VERSION ""

NS_ :

BS_:

BU_: Turbocharger OnBoardDataLogger OffBoardDiagnosticTool2 OffBoardDiagnosticTool1 FileServer ParkingBrakeController SeatControl2 FanDriveController SteeringColumnUnit CommunicationUnitRadio CommunicationUnitSatellite CommunicationUnitCellular PropulsionBatteryCharger ChassisController2 ChassisController1 EngineValveControl AuxiliaryHeater2 AuxiliaryHeater1 ClutchUnit RampControl InformationSystem1 SuspensionSystemController2 OilSensor VehicleDynamicStability ExhaustEmissionController TransmissionDisplay2 TransmissionDisplay1 ClimateControl2 WaterPumpController RearAxleSteeringController LightingOperatorControl SeatController1 IgnitionController2 IgnitionController1 TirePressureController CabController2 CabController1 PneumaticSystemController SuspensionSystemController1 HydraulicPumpController EnduranceBrakingSystem RetarderExhaustEngine2 OnBoardDiagnosticUnit HeadwayController RetarderExhaustEngine1 CabDisplay1 ManagementComputer VirtualTerminal OffVehicleGateway PowerTakeOffFront HitchControl AuxiliaryValveControl BodyController TractorTrailerBridge1 StarterSystem ElectricalSystem VehicleSecurity VehicleNavigation AerodynamicControl ElectricalChargingSystem ClimateControl1 TripRecorder InstrumentCluster SuspensionDriveAxle2 SuspensionDriveAxle1 SuspensionSteerAxle SteeringController FuelSystem CruiseControl RetarderDriveline RetarderEngine BrakesDriveAxle2 BrakesDriveAxle1 BrakesSystemController BrakesSteerAxle AxleDrive2 AxleDrive1 AxleSteering PowerTakeOff ShiftConsoleSecondary ShiftConsolePrimary Transmission2 Transmission1 Engine2 Engine1

BO_ 2365401854 BJM7: 8 Vector__XXX
 SG_ Joystick7Button9PressedStatus : 62|2@1+ (1,0) [0|3] "" Vector__XXX
 SG_ Joystick7Button10PressedStatus : 60|2@1+ (1,0) [0|3] "" Vector__XXX
 SG_ Joystick7Button11PressedStatus : 58|2@1+ (1,0) [0|3] "" Vector__XXX
 SG_ Joystick7Button12PressedStatus : 56|2@1+ (1,0) [0|3] "" Vector__XXX
 SG_ Joystick7Button5PressedStatus : 54|2@1+ (1,0) [0|3] "" Vector__XXX
 SG_ Joystick7Button6PressedStatus : 52|2@1+ (1,0) [0|3] "" Vector__XXX
 SG_ Joystick7Button7PressedStatus : 50|2@1+ (1,0) [0|3] "" Vector__XXX
 SG_ Joystick7Button8PressedStatus : 48|2@1+ (1,0) [0|3] "" Vector__XXX
 SG_ Joystick7Button1PressedStatus : 46|2@1+ (1,0) [0|3] "" Vector__XXX
 SG_ Joystick7Button2PressedStatus : 44|2@1+ (1,0) [0|3] "" Vector__XXX
 SG_ Joystick7Button3PressedStatus : 42|2@1+ (1,0) [0|3] "" Vector__XXX
 SG_ Joystick7Button4PressedStatus : 40|2@1+ (1,0) [0|3] "" Vector__XXX
 SG_ Joystick7XAxisDetentPosStatus : 38|2@1+ (1,0) [0|3] "" Vector__XXX
 SG_ Joystick7YAxisDetentPosStatus : 36|2@1+ (1,0) [0|3] "" Vector__XXX
 SG_ Joystick7YAxisPos : 22|10@1+ (1,0) [0|102] "%" Vector__XXX
 SG_ Jystck7YAxsLvrFrwrdPstvPosStatus : 20|2@1+ (1,0) [0|3] "" Vector__XXX
 SG_ Jystck7YAxsLvrBckNgtivePosStatus : 18|2@1+ (1,0) [0|3] "" Vector__XXX
 SG_ Joystick7YAxisNeutralPosStatus : 16|2@1+ (1,0) [0|3] "" Vector__XXX
 SG_ Joystick7XAxisPos : 6|10@1+ (1,0) [0|102] "%" Vector__XXX
 SG_ Jystck7XAxsLvrRghtPstvePosStatus : 4|2@1+ (1,0) [0|3] "" Vector__XXX
 SG_ Jystck7XAxsLvrLftNgtivePosStatus : 2|2@1+ (1,0) [0|3] "" Vector__XXX
 SG_ Joystick7XAxisNeutralPosStatus : 0|2@1+ (1,0) [0|3] "" Vector__XXX

BO_ 2365402366 BJM6: 8 Vector__XXX
 SG_ Joystick6Button9PressedStatus : 62|2@1+ (1,0) [0|3] "" Vector__XXX
 SG_ Joystick6Button10PressedStatus : 60|2@1+ (1,0) [0|3] "" Vector__XXX
 SG_ Joystick6Button11PressedStatus : 58|2@1+ (1,0) [0|3] "" Vector__XXX
 SG_ Joystick6Button12PressedStatus : 56|2@1+ (1,0) [0|3] "" Vector__XXX
 SG_ Joystick6Button5PressedStatus : 54|2@1+ (1,0) [0|3] "" Vector__XXX
 SG_ Joystick6Button6PressedStatus : 52|2@1+ (1,0) [0|3] "" Vector__XXX
 SG_ Joystick6Button7PressedStatus : 50|2@1+ (1,0) [0|3] "" Vector__XXX
 SG_ Joystick6Button8PressedStatus : 48|2@1+ (1,0) [0|3] "" Vector__XXX
 SG_ Joystick6Button1PressedStatus : 46|2@1+ (1,0) [0|3] "" Vector__XXX
 SG_ Joystick6Button2PressedStatus : 44|2@1+ (1,0) [0|3] "" Vector__XXX
 SG_ Joystick6Button3PressedStatus : 42|2@1+ (1,0) [0|3] "" Vector__XXX
 SG_ Joystick6Button4PressedStatus : 40|2@1+ (1,0) [0|3] "" Vector__XXX
 SG_ Joystick6XAxisDetentPosStatus : 38|2@1+ (1,0) [0|3] "" Vector__XXX
 SG_ Joystick6YAxisDetentPosStatus : 36|2@1+ (1,0) [0|3] "" Vector__XXX
 SG_ Joystick6YAxisPos : 22|10@1+ (1,0) [0|102] "%" Vector__XXX
 SG_ Jystck6YAxsLvrFrwrdPstvPosStatus : 20|2@1+ (1,0) [0|3] "" Vector__XXX
 SG_ Jystck6YAxsLvrBckNgtivePosStatus : 18|2@1+ (1,0) [0|3] "" Vector__XXX
 SG_ Joystick6YAxisNeutralPosStatus : 16|2@1+ (1,0) [0|3] "" Vector__XXX
 SG_ Joystick6XAxisPos : 6|10@1+ (1,0) [0|102] "%" Vector__XXX
 SG_ Jystck6XAxsLvrRghtPstvePosStatus : 4|2@1+ (1,0) [0|3] "" Vector__XXX
 SG_ Jystck6XAxsLvrLftNgtivePosStatus : 2|2@1+ (1,0) [0|3] "" Vector__XXX
 SG_ Joystick6XAxisNeutralPosStatus : 0|2@1+ (1,0) [0|3] "" Vector__XXX

BO_ 2365402878 BJM5: 8 Vector__XXX
 SG_ Joystick5Button9PressedStatus : 62|2@1+ (1,0) [0|3] "" Vector__XXX
 SG_ Joystick5Button10PressedStatus : 60|2@1+ (1,0) [0|3] "" Vector__XXX
 SG_ Joystick5Button11PressedStatus : 58|2@1+ (1,0) [0|3] "" Vector__XXX
 SG_ Joystick5Button12PressedStatus : 56|2@1+ (1,0) [0|3] "" Vector__XXX
 SG_ Joystick5Button5PressedStatus : 54|2@1+ (1,0) [0|3] "" Vector__XXX
 SG_ Joystick5Button6PressedStatus : 52|2@1+ (1,0) [0|3] "" Vector__XXX
 SG_ Joystick5Button7PressedStatus : 50|2@1+ (1,0) [0|3] "" Vector__XXX
 SG_ Joystick5Button8PressedStatus : 48|2@1+ (1,0) [0|3] "" Vector__XXX
 SG_ Joystick5Button1PressedStatus : 46|2@1+ (1,0) [0|3] "" Vector__XXX
 SG_ Joystick5Button2PressedStatus : 44|2@1+ (1,0) [0|3] "" Vector__XXX
 SG_ Joystick5Button3PressedStatus : 42|2@1+ (1,0) [0|3] "" Vector__XXX
 SG_ Joystick5Button4PressedStatus : 40|2@1+ (1,0) [0|3] "" Vector__XXX
 SG_ Joystick5XAxisDetentPosStatus : 38|2@1+ (1,0) [0|3] "" Vector__XXX
 SG_ Joystick5YAxisDetentPosStatus : 36|2@1+ (1,0) [0|3] "" Vector__XXX
 SG_ Joystick5YAxisPos : 22|10@1+ (1,0) [0|102] "%" Vector__XXX
 SG_ Jystck5YAxsLvrFrwrdPstvPosStatus : 20|2@1+ (1,0) [0|3] "" Vector__XXX
 SG_ Jystck5YAxsLvrBckNgtivePosStatus : 18|2@1+ (1,0) [0|3] "" Vector__XXX
 SG_ Joystick5YAxisNeutralPosStatus : 16|2@1+ (1,0) [0|3] "" Vector__XXX
 SG_ Joystick5XAxisPos : 6|10@1+ (1,0) [0|102] "%" Vector__XXX
 SG_ Jystck5XAxsLvrRghtPstvePosStatus : 4|2@1+ (1,0) [0|3] "" Vector__XXX
 SG_ Jystck5XAxsLvrLftNgtivePosStatus : 2|2@1+ (1,0) [0|3] "" Vector__XXX
 SG_ Joystick5XAxisNeutralPosStatus : 0|2@1+ (1,0) [0|3] "" Vector__XXX

BO_ 2365403390 BJM4: 8 Vector__XXX
 SG_ Joystick4Button9PressedStatus : 62|2@1+ (1,0) [0|3] "" Vector__XXX
 SG_ Joystick4Button10PressedStatus : 60|2@1+ (1,0) [0|3] "" Vector__XXX
 SG_ Joystick4Button11PressedStatus : 58|2@1+ (1,0) [0|3] "" Vector__XXX
 SG_ Joystick4Button12PressedStatus : 56|2@1+ (1,0) [0|3] "" Vector__XXX
 SG_ Joystick4Button5PressedStatus : 54|2@1+ (1,0) [0|3] "" Vector__XXX
 SG_ Joystick4Button6PressedStatus : 52|2@1+ (1,0) [0|3] "" Vector__XXX
 SG_ Joystick4Button7PressedStatus : 50|2@1+ (1,0) [0|3] "" Vector__XXX
 SG_ Joystick4Button8PressedStatus : 48|2@1+ (1,0) [0|3] "" Vector__XXX
 SG_ Joystick4Button1PressedStatus : 46|2@1+ (1,0) [0|3] "" Vector__XXX
 SG_ Joystick4Button2PressedStatus : 44|2@1+ (1,0) [0|3] "" Vector__XXX
 SG_ Joystick4Button3PressedStatus : 42|2@1+ (1,0) [0|3] "" Vector__XXX
 SG_ Joystick4Button4PressedStatus : 40|2@1+ (1,0) [0|3] "" Vector__XXX
 SG_ Joystick4XAxisDetentPosStatus : 38|2@1+ (1,0) [0|3] "" Vector__XXX
 SG_ Joystick4YAxisDetentPosStatus : 36|2@1+ (1,0) [0|3] "" Vector__XXX
 SG_ Joystick4YAxisPos : 22|10@1+ (1,0) [0|102] "%" Vector__XXX
 SG_ Jystck4YAxsLvrFrwrdPstvPosStatus : 20|2@1+ (1,0) [0|3] "" Vector__XXX
 SG_ Jystck4YAxsLvrBckNgtivePosStatus : 18|2@1+ (1,0) [0|3] "" Vector__XXX
 SG_ Joystick4YAxisNeutralPosStatus : 16|2@1+ (1,0) [0|3] "" Vector__XXX
 SG_ Joystick4XAxisPos : 6|10@1+ (1,0) [0|102] "%" Vector__XXX
 SG_ Jystck4XAxsLvrRghtPstvePosStatus : 4|2@1+ (1,0) [0|3] "" Vector__XXX
 SG_ Jystck4XAxsLvrLftNgtivePosStatus : 2|2@1+ (1,0) [0|3] "" Vector__XXX
 SG_ Joystick4XAxisNeutralPosStatus : 0|2@1+ (1,0) [0|3] "" Vector__XXX

BO_ 2365400318 BJM10: 8 Vector__XXX
 SG_ Joystick10Button9PressedStatus : 62|2@1+ (1,0) [0|3] "" Vector__XXX
 SG_ Joystick10Button10PressedStatus : 60|2@1+ (1,0) [0|3] "" Vector__XXX
 SG_ Joystick10Button11PressedStatus : 58|2@1+ (1,0) [0|3] "" Vector__XXX
 SG_ Joystick10Button12PressedStatus : 56|2@1+ (1,0) [0|3] "" Vector__XXX
 SG_ Joystick10Button5PressedStatus : 54|2@1+ (1,0) [0|3] "" Vector__XXX
 SG_ Joystick10Button6PressedStatus : 52|2@1+ (1,0) [0|3] "" Vector__XXX
 SG_ Joystick10Button7PressedStatus : 50|2@1+ (1,0) [0|3] "" Vector__XXX
 SG_ Joystick10Button8PressedStatus : 48|2@1+ (1,0) [0|3] "" Vector__XXX
 SG_ Joystick10Button1PressedStatus : 46|2@1+ (1,0) [0|3] "" Vector__XXX
 SG_ Joystick10Button2PressedStatus : 44|2@1+ (1,0) [0|3] "" Vector__XXX
 SG_ Joystick10Button3PressedStatus : 42|2@1+ (1,0) [0|3] "" Vector__XXX
 SG_ Joystick10Button4PressedStatus : 40|2@1+ (1,0) [0|3] "" Vector__XXX
 SG_ Joystick10XAxisDetentPosStatus : 38|2@1+ (1,0) [0|3] "" Vector__XXX
 SG_ Joystick10YAxisDetentPosStatus : 36|2@1+ (1,0) [0|3] "" Vector__XXX
 SG_ Joystick10YAxisPos : 22|10@1+ (1,0) [0|102] "%" Vector__XXX
 SG_ Jystck10YAxsLvrFrwrdPstvPsStatus : 20|2@1+ (1,0) [0|3] "" Vector__XXX
 SG_ Jystck10YAxsLvrBckNgtvePosStatus : 18|2@1+ (1,0) [0|3] "" Vector__XXX
 SG_ Joystick10YAxisNeutralPosStatus : 16|2@1+ (1,0) [0|3] "" Vector__XXX
 SG_ Joystick10XAxisPos : 6|10@1+ (1,0) [0|102] "%" Vector__XXX
 SG_ Jystck10XAxsLvrRghtPstvPosStatus : 4|2@1+ (1,0) [0|3] "" Vector__XXX
 SG_ Jystck10XAxsLvrLftNgtvePosStatus : 2|2@1+ (1,0) [0|3] "" Vector__XXX
 SG_ Joystick10XAxisNeutralPosStatus : 0|2@1+ (1,0) [0|3] "" Vector__XXX

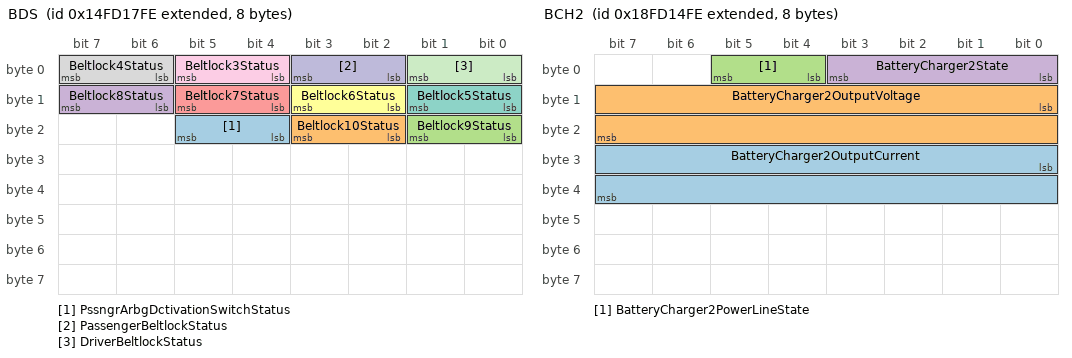
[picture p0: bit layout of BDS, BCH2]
BO_ 2499614718 BDS: 8 Vector__XXX
 SG_ PssngrArbgDctivationSwitchStatus : 20|2@1+ (1,0) [0|3] "" Vector__XXX
 SG_ Beltlock10Status : 18|2@1+ (1,0) [0|3] "" Vector__XXX
 SG_ Beltlock9Status : 16|2@1+ (1,0) [0|3] "" Vector__XXX
 SG_ Beltlock8Status : 14|2@1+ (1,0) [0|3] "" Vector__XXX
 SG_ Beltlock7Status : 12|2@1+ (1,0) [0|3] "" Vector__XXX
 SG_ Beltlock6Status : 10|2@1+ (1,0) [0|3] "" Vector__XXX
 SG_ Beltlock5Status : 8|2@1+ (1,0) [0|3] "" Vector__XXX
 SG_ Beltlock4Status : 6|2@1+ (1,0) [0|3] "" Vector__XXX
 SG_ Beltlock3Status : 4|2@1+ (1,0) [0|3] "" Vector__XXX
 SG_ PassengerBeltlockStatus : 2|2@1+ (1,0) [0|3] "" Vector__XXX
 SG_ DriverBeltlockStatus : 0|2@1+ (1,0) [0|3] "" Vector__XXX

BO_ 2566722814 BCH2: 8 Vector__XXX
 SG_ BatteryCharger2OutputCurrent : 24|16@1+ (0.05,-1600) [-1600|1612.75] "A" Vector__XXX
 SG_ BatteryCharger2OutputVoltage : 8|16@1+ (0.05,0) [0|3212.75] "V" Vector__XXX
 SG_ BatteryCharger2PowerLineState : 4|2@1+ (1,0) [0|3] "" Vector__XXX
 SG_ BatteryCharger2State : 0|4@1+ (1,0) [0|15] "" Vector__XXX

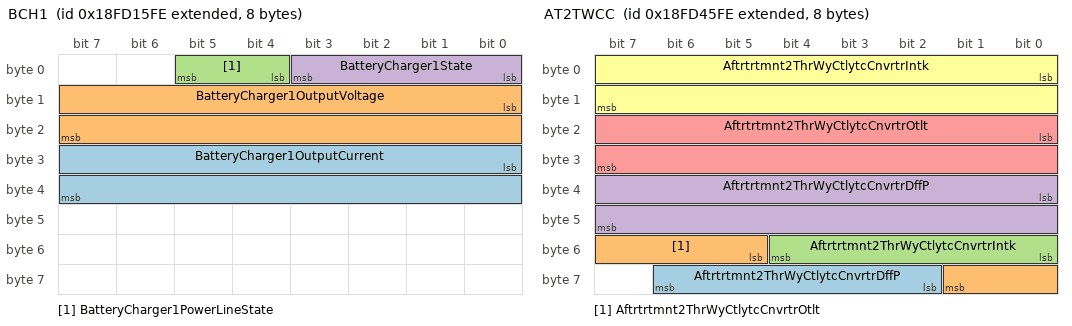
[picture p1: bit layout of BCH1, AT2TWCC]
BO_ 2566723070 BCH1: 8 Vector__XXX
 SG_ BatteryCharger1OutputCurrent : 24|16@1+ (0.05,-1600) [-1600|1612.75] "A" Vector__XXX
 SG_ BatteryCharger1OutputVoltage : 8|16@1+ (0.05,0) [0|3212.75] "V" Vector__XXX
 SG_ BatteryCharger1PowerLineState : 4|2@1+ (1,0) [0|3] "" Vector__XXX
 SG_ BatteryCharger1State : 0|4@1+ (1,0) [0|15] "" Vector__XXX

BO_ 2566725118 ATDT2: 8 Vector__XXX
 SG_ Aftrtrtmnt2ThrWyCtlystDffGasTemp : 16|16@1+ (0.03125,-273) [-273|1734.96875] "deg C" Vector__XXX
 SG_ Aftrtrtmnt1ThrWyCtlystDffGasTemp : 0|16@1+ (0.03125,-273) [-273|1734.96875] "deg C" Vector__XXX

BO_ 2566725374 ATDT1: 8 Vector__XXX
 SG_ Aftrtrtmnt2GsOxdtnCtlystDffGsTmp : 16|16@1+ (0.03125,-273) [-273|1734.96875] "deg C" Vector__XXX
 SG_ Aftrtrtmnt1GsOxdtnCtlystDffGsTmp : 0|16@1+ (0.03125,-273) [-273|1734.96875] "deg C" Vector__XXX

BO_ 2566712830 AT2WUDOC: 8 Vector__XXX
 SG_ Aftrtrtmnt2WrmUpDslOxdtnCtlystOt : 16|16@1+ (0.03125,-273) [-273|1734.96875] "deg C" Vector__XXX
 SG_ Aftrtrtmnt2WrmUpDslOxdtnCtlystIn : 0|16@1+ (0.03125,-273) [-273|1734.96875] "deg C" Vector__XXX

BO_ 2566735358 AT2TWCC: 8 Vector__XXX
 SG_ Aftrtrtmnt2ThrWyCtlytcCnvrtrDffP : 58|5@1+ (1,0) [0|31] "" Vector__XXX
 SG_ Aftrtrtmnt2ThrWyCtlytcCnvrtrOtlt : 53|5@1+ (1,0) [0|31] "" Vector__XXX
 SG_ Aftrtrtmnt2ThrWyCtlytcCnvrtrIntk : 48|5@1+ (1,0) [0|31] "" Vector__XXX
 SG_ Aftrtrtmnt2ThrWyCtlytcCnvrtrDffP : 32|16@1+ (0.1,0) [0|6425.5] "kPa" Vector__XXX
 SG_ Aftrtrtmnt2ThrWyCtlytcCnvrtrOtlt : 16|16@1+ (0.03125,-273) [-273|1734.96875] "deg C" Vector__XXX
 SG_ Aftrtrtmnt2ThrWyCtlytcCnvrtrIntk : 0|16@1+ (0.03125,-273) [-273|1734.96875] "deg C" Vector__XXX

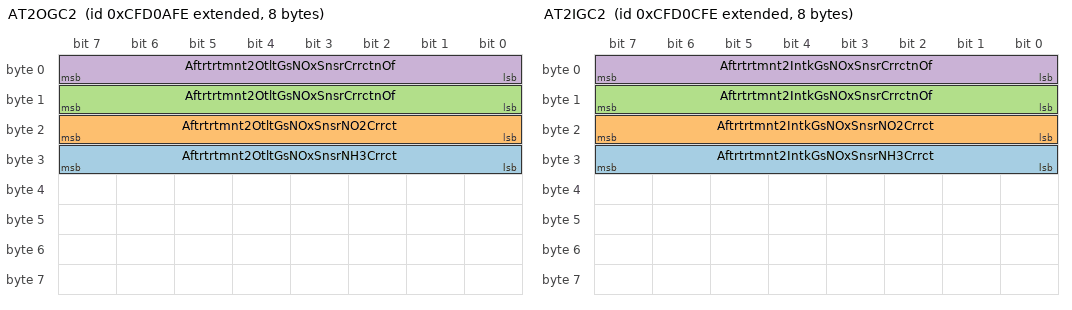
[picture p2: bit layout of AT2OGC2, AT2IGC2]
BO_ 2365393662 AT2OGC2: 8 Vector__XXX
 SG_ Aftrtrtmnt2OtltGsNOxSnsrNH3Crrct : 24|8@1+ (0.5,0) [0|125] "%" Vector__XXX
 SG_ Aftrtrtmnt2OtltGsNOxSnsrNO2Crrct : 16|8@1+ (0.5,0) [0|125] "%" Vector__XXX
 SG_ Aftrtrtmnt2OtltGsNOxSnsrCrrctnOf : 8|8@1+ (0.5,0) [0|125] "%/bar" Vector__XXX
 SG_ Aftrtrtmnt2OtltGsNOxSnsrCrrctnOf : 0|8@1+ (0.5,0) [0|125] "%/bar" Vector__XXX

BO_ 2365393918 AT2OGC1: 8 Vector__XXX
 SG_ Aftrtrtmnt2OtltGsNOxSnsrNwPrtDvt : 32|8@1+ (1,-125) [-125|125] "ppm" Vector__XXX
 SG_ Aftrtrtmnt2OtltGsNOxSnsrNwPrtDvt : 16|16@1+ (0.003112598241382,-100) [-100|100] "%" Vector__XXX
 SG_ Aftrtrtmnt2OtltGsNOxSnsrHtrRatio : 0|16@1+ (0.001,0) [0|64.255] "" Vector__XXX

BO_ 2365394174 AT2IGC2: 8 Vector__XXX
 SG_ Aftrtrtmnt2IntkGsNOxSnsrNH3Crrct : 24|8@1+ (0.5,0) [0|125] "%" Vector__XXX
 SG_ Aftrtrtmnt2IntkGsNOxSnsrNO2Crrct : 16|8@1+ (0.5,0) [0|125] "%" Vector__XXX
 SG_ Aftrtrtmnt2IntkGsNOxSnsrCrrctnOf : 8|8@1+ (0.5,0) [0|125] "%/bar" Vector__XXX
 SG_ Aftrtrtmnt2IntkGsNOxSnsrCrrctnOf : 0|8@1+ (0.5,0) [0|125] "%/bar" Vector__XXX

BO_ 2365394430 AT2IGC1: 8 Vector__XXX
 SG_ Aftrtrtmnt2IntkGsNOxSnsrNwPrtDvt : 32|8@1+ (1,-125) [-125|125] "ppm" Vector__XXX
 SG_ Aftrtrtmnt2IntkGsNOxSnsrNwPrtDvt : 16|16@1+ (0.003112598241382,-100) [-100|100] "%" Vector__XXX
 SG_ Aftrtrtmnt2IntkGsNOxSnsrHtrRatio : 0|16@1+ (0.001,0) [0|64.255] "" Vector__XXX

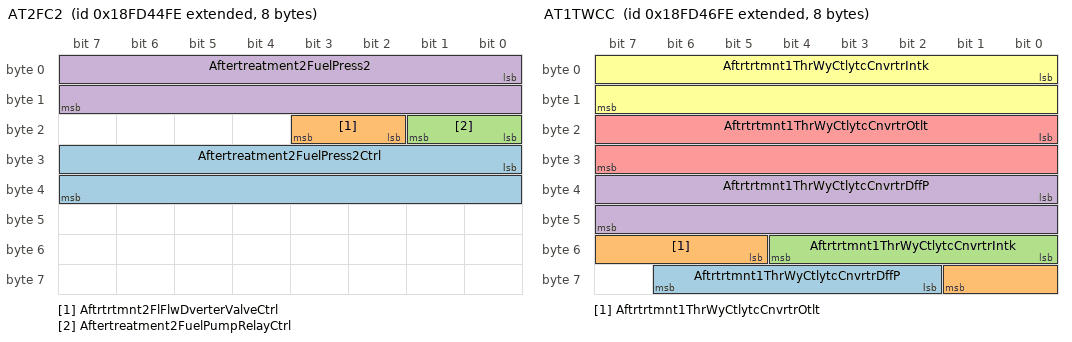
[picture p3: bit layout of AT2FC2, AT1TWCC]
BO_ 2566735102 AT2FC2: 8 Vector__XXX
 SG_ Aftertreatment2FuelPress2Ctrl : 24|16@1+ (1,0) [0|160.6375] "%" Vector__XXX
 SG_ Aftrtrtmnt2FlFlwDverterValveCtrl : 18|2@1+ (1,0) [0|3] "" Vector__XXX
 SG_ Aftertreatment2FuelPumpRelayCtrl : 16|2@1+ (1,0) [0|3] "" Vector__XXX
 SG_ Aftertreatment2FuelPress2 : 0|16@1+ (0.1,0) [0|6425.5] "kPa" Vector__XXX

BO_ 2157313790 AT2DPFSSC: 8 Vector__XXX
 SG_ Aftrtrtmnt2DslPrtcltFltrStStndrd : 16|16@1+ (1,0) [0|160.6375] "%" Vector__XXX
 SG_ Aftrtrtmnt2DslPrtcltFltrStMnClbO : 0|16@1+ (1,0) [0|160.6375] "%" Vector__XXX

BO_ 2566724350 AT1WUDOC: 8 Vector__XXX
 SG_ Aftrtrtmnt1WrmUpDslOxdtnCtlystOt : 16|16@1+ (0.03125,-273) [-273|1734.96875] "deg C" Vector__XXX
 SG_ Aftrtrtmnt1WrmUpDslOxdtnCtlystIn : 0|16@1+ (0.03125,-273) [-273|1734.96875] "deg C" Vector__XXX

BO_ 2566735614 AT1TWCC: 8 Vector__XXX
 SG_ Aftrtrtmnt1ThrWyCtlytcCnvrtrDffP : 58|5@1+ (1,0) [0|31] "" Vector__XXX
 SG_ Aftrtrtmnt1ThrWyCtlytcCnvrtrOtlt : 53|5@1+ (1,0) [0|31] "" Vector__XXX
 SG_ Aftrtrtmnt1ThrWyCtlytcCnvrtrIntk : 48|5@1+ (1,0) [0|31] "" Vector__XXX
 SG_ Aftrtrtmnt1ThrWyCtlytcCnvrtrDffP : 32|16@1+ (0.1,0) [0|6425.5] "kPa" Vector__XXX
 SG_ Aftrtrtmnt1ThrWyCtlytcCnvrtrOtlt : 16|16@1+ (0.03125,-273) [-273|1734.96875] "deg C" Vector__XXX
 SG_ Aftrtrtmnt1ThrWyCtlytcCnvrtrIntk : 0|16@1+ (0.03125,-273) [-273|1734.96875] "deg C" Vector__XXX

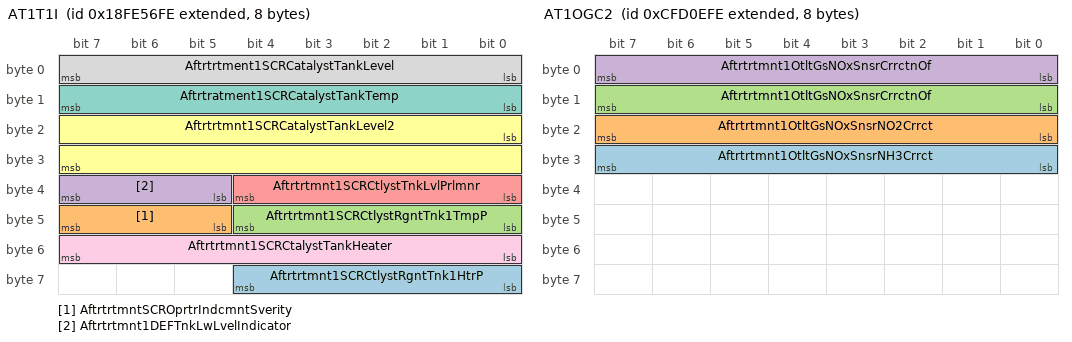
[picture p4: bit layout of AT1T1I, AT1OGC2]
BO_ 2566805246 AT1T1I: 8 Vector__XXX
 SG_ Aftrtrtmnt1SCRCtlystRgntTnk1HtrP : 56|5@1+ (1,0) [0|31] "" Vector__XXX
 SG_ AftrtrtmntSCROprtrIndcmntSverity : 45|3@1+ (1,0) [0|7] "" Vector__XXX
 SG_ Aftrtrtmnt1SCRCtlystRgntTnk1TmpP : 40|5@1+ (1,0) [0|31] "" Vector__XXX
 SG_ Aftrtrtmnt1DEFTnkLwLvelIndicator : 37|3@1+ (1,0) [0|7] "" Vector__XXX
 SG_ Aftrtrtmnt1SCRCtlystTnkLvlPrlmnr : 32|5@1+ (1,0) [0|31] "" Vector__XXX
 SG_ Aftrtrtmnt1SCRCatalystTankLevel2 : 16|16@1+ (0.1,0) [0|6425.5] "mm" Vector__XXX
 SG_ Aftrtratment1SCRCatalystTankTemp : 8|8@1+ (1,-40) [-40|210] "deg C" Vector__XXX
 SG_ Aftrtrtment1SCRCatalystTankLevel : 0|8@1+ (0.4,0) [0|100] "%" Vector__XXX
 SG_ Aftrtrtmnt1SCRCtalystTankHeater : 48|8@1+ (0.4,0) [0|100] "%" Vector__XXX

BO_ 2365394686 AT1OGC2: 8 Vector__XXX
 SG_ Aftrtrtmnt1OtltGsNOxSnsrNH3Crrct : 24|8@1+ (0.5,0) [0|125] "%" Vector__XXX
 SG_ Aftrtrtmnt1OtltGsNOxSnsrNO2Crrct : 16|8@1+ (0.5,0) [0|125] "%" Vector__XXX
 SG_ Aftrtrtmnt1OtltGsNOxSnsrCrrctnOf : 8|8@1+ (0.5,0) [0|125] "%/bar" Vector__XXX
 SG_ Aftrtrtmnt1OtltGsNOxSnsrCrrctnOf : 0|8@1+ (0.5,0) [0|125] "%/bar" Vector__XXX

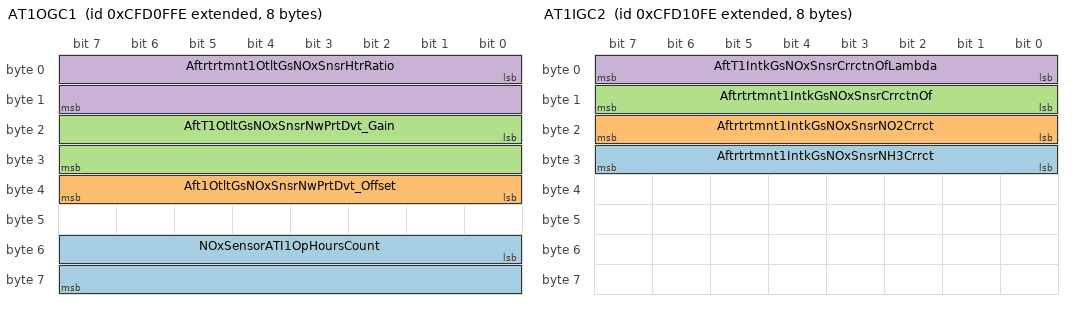
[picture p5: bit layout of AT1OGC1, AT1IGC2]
BO_ 2365394942 AT1OGC1: 8 Vector__XXX
 SG_ NOxSensorATI1OpHoursCount : 48|16@1- (1,0) [0|64255] "" Vector__XXX
 SG_ Aft1OtltGsNOxSnsrNwPrtDvt_Offset : 32|8@1+ (1,-125) [-125|125] "ppm" Vector__XXX
 SG_ AftT1OtltGsNOxSnsrNwPrtDvt_Gain : 16|16@1+ (0.1,-100) [-100|100] "%" Vector__XXX
 SG_ Aftrtrtmnt1OtltGsNOxSnsrHtrRatio : 0|16@1+ (0.001,0) [0|64.255] "" Vector__XXX

BO_ 2365395198 AT1IGC2: 8 Vector__XXX
 SG_ Aftrtrtmnt1IntkGsNOxSnsrNH3Crrct : 24|8@1+ (0.5,0) [0|125] "%" Vector__XXX
 SG_ Aftrtrtmnt1IntkGsNOxSnsrNO2Crrct : 16|8@1+ (0.5,0) [0|125] "%" Vector__XXX
 SG_ Aftrtrtmnt1IntkGsNOxSnsrCrrctnOf : 8|8@1+ (0.5,0) [0|125] "%/bar" Vector__XXX
 SG_ AftT1IntkGsNOxSnsrCrrctnOfLambda : 0|8@1+ (0.5,0) [0|125] "%/bar" Vector__XXX

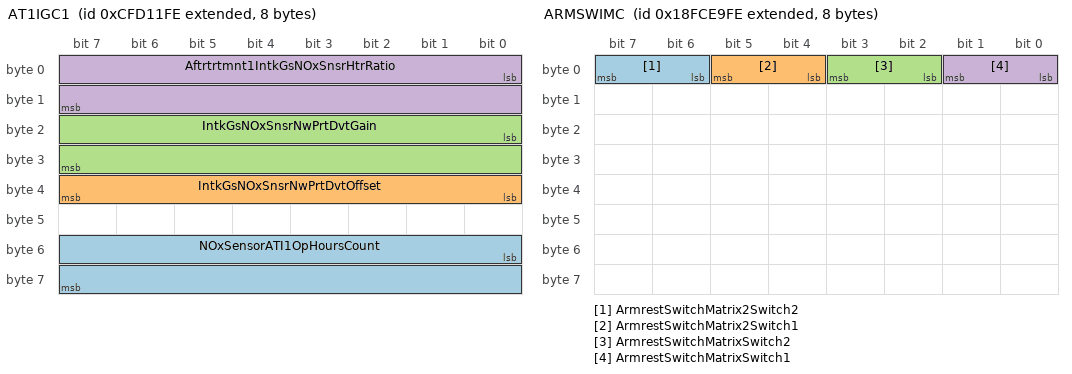
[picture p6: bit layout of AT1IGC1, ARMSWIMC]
BO_ 2365395454 AT1IGC1: 8 Vector__XXX
 SG_ NOxSensorATI1OpHoursCount : 48|16@1- (1,0) [0|64255] "" Vector__XXX
 SG_ IntkGsNOxSnsrNwPrtDvtOffset : 32|8@1+ (1,-125) [-125|125] "ppm" Vector__XXX
 SG_ IntkGsNOxSnsrNwPrtDvtGain : 16|16@1+ (0.003112598241382,-100) [-100|100] "%" Vector__XXX
 SG_ Aftrtrtmnt1IntkGsNOxSnsrHtrRatio : 0|16@1+ (0.001,0) [0|64.255] "" Vector__XXX

BO_ 2157248254 AT1DPFSSC: 8 Vector__XXX
 SG_ Aftrtrtmnt1DslPrtcltFltrStStndrd : 16|16@1+ (1,0) [0|160.6375] "%" Vector__XXX
 SG_ Aftrtrtmnt1DslPrtcltFltrStMnClbO : 0|16@1+ (1,0) [0|160.6375] "%" Vector__XXX

BO_ 2566711806 ARMSWIMC: 8 Vector__XXX
 SG_ ArmrestSwitchMatrix2Switch2 : 6|2@1+ (1,0) [0|3] "" Vector__XXX
 SG_ ArmrestSwitchMatrix2Switch1 : 4|2@1+ (1,0) [0|3] "" Vector__XXX
 SG_ ArmrestSwitchMatrixSwitch2 : 2|2@1+ (1,0) [0|3] "" Vector__XXX
 SG_ ArmrestSwitchMatrixSwitch1 : 0|2@1+ (1,0) [0|3] "" Vector__XXX

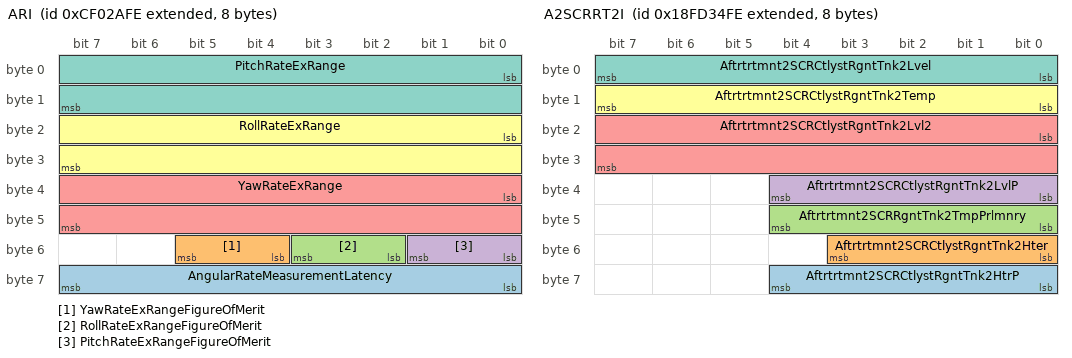
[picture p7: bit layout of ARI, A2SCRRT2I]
BO_ 2364549886 ARI: 8 Vector__XXX
 SG_ AngularRateMeasurementLatency : 56|8@1+ (0.5,0) [0|125] "ms" Vector__XXX
 SG_ YawRateExRangeFigureOfMerit : 52|2@1+ (1,0) [0|3] "" Vector__XXX
 SG_ RollRateExRangeFigureOfMerit : 50|2@1+ (1,0) [0|3] "" Vector__XXX
 SG_ PitchRateExRangeFigureOfMerit : 48|2@1+ (1,0) [0|3] "" Vector__XXX
 SG_ YawRateExRange : 32|16@1+ (0.0077969340907322,-250) [-250|250.992] "deg/sec" Vector__XXX
 SG_ RollRateExRange : 16|16@1+ (0.0077969340907322,-250) [-250|250.992] "deg/sec" Vector__XXX
 SG_ PitchRateExRange : 0|16@1+ (0.0077969340907322,-250) [-250|250.992] "deg/sec" Vector__XXX

BO_ 2566712318 AFT2NAI: 8 Vector__XXX
 SG_ Aftrtrtmnt2NOxAdsrbrDSOxRgnrtnSt : 2|2@1+ (1,0) [0|3] "" Vector__XXX
 SG_ Aftrtrtmnt2NOxAdsrbrDNOxRgnrtnSt : 0|2@1+ (1,0) [0|3] "" Vector__XXX

BO_ 2566712574 AFT1NAI: 8 Vector__XXX
 SG_ Aftrtrtmnt1NOxAdsrbrDSOxRgnrtnSt : 2|2@1+ (1,0) [0|3] "" Vector__XXX
 SG_ Aftrtrtmnt1NOxAdsrbrDNOxRgnrtnSt : 0|2@1+ (1,0) [0|3] "" Vector__XXX

BO_ 2164078590 A2SCRSI: 8 Vector__XXX
 SG_ Aftrtrtmnt2SCRCtlystCnvrsnEffcnc : 32|8@1+ (0.4,0) [0|100] "%" Vector__XXX
 SG_ Aftrtrtmnt2SCRCmmnddCtlystRgntCn : 16|16@1+ (1,0) [0|3212.75] "L/h" Vector__XXX
 SG_ Aftrtrtmnt2SCRAvrgCtlystRgntCnsm : 0|16@1+ (0.05,0) [0|3212.75] "L/h" Vector__XXX

BO_ 2566731006 A2SCRRT2I: 8 Vector__XXX
 SG_ Aftrtrtmnt2SCRCtlystRgntTnk2HtrP : 56|5@1+ (1,0) [0|31] "" Vector__XXX
 SG_ Aftrtrtmnt2SCRCtlystRgntTnk2Hter : 48|4@1+ (1,0) [0|15] "" Vector__XXX
 SG_ Aftrtrtmnt2SCRRgntTnk2TmpPrlmnry : 40|5@1+ (1,0) [0|31] "" Vector__XXX
 SG_ Aftrtrtmnt2SCRCtlystRgntTnk2LvlP : 32|5@1+ (1,0) [0|31] "" Vector__XXX
 SG_ Aftrtrtmnt2SCRCtlystRgntTnk2Lvl2 : 16|16@1+ (1,0) [0|6425.5] "mm" Vector__XXX
 SG_ Aftrtrtmnt2SCRCtlystRgntTnk2Temp : 8|8@1+ (1,-40) [-40|210] "deg C" Vector__XXX
 SG_ Aftrtrtmnt2SCRCtlystRgntTnk2Lvel : 0|8@1+ (0.4,0) [0|100] "%" Vector__XXX

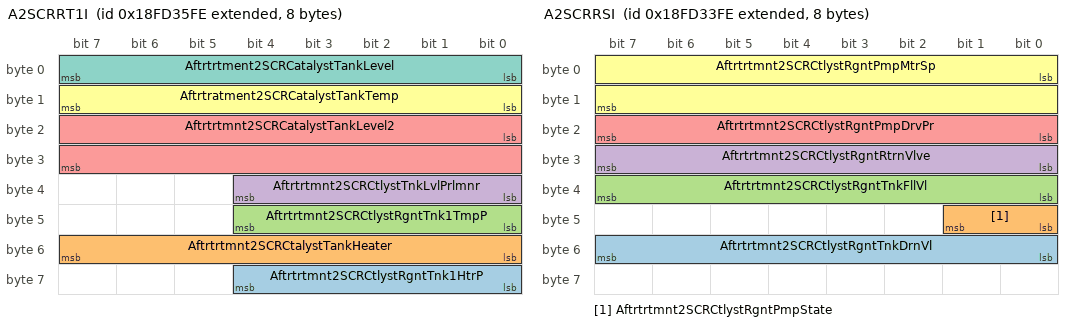
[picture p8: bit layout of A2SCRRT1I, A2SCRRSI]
BO_ 2566731262 A2SCRRT1I: 8 Vector__XXX
 SG_ Aftrtrtmnt2SCRCtlystRgntTnk1HtrP : 56|5@1+ (1,0) [0|31] "" Vector__XXX
 SG_ Aftrtrtmnt2SCRCtalystTankHeater : 48|8@1+ (0.4,0) [0|100] "%" Vector__XXX
 SG_ Aftrtrtmnt2SCRCtlystRgntTnk1TmpP : 40|5@1+ (1,0) [0|31] "" Vector__XXX
 SG_ Aftrtrtmnt2SCRCtlystTnkLvlPrlmnr : 32|5@1+ (1,0) [0|31] "" Vector__XXX
 SG_ Aftrtrtmnt2SCRCatalystTankLevel2 : 16|16@1+ (0.1,0) [0|6425.5] "mm" Vector__XXX
 SG_ Aftrtratment2SCRCatalystTankTemp : 8|8@1+ (1,-40) [-40|210] "deg C" Vector__XXX
 SG_ Aftrtrtment2SCRCatalystTankLevel : 0|8@1+ (0.4,0) [0|100] "%" Vector__XXX

BO_ 2566730750 A2SCRRSI: 8 Vector__XXX
 SG_ Aftrtrtmnt2SCRCtlystRgntTnkDrnVl : 48|8@1+ (1,0) [0|100] "%" Vector__XXX
 SG_ Aftrtrtmnt2SCRCtlystRgntPmpState : 40|2@1+ (1,0) [0|3] "" Vector__XXX
 SG_ Aftrtrtmnt2SCRCtlystRgntTnkFllVl : 32|8@1+ (1,0) [0|100] "%" Vector__XXX
 SG_ Aftrtrtmnt2SCRCtlystRgntRtrnVlve : 24|8@1+ (1,0) [0|100] "%" Vector__XXX
 SG_ Aftrtrtmnt2SCRCtlystRgntPmpDrvPr : 16|8@1+ (1,0) [0|100] "%" Vector__XXX
 SG_ Aftrtrtmnt2SCRCtlystRgntPmpMtrSp : 0|16@1+ (0.5,0) [0|32127.5] "rpm" Vector__XXX

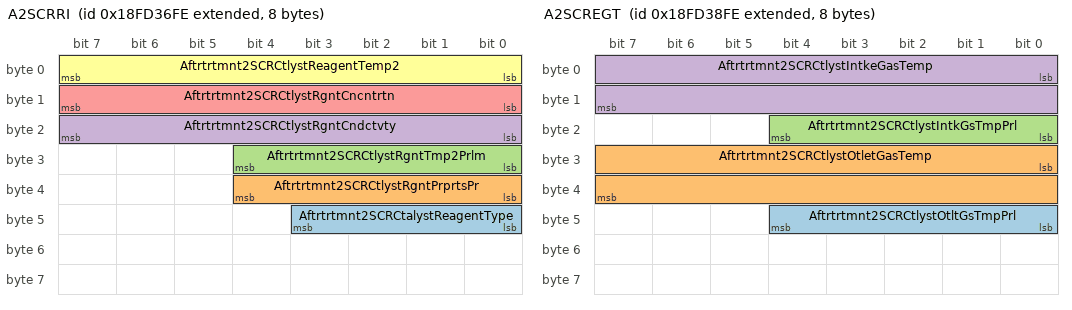
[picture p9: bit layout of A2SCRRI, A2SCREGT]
BO_ 2566731518 A2SCRRI: 8 Vector__XXX
 SG_ Aftrtrtmnt2SCRCtalystReagentType : 40|4@1+ (1,0) [0|15] "" Vector__XXX
 SG_ Aftrtrtmnt2SCRCtlystRgntPrprtsPr : 32|5@1+ (1,0) [0|31] "" Vector__XXX
 SG_ Aftrtrtmnt2SCRCtlystRgntTmp2Prlm : 24|5@1+ (1,0) [0|31] "" Vector__XXX
 SG_ Aftrtrtmnt2SCRCtlystRgntCndctvty : 16|8@1+ (5,0) [0|1250] "microSiemens/mm" Vector__XXX
 SG_ Aftrtrtmnt2SCRCtlystRgntCncntrtn : 8|8@1+ (0.25,0) [0|62.5] "%" Vector__XXX
 SG_ Aftrtrtmnt2SCRCtlystReagentTemp2 : 0|8@1+ (1,-40) [-40|210] "deg C" Vector__XXX

BO_ 2566732030 A2SCREGT: 8 Vector__XXX
 SG_ Aftrtrtmnt2SCRCtlystOtltGsTmpPrl : 40|5@1+ (1,0) [0|31] "" Vector__XXX
 SG_ Aftrtrtmnt2SCRCtlystOtletGasTemp : 24|16@1+ (0.03125,-273) [-273|1734.96875] "deg C" Vector__XXX
 SG_ Aftrtrtmnt2SCRCtlystIntkGsTmpPrl : 16|5@1+ (1,0) [0|31] "" Vector__XXX
 SG_ Aftrtrtmnt2SCRCtlystIntkeGasTemp : 0|16@1+ (0.03125,-273) [-273|1734.96875] "deg C" Vector__XXX

BO_ 2566732286 A2SCREGP: 8 Vector__XXX
 SG_ SCRCtlystExhstGsDffPr_PerlimFMI : 16|5@1+ (1,0) [0|31] "" Vector__XXX
 SG_ Aftrtrtmnt2SCRCtlystExhstGsDffPr : 0|16@1+ (0.1,0) [0|6425.5] "kPa" Vector__XXX

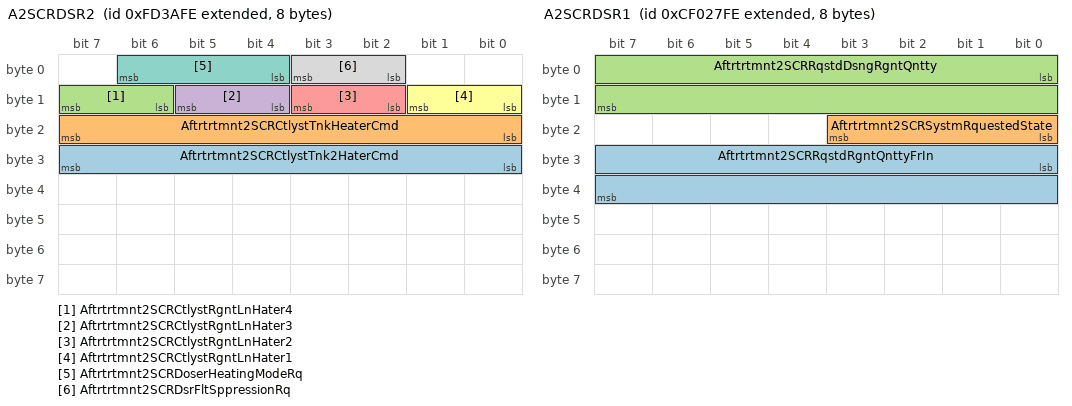
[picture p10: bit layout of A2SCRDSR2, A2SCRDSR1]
BO_ 2164079358 A2SCRDSR2: 8 Vector__XXX
 SG_ Aftrtrtmnt2SCRCtlystTnk2HaterCmd : 24|8@1+ (1,0) [0|100] "%" Vector__XXX
 SG_ Aftrtrtmnt2SCRCtlystTnkHeaterCmd : 16|8@1+ (1,0) [0|100] "%" Vector__XXX
 SG_ Aftrtrtmnt2SCRCtlystRgntLnHater4 : 14|2@1+ (1,0) [0|3] "" Vector__XXX
 SG_ Aftrtrtmnt2SCRCtlystRgntLnHater3 : 12|2@1+ (1,0) [0|3] "" Vector__XXX
 SG_ Aftrtrtmnt2SCRCtlystRgntLnHater2 : 10|2@1+ (1,0) [0|3] "" Vector__XXX
 SG_ Aftrtrtmnt2SCRCtlystRgntLnHater1 : 8|2@1+ (1,0) [0|3] "" Vector__XXX
 SG_ Aftrtrtmnt2SCRDoserHeatingModeRq : 4|3@1+ (1,0) [0|7] "" Vector__XXX
 SG_ Aftrtrtmnt2SCRDsrFltSppressionRq : 2|2@1+ (1,0) [0|3] "" Vector__XXX

BO_ 2364549118 A2SCRDSR1: 8 Vector__XXX
 SG_ Aftrtrtmnt2SCRRqstdRgntQnttyFrIn : 24|16@1+ (0.1,0) [0|6425.5] "g" Vector__XXX
 SG_ Aftrtrtmnt2SCRSystmRquestedState : 16|4@1+ (1,0) [0|15] "" Vector__XXX
 SG_ Aftrtrtmnt2SCRRqstdDsngRgntQntty : 0|16@1+ (0.3,0) [0|19276.5] "g/h" Vector__XXX

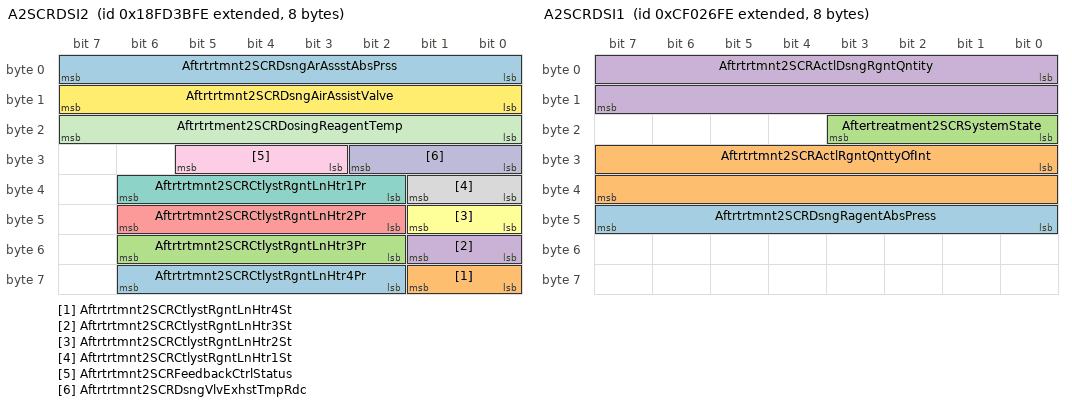
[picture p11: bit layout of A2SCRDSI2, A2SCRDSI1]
BO_ 2566732798 A2SCRDSI2: 8 Vector__XXX
 SG_ Aftrtrtmnt2SCRCtlystRgntLnHtr4Pr : 58|5@1+ (1,0) [0|31] "" Vector__XXX
 SG_ Aftrtrtmnt2SCRCtlystRgntLnHtr4St : 56|2@1+ (1,0) [0|3] "" Vector__XXX
 SG_ Aftrtrtmnt2SCRCtlystRgntLnHtr3Pr : 50|5@1+ (1,0) [0|31] "" Vector__XXX
 SG_ Aftrtrtmnt2SCRCtlystRgntLnHtr3St : 48|2@1+ (1,0) [0|3] "" Vector__XXX
 SG_ Aftrtrtmnt2SCRCtlystRgntLnHtr2Pr : 42|5@1+ (1,0) [0|31] "" Vector__XXX
 SG_ Aftrtrtmnt2SCRCtlystRgntLnHtr2St : 40|2@1+ (1,0) [0|3] "" Vector__XXX
 SG_ Aftrtrtmnt2SCRCtlystRgntLnHtr1Pr : 34|5@1+ (1,0) [0|31] "" Vector__XXX
 SG_ Aftrtrtmnt2SCRCtlystRgntLnHtr1St : 32|2@1+ (1,0) [0|3] "" Vector__XXX
 SG_ Aftrtrtmnt2SCRFeedbackCtrlStatus : 27|3@1+ (1,0) [0|7] "" Vector__XXX
 SG_ Aftrtrtmnt2SCRDsngVlvExhstTmpRdc : 24|3@1+ (1,0) [0|7] "" Vector__XXX
 SG_ Aftrtrtment2SCRDosingReagentTemp : 16|8@1+ (1,-40) [-40|210] "deg C" Vector__XXX
 SG_ Aftrtrtmnt2SCRDsngAirAssistValve : 8|8@1+ (1,0) [0|100] "%" Vector__XXX
 SG_ Aftrtrtmnt2SCRDsngArAssstAbsPrss : 0|8@1+ (8,0) [0|2000] "kPa" Vector__XXX

BO_ 2364548862 A2SCRDSI1: 8 Vector__XXX
 SG_ Aftrtrtmnt2SCRDsngRagentAbsPress : 40|8@1+ (8,0) [0|2000] "kPa" Vector__XXX
 SG_ Aftrtrtmnt2SCRActlRgntQnttyOfInt : 24|16@1+ (0.1,0) [0|6425.5] "g" Vector__XXX
 SG_ Aftertreatment2SCRSystemState : 16|4@1+ (1,0) [0|15] "" Vector__XXX
 SG_ Aftrtrtmnt2SCRActlDsngRgntQntity : 0|16@1+ (0.3,0) [0|19276.5] "g/h" Vector__XXX

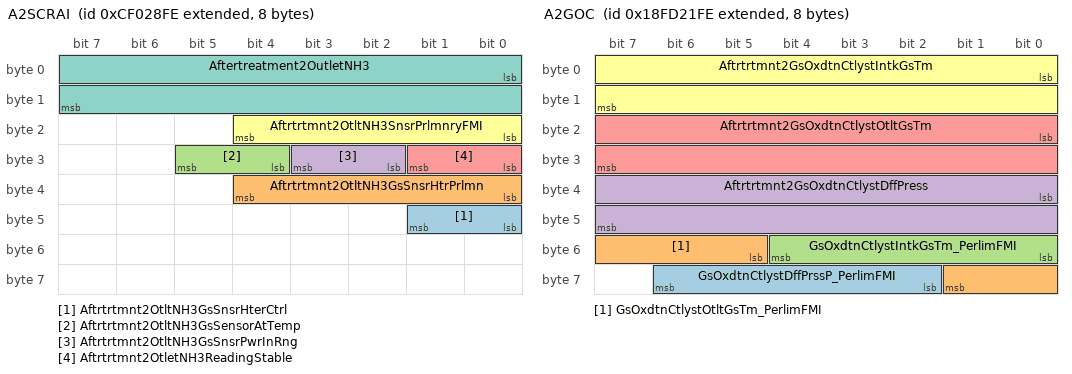
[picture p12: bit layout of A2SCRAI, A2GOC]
BO_ 2364549374 A2SCRAI: 8 Vector__XXX
 SG_ Aftrtrtmnt2OtltNH3GsSnsrHterCtrl : 40|2@1+ (1,0) [0|3] "" Vector__XXX
 SG_ Aftrtrtmnt2OtltNH3GsSnsrHtrPrlmn : 32|5@1+ (1,0) [0|31] "" Vector__XXX
 SG_ Aftrtrtmnt2OtltNH3GsSensorAtTemp : 28|2@1+ (1,0) [0|3] "" Vector__XXX
 SG_ Aftrtrtmnt2OtltNH3GsSnsrPwrInRng : 26|2@1+ (1,0) [0|3] "" Vector__XXX
 SG_ Aftrtrtmnt2OtletNH3ReadingStable : 24|2@1+ (1,0) [0|3] "" Vector__XXX
 SG_ Aftrtrtmnt2OtltNH3SnsrPrlmnryFMI : 16|5@1+ (1,0) [0|31] "" Vector__XXX
 SG_ Aftertreatment2OutletNH3 : 0|16@1+ (0.3,0) [0|19276.5] "g/h" Vector__XXX

BO_ 2566726142 A2GOC: 8 Vector__XXX
 SG_ GsOxdtnCtlystDffPrssP_PerlimFMI : 58|5@1+ (1,0) [0|31] "" Vector__XXX
 SG_ GsOxdtnCtlystOtltGsTm_PerlimFMI : 53|5@1+ (1,0) [0|31] "" Vector__XXX
 SG_ GsOxdtnCtlystIntkGsTm_PerlimFMI : 48|5@1+ (1,0) [0|31] "" Vector__XXX
 SG_ Aftrtrtmnt2GsOxdtnCtlystDffPress : 32|16@1+ (0.1,0) [0|6425.5] "kPa" Vector__XXX
 SG_ Aftrtrtmnt2GsOxdtnCtlystOtltGsTm : 16|16@1+ (0.03125,-273) [-273|1734.96875] "deg C" Vector__XXX
 SG_ Aftrtrtmnt2GsOxdtnCtlystIntkGsTm : 0|16@1+ (0.03125,-273) [-273|1734.96875] "deg C" Vector__XXX

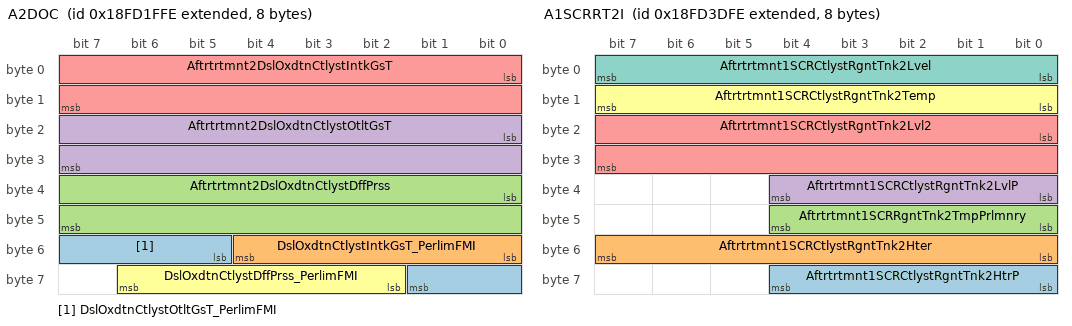
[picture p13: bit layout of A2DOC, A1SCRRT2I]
BO_ 2566725630 A2DOC: 8 Vector__XXX
 SG_ DslOxdtnCtlystOtltGsT_PerlimFMI : 53|5@1+ (1,0) [0|31] "" Vector__XXX
 SG_ DslOxdtnCtlystIntkGsT_PerlimFMI : 48|5@1+ (1,0) [0|31] "" Vector__XXX
 SG_ Aftrtrtmnt2DslOxdtnCtlystDffPrss : 32|16@1+ (0.5,0) [0|32127.5] "kPa" Vector__XXX
 SG_ Aftrtrtmnt2DslOxdtnCtlystOtltGsT : 16|16@1+ (0.03125,-273) [-273|1734.96875] "deg C" Vector__XXX
 SG_ Aftrtrtmnt2DslOxdtnCtlystIntkGsT : 0|16@1+ (0.03125,-273) [-273|1734.96875] "deg C" Vector__XXX
 SG_ DslOxdtnCtlystDffPrss_PerlimFMI : 58|5@1+ (1,0) [0|31] "" Vector__XXX

BO_ 2566733310 A1SCRRT2I: 8 Vector__XXX
 SG_ Aftrtrtmnt1SCRCtlystRgntTnk2HtrP : 56|5@1+ (1,0) [0|31] "" Vector__XXX
 SG_ Aftrtrtmnt1SCRCtlystRgntTnk2Hter : 48|8@1+ (0.4,0) [0|100] "%" Vector__XXX
 SG_ Aftrtrtmnt1SCRRgntTnk2TmpPrlmnry : 40|5@1+ (1,0) [0|31] "" Vector__XXX
 SG_ Aftrtrtmnt1SCRCtlystRgntTnk2LvlP : 32|5@1+ (1,0) [0|31] "" Vector__XXX
 SG_ Aftrtrtmnt1SCRCtlystRgntTnk2Lvl2 : 16|16@1+ (1,0) [0|6425.5] "mm" Vector__XXX
 SG_ Aftrtrtmnt1SCRCtlystRgntTnk2Temp : 8|8@1+ (1,-40) [-40|210] "deg C" Vector__XXX
 SG_ Aftrtrtmnt1SCRCtlystRgntTnk2Lvel : 0|8@1+ (0.4,0) [0|100] "%" Vector__XXX

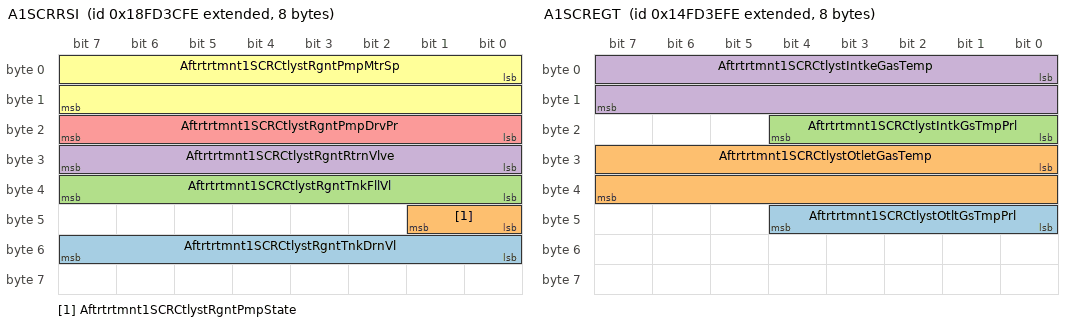
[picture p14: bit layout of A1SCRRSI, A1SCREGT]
BO_ 2566733054 A1SCRRSI: 8 Vector__XXX
 SG_ Aftrtrtmnt1SCRCtlystRgntTnkDrnVl : 48|8@1+ (1,0) [0|100] "%" Vector__XXX
 SG_ Aftrtrtmnt1SCRCtlystRgntPmpState : 40|2@1+ (1,0) [0|3] "" Vector__XXX
 SG_ Aftrtrtmnt1SCRCtlystRgntTnkFllVl : 32|8@1+ (1,0) [0|100] "%" Vector__XXX
 SG_ Aftrtrtmnt1SCRCtlystRgntRtrnVlve : 24|8@1+ (1,0) [0|100] "%" Vector__XXX
 SG_ Aftrtrtmnt1SCRCtlystRgntPmpDrvPr : 16|8@1+ (1,0) [0|100] "%" Vector__XXX
 SG_ Aftrtrtmnt1SCRCtlystRgntPmpMtrSp : 0|16@1+ (0.5,0) [0|32127.5] "rpm" Vector__XXX

BO_ 2499624702 A1SCREGT: 8 Vector__XXX
 SG_ Aftrtrtmnt1SCRCtlystOtltGsTmpPrl : 40|5@1+ (1,0) [0|31] "" Vector__XXX
 SG_ Aftrtrtmnt1SCRCtlystOtletGasTemp : 24|16@1+ (0.03125,-273) [-273|1734.96875] "deg C" Vector__XXX
 SG_ Aftrtrtmnt1SCRCtlystIntkGsTmpPrl : 16|5@1+ (1,0) [0|31] "" Vector__XXX
 SG_ Aftrtrtmnt1SCRCtlystIntkeGasTemp : 0|16@1+ (0.03125,-273) [-273|1734.96875] "deg C" Vector__XXX

BO_ 2566733822 A1SCREGP: 8 Vector__XXX
 SG_ SCRCtlystExhstGsDffPr_PrelimFMI : 16|5@1+ (1,0) [0|31] "" Vector__XXX
 SG_ Aftrtrtmnt1SCRCtlystExhstGsDffPr : 0|16@1+ (0.1,0) [0|6425.5] "kPa" Vector__XXX

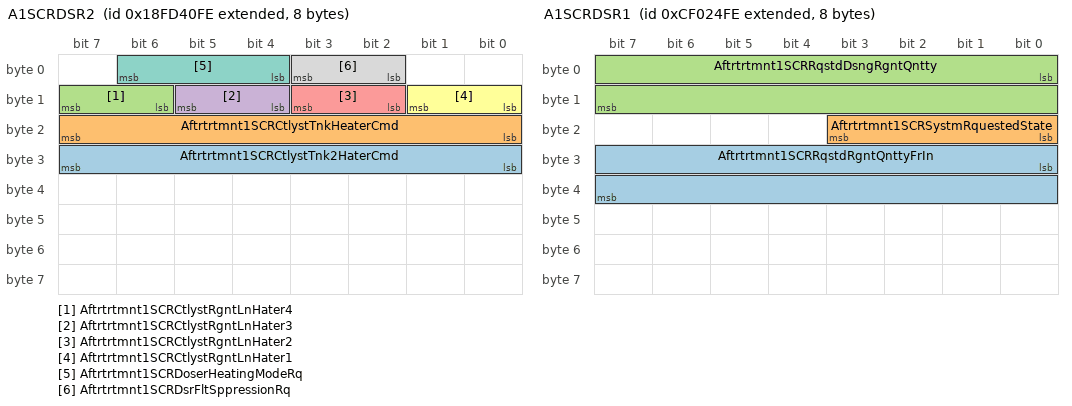
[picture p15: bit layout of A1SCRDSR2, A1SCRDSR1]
BO_ 2566734078 A1SCRDSR2: 8 Vector__XXX
 SG_ Aftrtrtmnt1SCRCtlystTnk2HaterCmd : 24|8@1+ (1,0) [0|100] "%" Vector__XXX
 SG_ Aftrtrtmnt1SCRCtlystTnkHeaterCmd : 16|8@1+ (1,0) [0|100] "%" Vector__XXX
 SG_ Aftrtrtmnt1SCRCtlystRgntLnHater4 : 14|2@1+ (1,0) [0|3] "" Vector__XXX
 SG_ Aftrtrtmnt1SCRCtlystRgntLnHater3 : 12|2@1+ (1,0) [0|3] "" Vector__XXX
 SG_ Aftrtrtmnt1SCRCtlystRgntLnHater2 : 10|2@1+ (1,0) [0|3] "" Vector__XXX
 SG_ Aftrtrtmnt1SCRCtlystRgntLnHater1 : 8|2@1+ (1,0) [0|3] "" Vector__XXX
 SG_ Aftrtrtmnt1SCRDoserHeatingModeRq : 4|3@1+ (1,0) [0|7] "" Vector__XXX
 SG_ Aftrtrtmnt1SCRDsrFltSppressionRq : 2|2@1+ (1,0) [0|3] "" Vector__XXX

BO_ 2364548350 A1SCRDSR1: 8 Vector__XXX
 SG_ Aftrtrtmnt1SCRRqstdRgntQnttyFrIn : 24|16@1+ (0.1,0) [0|6425.5] "g" Vector__XXX
 SG_ Aftrtrtmnt1SCRSystmRquestedState : 16|4@1+ (1,0) [0|15] "" Vector__XXX
 SG_ Aftrtrtmnt1SCRRqstdDsngRgntQntty : 0|16@1+ (0.3,0) [0|19276.5] "g/h" Vector__XXX

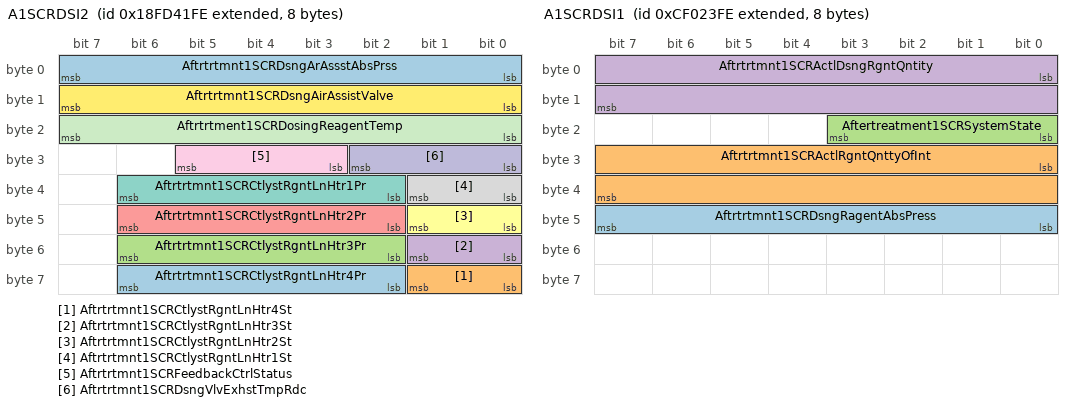
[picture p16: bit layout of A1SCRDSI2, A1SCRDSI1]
BO_ 2566734334 A1SCRDSI2: 8 Vector__XXX
 SG_ Aftrtrtmnt1SCRCtlystRgntLnHtr4Pr : 58|5@1+ (1,0) [0|31] "" Vector__XXX
 SG_ Aftrtrtmnt1SCRCtlystRgntLnHtr4St : 56|2@1+ (1,0) [0|3] "" Vector__XXX
 SG_ Aftrtrtmnt1SCRCtlystRgntLnHtr3Pr : 50|5@1+ (1,0) [0|31] "" Vector__XXX
 SG_ Aftrtrtmnt1SCRCtlystRgntLnHtr3St : 48|2@1+ (1,0) [0|3] "" Vector__XXX
 SG_ Aftrtrtmnt1SCRCtlystRgntLnHtr2Pr : 42|5@1+ (1,0) [0|31] "" Vector__XXX
 SG_ Aftrtrtmnt1SCRCtlystRgntLnHtr2St : 40|2@1+ (1,0) [0|3] "" Vector__XXX
 SG_ Aftrtrtmnt1SCRCtlystRgntLnHtr1Pr : 34|5@1+ (1,0) [0|31] "" Vector__XXX
 SG_ Aftrtrtmnt1SCRCtlystRgntLnHtr1St : 32|2@1+ (1,0) [0|3] "" Vector__XXX
 SG_ Aftrtrtmnt1SCRFeedbackCtrlStatus : 27|3@1+ (1,0) [0|7] "" Vector__XXX
 SG_ Aftrtrtmnt1SCRDsngVlvExhstTmpRdc : 24|3@1+ (1,0) [0|7] "" Vector__XXX
 SG_ Aftrtrtment1SCRDosingReagentTemp : 16|8@1+ (1,-40) [-40|210] "deg C" Vector__XXX
 SG_ Aftrtrtmnt1SCRDsngAirAssistValve : 8|8@1+ (1,0) [0|100] "%" Vector__XXX
 SG_ Aftrtrtmnt1SCRDsngArAssstAbsPrss : 0|8@1+ (8,0) [0|2000] "kPa" Vector__XXX

BO_ 2364548094 A1SCRDSI1: 8 Vector__XXX
 SG_ Aftrtrtmnt1SCRDsngRagentAbsPress : 40|8@1+ (8,0) [0|2000] "kPa" Vector__XXX
 SG_ Aftrtrtmnt1SCRActlRgntQnttyOfInt : 24|16@1+ (0.1,0) [0|6425.5] "g" Vector__XXX
 SG_ Aftertreatment1SCRSystemState : 16|4@1+ (1,0) [0|15] "" Vector__XXX
 SG_ Aftrtrtmnt1SCRActlDsngRgntQntity : 0|16@1+ (0.3,0) [0|19276.5] "g/h" Vector__XXX

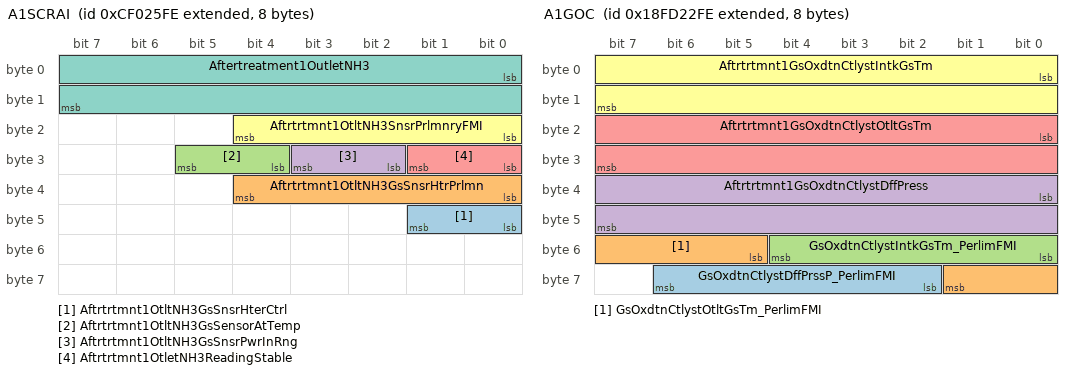
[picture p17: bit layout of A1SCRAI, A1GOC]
BO_ 2364548606 A1SCRAI: 8 Vector__XXX
 SG_ Aftrtrtmnt1OtltNH3GsSnsrHterCtrl : 40|2@1+ (1,0) [0|3] "" Vector__XXX
 SG_ Aftrtrtmnt1OtltNH3GsSnsrHtrPrlmn : 32|5@1+ (1,0) [0|31] "" Vector__XXX
 SG_ Aftrtrtmnt1OtltNH3GsSensorAtTemp : 28|2@1+ (1,0) [0|3] "" Vector__XXX
 SG_ Aftrtrtmnt1OtltNH3GsSnsrPwrInRng : 26|2@1+ (1,0) [0|3] "" Vector__XXX
 SG_ Aftrtrtmnt1OtletNH3ReadingStable : 24|2@1+ (1,0) [0|3] "" Vector__XXX
 SG_ Aftrtrtmnt1OtltNH3SnsrPrlmnryFMI : 16|5@1+ (1,0) [0|31] "" Vector__XXX
 SG_ Aftertreatment1OutletNH3 : 0|16@1+ (0.3,0) [0|19276.5] "g/h" Vector__XXX

BO_ 2566726398 A1GOC: 8 Vector__XXX
 SG_ GsOxdtnCtlystDffPrssP_PerlimFMI : 58|5@1+ (1,0) [0|31] "" Vector__XXX
 SG_ GsOxdtnCtlystOtltGsTm_PerlimFMI : 53|5@1+ (1,0) [0|31] "" Vector__XXX
 SG_ GsOxdtnCtlystIntkGsTm_PerlimFMI : 48|5@1+ (1,0) [0|31] "" Vector__XXX
 SG_ Aftrtrtmnt1GsOxdtnCtlystDffPress : 32|16@1+ (0.1,0) [0|6425.5] "kPa" Vector__XXX
 SG_ Aftrtrtmnt1GsOxdtnCtlystOtltGsTm : 16|16@1+ (0.03125,-273) [-273|1734.96875] "deg C" Vector__XXX
 SG_ Aftrtrtmnt1GsOxdtnCtlystIntkGsTm : 0|16@1+ (0.03125,-273) [-273|1734.96875] "deg C" Vector__XXX

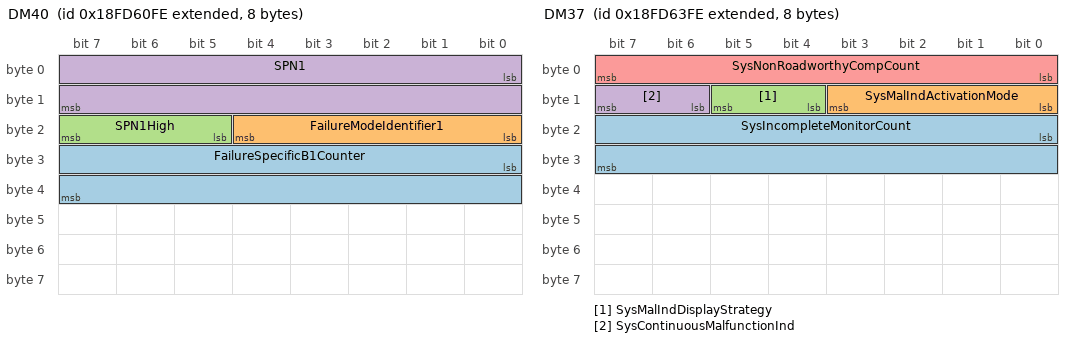
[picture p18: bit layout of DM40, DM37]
BO_ 2566742270 DM40: 8 Vector__XXX
 SG_ FailureSpecificB1Counter : 24|16@1+ (0.1,0) [0|6425.5] "hr" Vector__XXX
 SG_ FailureModeIdentifier1 : 16|5@1+ (1,0) [0|0] "" Vector__XXX
 SG_ SPN1High : 21|3@1+ (1,0) [0|7] "" Vector__XXX
 SG_ SPN1 : 0|16@1+ (1,0) [0|65536] "" Vector__XXX

BO_ 2566742526 DM39: 8 Vector__XXX
 SG_ SysGreatestB1Counter : 32|16@1+ (0.1,0) [0|6425.5] "hr" Vector__XXX
 SG_ SysCumulativeContinuousMITime : 0|32@1+ (0.05,0) [0|210554060.75] "hr" Vector__XXX

BO_ 2566742782 DM38: 8 Vector__XXX
 SG_ RegulationDescription : 0|8@1+ (1,0) [0|255] "" Vector__XXX

BO_ 2566743038 DM37: 8 Vector__XXX
 SG_ SysIncompleteMonitorCount : 16|16@1+ (1,0) [0|64512] "" Vector__XXX
 SG_ SysMalIndActivationMode : 8|4@1+ (1,0) [0|15] "" Vector__XXX
 SG_ SysMalIndDisplayStrategy : 12|2@1+ (1,0) [0|3] "" Vector__XXX
 SG_ SysContinuousMalfunctionInd : 14|2@1+ (1,0) [0|3] "" Vector__XXX
 SG_ SysNonRoadworthyCompCount : 0|8@1+ (1,0) [0|250] "" Vector__XXX

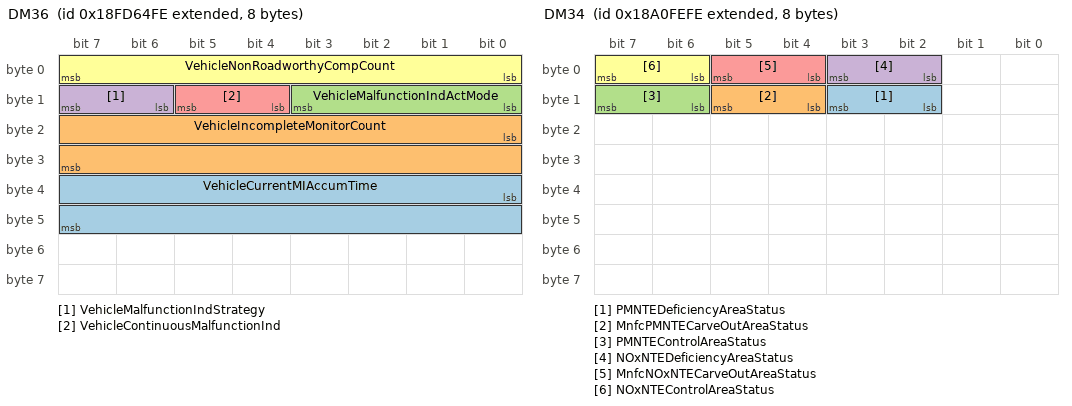
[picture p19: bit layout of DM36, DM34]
BO_ 2566743294 DM36: 8 Vector__XXX
 SG_ VehicleCurrentMIAccumTime : 32|16@1+ (1,0) [0|64255] "min" Vector__XXX
 SG_ VehicleIncompleteMonitorCount : 16|16@1+ (1,0) [0|64255] "" Vector__XXX
 SG_ VehicleMalfunctionIndActMode : 8|4@1+ (1,0) [0|15] "" Vector__XXX
 SG_ VehicleMalfunctionIndStrategy : 14|2@1+ (1,0) [0|3] "" Vector__XXX
 SG_ VehicleContinuousMalfunctionInd : 12|2@1+ (1,0) [0|3] "" Vector__XXX
 SG_ VehicleNonRoadworthyCompCount : 0|8@1+ (1,0) [0|250] "" Vector__XXX

BO_ 2560687870 DM34: 8 Vector__XXX
 SG_ PMNTEDeficiencyAreaStatus : 10|2@1+ (1,0) [0|3] "" Vector__XXX
 SG_ MnfcPMNTECarveOutAreaStatus : 12|2@1+ (1,0) [0|3] "" Vector__XXX
 SG_ PMNTEControlAreaStatus : 14|2@1+ (1,0) [0|3] "" Vector__XXX
 SG_ NOxNTEDeficiencyAreaStatus : 2|2@1+ (1,0) [0|3] "" Vector__XXX
 SG_ MnfcNOxNTECarveOutAreaStatus : 4|2@1+ (1,0) [0|3] "" Vector__XXX
 SG_ NOxNTEControlAreaStatus : 6|2@1+ (1,0) [0|3] "" Vector__XXX

BO_ 2292317950 DM33: 9 Vector__XXX
 SG_ AECDEngineHours1Timer2 : 40|32@1+ (1,0) [0|4294967295] "min" Vector__XXX
 SG_ AECDEngineHours1Timer1 : 8|32@1+ (1,0) [0|4294967295] "min" Vector__XXX
 SG_ AECDNumber1 : 0|8@1+ (1,0) [0|250] "" Vector__XXX

BO_ 2566809342 BM: 8 Vector__XXX
 SG_ BatteryMainSwitchHoldState : 0|2@1+ (1,0) [0|3] "" Vector__XXX

CM_ BO_ 2365401854 "Used to transfer information about the measured status of the 1st 2 axes and up to 12 buttons of a joystick. Additional";
CM_ SG_ 2365401854 Joystick7Button9PressedStatus "Reports when the joystick button has been pressed.";
CM_ SG_ 2365401854 Joystick7Button10PressedStatus "Reports when the joystick button has been pressed.";
CM_ SG_ 2365401854 Joystick7Button11PressedStatus "Reports when the joystick button has been pressed.";
CM_ SG_ 2365401854 Joystick7Button12PressedStatus "Reports when the joystick button has been pressed.";
CM_ SG_ 2365401854 Joystick7Button5PressedStatus "Reports when the joystick button has been pressed.";
CM_ SG_ 2365401854 Joystick7Button6PressedStatus "Reports when the joystick button has been pressed.";
CM_ SG_ 2365401854 Joystick7Button7PressedStatus "Reports when the joystick button has been pressed.";
CM_ SG_ 2365401854 Joystick7Button8PressedStatus "Reports when the joystick button has been pressed.";
CM_ SG_ 2365401854 Joystick7Button1PressedStatus "Reports when the joystick button has been pressed.";
CM_ SG_ 2365401854 Joystick7Button2PressedStatus "Reports when the joystick button has been pressed.";
CM_ SG_ 2365401854 Joystick7Button3PressedStatus "Reports when the joystick button has been pressed.";
CM_ SG_ 2365401854 Joystick7Button4PressedStatus "Reports when the joystick button has been pressed.";
CM_ SG_ 2365401854 Joystick7XAxisDetentPosStatus "Reports when the current joystick position is in the detent position for that axis of travel.";
CM_ SG_ 2365401854 Joystick7YAxisDetentPosStatus "Reports when the current joystick position is in the detent position for that axis of travel.";
CM_ SG_ 2365401854 Joystick7YAxisPos "The position of the joystick in the relative motion of travel from the neutral position. Position value of 0 is Neutral and";
CM_ SG_ 2365401854 Jystck7YAxsLvrFrwrdPstvPosStatus "Reports when the current joystick position is on the positive travel side (forward, right, clockwise, up) relative to the";
CM_ SG_ 2365401854 Jystck7YAxsLvrBckNgtivePosStatus "Reports when the current joystick position is on the negative travel side (back, left, counterclockwise, down) relative to the";
CM_ SG_ 2365401854 Joystick7YAxisNeutralPosStatus "Reports when the current joystick position is in the neutral position for that axis of travel. The neutral position";
CM_ SG_ 2365401854 Joystick7XAxisPos "The position of the joystick in the relative motion of travel from the neutral position. Position value of 0 is Neutral and";
CM_ SG_ 2365401854 Jystck7XAxsLvrRghtPstvePosStatus "Reports when the current joystick position is on the positive travel side (forward, right, clockwise, up) relative to the";
CM_ SG_ 2365401854 Jystck7XAxsLvrLftNgtivePosStatus "Reports when the current joystick position is on the negative travel side (back, left, counterclockwise, down) relative to the";
CM_ SG_ 2365401854 Joystick7XAxisNeutralPosStatus "Reports when the current joystick position is in the neutral position for that axis of travel. The neutral position";
CM_ BO_ 2365402366 "Used to transfer information about the measured status of the 1st 2 axes and up to 12 buttons of a joystick. Additional";
CM_ SG_ 2365402366 Joystick6Button9PressedStatus "Reports when the joystick button has been pressed.";
CM_ SG_ 2365402366 Joystick6Button10PressedStatus "Reports when the joystick button has been pressed.";
CM_ SG_ 2365402366 Joystick6Button11PressedStatus "Reports when the joystick button has been pressed.";
CM_ SG_ 2365402366 Joystick6Button12PressedStatus "Reports when the joystick button has been pressed.";
CM_ SG_ 2365402366 Joystick6Button5PressedStatus "Reports when the joystick button has been pressed.";
CM_ SG_ 2365402366 Joystick6Button6PressedStatus "Reports when the joystick button has been pressed.";
CM_ SG_ 2365402366 Joystick6Button7PressedStatus "Reports when the joystick button has been pressed.";
CM_ SG_ 2365402366 Joystick6Button8PressedStatus "Reports when the joystick button has been pressed.";
CM_ SG_ 2365402366 Joystick6Button1PressedStatus "Reports when the joystick button has been pressed.";
CM_ SG_ 2365402366 Joystick6Button2PressedStatus "Reports when the joystick button has been pressed.";
CM_ SG_ 2365402366 Joystick6Button3PressedStatus "Reports when the joystick button has been pressed.";
CM_ SG_ 2365402366 Joystick6Button4PressedStatus "Reports when the joystick button has been pressed.";
CM_ SG_ 2365402366 Joystick6XAxisDetentPosStatus "Reports when the current joystick position is in the detent position for that axis of travel.";
CM_ SG_ 2365402366 Joystick6YAxisDetentPosStatus "Reports when the current joystick position is in the detent position for that axis of travel.";
CM_ SG_ 2365402366 Joystick6YAxisPos "The position of the joystick in the relative motion of travel from the neutral position. Position value of 0 is Neutral and";
CM_ SG_ 2365402366 Jystck6YAxsLvrFrwrdPstvPosStatus "Reports when the current joystick position is on the positive travel side (forward, right, clockwise, up) relative to the";
CM_ SG_ 2365402366 Jystck6YAxsLvrBckNgtivePosStatus "Reports when the current joystick position is on the negative travel side (back, left, counterclockwise, down) relative to the";
CM_ SG_ 2365402366 Joystick6YAxisNeutralPosStatus "Reports when the current joystick position is in the neutral position for that axis of travel. The neutral position";
CM_ SG_ 2365402366 Joystick6XAxisPos "The position of the joystick in the relative motion of travel from the neutral position. Position value of 0 is Neutral and";
CM_ SG_ 2365402366 Jystck6XAxsLvrRghtPstvePosStatus "Reports when the current joystick position is on the positive travel side (forward, right, clockwise, up) relative to the";
CM_ SG_ 2365402366 Jystck6XAxsLvrLftNgtivePosStatus "Reports when the current joystick position is on the negative travel side (back, left, counterclockwise, down) relative to the";
CM_ SG_ 2365402366 Joystick6XAxisNeutralPosStatus "Reports when the current joystick position is in the neutral position for that axis of travel. The neutral position";
CM_ BO_ 2365402878 "Used to transfer information about the measured status of the 1st 2 axes and up to 12 buttons of a joystick. Additional";
CM_ SG_ 2365402878 Joystick5Button9PressedStatus "Reports when the joystick button has been pressed.";
CM_ SG_ 2365402878 Joystick5Button10PressedStatus "Reports when the joystick button has been pressed.";
CM_ SG_ 2365402878 Joystick5Button11PressedStatus "Reports when the joystick button has been pressed.";
CM_ SG_ 2365402878 Joystick5Button12PressedStatus "Reports when the joystick button has been pressed.";
CM_ SG_ 2365402878 Joystick5Button5PressedStatus "Reports when the joystick button has been pressed.";
CM_ SG_ 2365402878 Joystick5Button6PressedStatus "Reports when the joystick button has been pressed.";
CM_ SG_ 2365402878 Joystick5Button7PressedStatus "Reports when the joystick button has been pressed.";
CM_ SG_ 2365402878 Joystick5Button8PressedStatus "Reports when the joystick button has been pressed.";
CM_ SG_ 2365402878 Joystick5Button1PressedStatus "Reports when the joystick button has been pressed.";
CM_ SG_ 2365402878 Joystick5Button2PressedStatus "Reports when the joystick button has been pressed.";
CM_ SG_ 2365402878 Joystick5Button3PressedStatus "Reports when the joystick button has been pressed.";
CM_ SG_ 2365402878 Joystick5Button4PressedStatus "Reports when the joystick button has been pressed.";
CM_ SG_ 2365402878 Joystick5XAxisDetentPosStatus "Reports when the current joystick position is in the detent position for that axis of travel.";
CM_ SG_ 2365402878 Joystick5YAxisDetentPosStatus "Reports when the current joystick position is in the detent position for that axis of travel.";
CM_ SG_ 2365402878 Joystick5YAxisPos "The position of the joystick in the relative motion of travel from the neutral position. Position value of 0 is Neutral and";
CM_ SG_ 2365402878 Jystck5YAxsLvrFrwrdPstvPosStatus "Reports when the current joystick position is on the positive travel side (forward, right, clockwise, up) relative to the";
CM_ SG_ 2365402878 Jystck5YAxsLvrBckNgtivePosStatus "Reports when the current joystick position is on the negative travel side (back, left, counterclockwise, down) relative to the";
CM_ SG_ 2365402878 Joystick5YAxisNeutralPosStatus "Reports when the current joystick position is in the neutral position for that axis of travel. The neutral position";
CM_ SG_ 2365402878 Joystick5XAxisPos "The position of the joystick in the relative motion of travel from the neutral position. Position value of 0 is Neutral and";
CM_ SG_ 2365402878 Jystck5XAxsLvrRghtPstvePosStatus "Reports when the current joystick position is on the positive travel side (forward, right, clockwise, up) relative to the";
CM_ SG_ 2365402878 Jystck5XAxsLvrLftNgtivePosStatus "Reports when the current joystick position is on the negative travel side (back, left, counterclockwise, down) relative to the";
CM_ SG_ 2365402878 Joystick5XAxisNeutralPosStatus "Reports when the current joystick position is in the neutral position for that axis of travel. The neutral position";
CM_ BO_ 2365403390 "Used to transfer information about the measured status of the 1st 2 axes and up to 12 buttons of a joystick. Additional";
CM_ SG_ 2365403390 Joystick4Button9PressedStatus "Reports when the joystick button has been pressed.";
CM_ SG_ 2365403390 Joystick4Button10PressedStatus "Reports when the joystick button has been pressed.";
CM_ SG_ 2365403390 Joystick4Button11PressedStatus "Reports when the joystick button has been pressed.";
CM_ SG_ 2365403390 Joystick4Button12PressedStatus "Reports when the joystick button has been pressed.";
CM_ SG_ 2365403390 Joystick4Button5PressedStatus "Reports when the joystick button has been pressed.";
CM_ SG_ 2365403390 Joystick4Button6PressedStatus "Reports when the joystick button has been pressed.";
CM_ SG_ 2365403390 Joystick4Button7PressedStatus "Reports when the joystick button has been pressed.";
CM_ SG_ 2365403390 Joystick4Button8PressedStatus "Reports when the joystick button has been pressed.";
CM_ SG_ 2365403390 Joystick4Button1PressedStatus "Reports when the joystick button has been pressed.";
CM_ SG_ 2365403390 Joystick4Button2PressedStatus "Reports when the joystick button has been pressed.";
CM_ SG_ 2365403390 Joystick4Button3PressedStatus "Reports when the joystick button has been pressed.";
CM_ SG_ 2365403390 Joystick4Button4PressedStatus "Reports when the joystick button has been pressed.";
CM_ SG_ 2365403390 Joystick4XAxisDetentPosStatus "Reports when the current joystick position is in the detent position for that axis of travel.";
CM_ SG_ 2365403390 Joystick4YAxisDetentPosStatus "Reports when the current joystick position is in the detent position for that axis of travel.";
CM_ SG_ 2365403390 Joystick4YAxisPos "The position of the joystick in the relative motion of travel from the neutral position. Position value of 0 is Neutral and";
CM_ SG_ 2365403390 Jystck4YAxsLvrFrwrdPstvPosStatus "Reports when the current joystick position is on the positive travel side (forward, right, clockwise, up) relative to the";
CM_ SG_ 2365403390 Jystck4YAxsLvrBckNgtivePosStatus "Reports when the current joystick position is on the negative travel side (back, left, counterclockwise, down) relative to the";
CM_ SG_ 2365403390 Joystick4YAxisNeutralPosStatus "Reports when the current joystick position is in the neutral position for that axis of travel. The neutral position";
CM_ SG_ 2365403390 Joystick4XAxisPos "The position of the joystick in the relative motion of travel from the neutral position. Position value of 0 is Neutral and";
CM_ SG_ 2365403390 Jystck4XAxsLvrRghtPstvePosStatus "Reports when the current joystick position is on the positive travel side (forward, right, clockwise, up) relative to the";
CM_ SG_ 2365403390 Jystck4XAxsLvrLftNgtivePosStatus "Reports when the current joystick position is on the negative travel side (back, left, counterclockwise, down) relative to the";
CM_ SG_ 2365403390 Joystick4XAxisNeutralPosStatus "Reports when the current joystick position is in the neutral position for that axis of travel. The neutral position";
CM_ BO_ 2365400318 "Used to transfer information about the measured status of the 1st 2 axes and up to 12 buttons of a joystick. Additional";
CM_ SG_ 2365400318 Joystick10Button9PressedStatus "Reports when the joystick button has been pressed.";
CM_ SG_ 2365400318 Joystick10Button10PressedStatus "Reports when the joystick button has been pressed.";
CM_ SG_ 2365400318 Joystick10Button11PressedStatus "Reports when the joystick button has been pressed.";
CM_ SG_ 2365400318 Joystick10Button12PressedStatus "Reports when the joystick button has been pressed.";
CM_ SG_ 2365400318 Joystick10Button5PressedStatus "Reports when the joystick button has been pressed.";
CM_ SG_ 2365400318 Joystick10Button6PressedStatus "Reports when the joystick button has been pressed.";
CM_ SG_ 2365400318 Joystick10Button7PressedStatus "Reports when the joystick button has been pressed.";
CM_ SG_ 2365400318 Joystick10Button8PressedStatus "Reports when the joystick button has been pressed.";
CM_ SG_ 2365400318 Joystick10Button1PressedStatus "Reports when the joystick button has been pressed.";
CM_ SG_ 2365400318 Joystick10Button2PressedStatus "Reports when the joystick button has been pressed.";
CM_ SG_ 2365400318 Joystick10Button3PressedStatus "Reports when the joystick button has been pressed.";
CM_ SG_ 2365400318 Joystick10Button4PressedStatus "Reports when the joystick button has been pressed.";
CM_ SG_ 2365400318 Joystick10XAxisDetentPosStatus "Reports when the current joystick position is in the detent position for that axis of travel.";
CM_ SG_ 2365400318 Joystick10YAxisDetentPosStatus "Reports when the current joystick position is in the detent position for that axis of travel.";
CM_ SG_ 2365400318 Joystick10YAxisPos "The position of the joystick in the relative motion of travel from the neutral position. Position value of 0 is Neutral and";
CM_ SG_ 2365400318 Jystck10YAxsLvrFrwrdPstvPsStatus "Reports when the current joystick position is on the positive travel side (forward, right, clockwise, up) relative to the";
CM_ SG_ 2365400318 Jystck10YAxsLvrBckNgtvePosStatus "Reports when the current joystick position is on the negative travel side (back, left, counterclockwise, down) relative to the";
CM_ SG_ 2365400318 Joystick10YAxisNeutralPosStatus "Reports when the current joystick position is in the neutral position for that axis of travel. The neutral position";
CM_ SG_ 2365400318 Joystick10XAxisPos "The position of the joystick in the relative motion of travel from the neutral position. Position value of 0 is Neutral and";
CM_ SG_ 2365400318 Jystck10XAxsLvrRghtPstvPosStatus "Reports when the current joystick position is on the positive travel side (forward, right, clockwise, up) relative to the";
CM_ SG_ 2365400318 Jystck10XAxsLvrLftNgtvePosStatus "Reports when the current joystick position is on the negative travel side (back, left, counterclockwise, down) relative to the";
CM_ SG_ 2365400318 Joystick10XAxisNeutralPosStatus "Reports when the current joystick position is in the neutral position for that axis of travel. The neutral position";
CM_ BO_ 2499614718 "Message containing Beltlock States and the Passener Airbag Deactivation Switch State.";
CM_ SG_ 2499614718 PssngrArbgDctivationSwitchStatus "State of switch used to deactivate Passenger Airbag manually.";
CM_ SG_ 2499614718 Beltlock10Status "State of switch used to determine if Beltlock 10 is buckled.";
CM_ SG_ 2499614718 Beltlock9Status "State of switch used to determine if Beltlock 9 is buckled.";
CM_ SG_ 2499614718 Beltlock8Status "State of switch used to determine if Beltlock 8 is buckled.";
CM_ SG_ 2499614718 Beltlock7Status "State of switch used to determine if Beltlock 7 is buckled.";
CM_ SG_ 2499614718 Beltlock6Status "State of switch used to determine if Beltlock 6 is buckled.";
CM_ SG_ 2499614718 Beltlock5Status "State of switch used to determine if Beltlock 5 is buckled.";
CM_ SG_ 2499614718 Beltlock4Status "State of switch used to determine if Beltlock 4 is buckled.";
CM_ SG_ 2499614718 Beltlock3Status "State of switch used to determine if Beltlock 3 is buckled.";
CM_ SG_ 2499614718 PassengerBeltlockStatus "State of switch used to determine if Passenger Beltlock is buckled.";
CM_ SG_ 2499614718 DriverBeltlockStatus "State of switch used to determine if Driver Beltlock is buckled.";
CM_ BO_ 2566722814 "Parameters for the battery charger connected to the auxiliary battery.";
CM_ SG_ 2566722814 BatteryCharger2OutputCurrent "Output current of the battery charger connected to the main battery. If positive, this parameter shows the charging current";
CM_ SG_ 2566722814 BatteryCharger2OutputVoltage "Output voltage measured on the battery terminals of the offline battery charger connected to the auxiliary battery.";
CM_ SG_ 2566722814 BatteryCharger2PowerLineState "A state of the battery charger connection to the power line for the charger connected to the auxiliary battery.";
CM_ SG_ 2566722814 BatteryCharger2State "A state of the offline battery charger connected to the auxiliary battery.";
CM_ BO_ 2566723070 "Parameters for the battery charger connected to the main battery.";
CM_ SG_ 2566723070 BatteryCharger1OutputCurrent "Output current of the battery charger connected to the main battery. If positive, this parameter shows the charging current";
CM_ SG_ 2566723070 BatteryCharger1OutputVoltage "Output voltage measured on the battery terminals of the battery charger connected to the main battery.";
CM_ SG_ 2566723070 BatteryCharger1PowerLineState "A state of the battery charger connection to the power line for the charger connected to the main battery.";
CM_ SG_ 2566723070 BatteryCharger1State "A state of the battery charger connected to the main battery.";
CM_ BO_ 2566725118 "The purpose of this PGN is to group the aftertreatment differential temperature data. These values include the differential";
CM_ SG_ 2566725118 Aftrtrtmnt2ThrWyCtlystDffGasTemp "The differential engine combustion byproducts gas temperature measured between the intake and outlet of the three way";
CM_ SG_ 2566725118 Aftrtrtmnt1ThrWyCtlystDffGasTemp "The differential engine combustion byproducts gas temperature measured between the intake and outlet of the three way";
CM_ BO_ 2566725374 "Aftertreatment Differential Temperature 1";
CM_ SG_ 2566725374 Aftrtrtmnt2GsOxdtnCtlystDffGsTmp "The differential engine combustion byproducts gas temperature measured between the intake and outlet of the gas";
CM_ SG_ 2566725374 Aftrtrtmnt1GsOxdtnCtlystDffGsTmp "The differential engine combustion byproducts gas temperature measured between the intake and outlet of the gas";
CM_ BO_ 2566712830 "This PGN contains information for the warm up oxidation catalytic converter in exhaust bank 2.";
CM_ SG_ 2566712830 Aftrtrtmnt2WrmUpDslOxdtnCtlystOt "Temperature of engine combustion byproducts leaving the warm up Diesel Oxidation Catalyst in exhaust bank 2. This";
CM_ SG_ 2566712830 Aftrtrtmnt2WrmUpDslOxdtnCtlystIn "Temperature of engine combustion byproducts entering the warm up Diesel Oxidation Catalyst in exhaust bank 2. This";
CM_ BO_ 2566735358 "Aftertreatment 2 Three Way Catalytic Converter";
CM_ SG_ 2566735358 Aftrtrtmnt2ThrWyCtlytcCnvrtrDffP "Used to identify the applicable J1939-73 FMI detected in the Three Way Catalytic Converter differential pressure sensorExhaust differential pressure measured between the intake and exhaust of a Three Way Catalytic Converter in exhaust";
CM_ SG_ 2566735358 Aftrtrtmnt2ThrWyCtlytcCnvrtrOtlt "Used to identify the applicable J1939-73 FMI detected in the Three Way Catalytic Converter outlet gas temperatureTemperature of engine combustion byproducts leaving the Three Way Catalytic Converter in exhaust bank 2.";
CM_ SG_ 2566735358 Aftrtrtmnt2ThrWyCtlytcCnvrtrIntk "Used to identify the applicable J1939-73 FMI detected in the Three Way Catalytic Converter intake gas temperatureTemperature of engine combustion byproducts entering the Three Way Catalytic Converter in exhaust bank 2.";
CM_ SG_ 2365393662 Aftrtrtmnt2OtltGsNOxSnsrNH3Crrct "Correction of NH3 at the NOx-signal to correct (recalculate) sensor signal on the Engine ECU side.";
CM_ SG_ 2365393662 Aftrtrtmnt2OtltGsNOxSnsrNO2Crrct "Correction of NO2 at the NOx-signal to correct (recalculate) sensor signal on the Engine ECU side.";
CM_ SG_ 2365393662 Aftrtrtmnt2OtltGsNOxSnsrCrrctnOf "Correction of pressure NOx-signal to correct (recalculate) sensor signal on the Engine ECU side.Correction of pressure Lambda-signal to correct (recalculate) sensor signal on the Engine ECU side.";
CM_ BO_ 2365393918 "Tr";
CM_ SG_ 2365393918 Aftrtrtmnt2OtltGsNOxSnsrNwPrtDvt "New part deviation NOx_Offset to correct (recalculate) sensor signal on the Engine ECU side.New part deviation NOx_Gain to correct (recalculate) sensor signal on the Engine ECU side.";
CM_ SG_ 2365393918 Aftrtrtmnt2OtltGsNOxSnsrHtrRatio "Heater ratio to determine temperature at sensor tip.";
CM_ BO_ 2365394174 "Aftertreatment 2 Intake Gas NOx Sensor correction data 2";
CM_ SG_ 2365394174 Aftrtrtmnt2IntkGsNOxSnsrNH3Crrct "Correction of NH3 at the NOx-signal to correct (recalculate) sensor signal on the Engine ECU side.";
CM_ SG_ 2365394174 Aftrtrtmnt2IntkGsNOxSnsrNO2Crrct "Correction of NO2 at the NOx-signal to correct (recalculate) sensor signal on the Engine ECU side.";
CM_ SG_ 2365394174 Aftrtrtmnt2IntkGsNOxSnsrCrrctnOf "Correction of pressure NOx-signal to correct (recalculate) sensor signal on the Engine ECU side.Correction of pressure Lambda-signal to correct (recalculate) sensor signal on the Engine ECU side.";
CM_ BO_ 2365394430 "Aftertreatment 2 Intake Gas NOx Sensor correction data";
CM_ SG_ 2365394430 Aftrtrtmnt2IntkGsNOxSnsrNwPrtDvt "New part deviation NOx_Offset to correct (recalculate) sensor signal on the Engine ECU side.New part deviation NOx_Gain to correct (recalculate) sensor signal on the Engine ECU side.";
CM_ SG_ 2365394430 Aftrtrtmnt2IntkGsNOxSnsrHtrRatio "Heater ratio to determine temperature at sensor tip.";
CM_ BO_ 2566735102 "Aftertreatment 2 Fuel Control 2";
CM_ SG_ 2566735102 Aftertreatment2FuelPress2Ctrl "Indicates how the device is controlling the aftertreatment 2 fuel pressure 2 regulating control valve. 0% = fully closed,";
CM_ SG_ 2566735102 Aftrtrtmnt2FlFlwDverterValveCtrl "Indicates how the device is controlling the aftertreatment 2 fuel flow diverter valve. When this valve is on it diverts fuel flow";
CM_ SG_ 2566735102 Aftertreatment2FuelPumpRelayCtrl "Indicates how the device is controlling the aftertreatment 2 fuel pump relay.";
CM_ SG_ 2566735102 Aftertreatment2FuelPress2 "Second fuel pressure measurement for the aftertreatment 2 system.";
CM_ BO_ 2157313790 "The purpose of this PGN is to group the Aftertreatment 2 DPF soot measurement calibration parameters. These values";
CM_ SG_ 2157313790 Aftrtrtmnt2DslPrtcltFltrStStndrd "Calibration offset for the soot standard deviation for Aftertreatment 2 Diesel Particulate Filter soot sensor.";
CM_ SG_ 2157313790 Aftrtrtmnt2DslPrtcltFltrStMnClbO "Calibration offset for the soot Mean for Aftertreatment 2 Diesel Particulate Filter soot sensor.";
CM_ BO_ 2566724350 "This PGN contains information for the warm up oxidation catalytic converter in exhaust bank 1.";
CM_ SG_ 2566724350 Aftrtrtmnt1WrmUpDslOxdtnCtlystOt "This is the temperature measured at the outlet of the warm up oxidation catalytic converter in exhaust bank 1.";
CM_ SG_ 2566724350 Aftrtrtmnt1WrmUpDslOxdtnCtlystIn "This is the temperature measured at the intake of the warm up oxidation catalytic converter in exhaust bank 1.";
CM_ BO_ 2566735614 "Aftertreatment 1 Three Way Catalytic Converter";
CM_ SG_ 2566735614 Aftrtrtmnt1ThrWyCtlytcCnvrtrDffP "Used to identify the applicable J1939-73 FMI detected in the Three Way Catalytic Converter differential pressure sensorExhaust differential pressure measured between the intake and exhaust of a Three Way Catalytic Converter in exhaust";
CM_ SG_ 2566735614 Aftrtrtmnt1ThrWyCtlytcCnvrtrOtlt "Used to identify the applicable J1939-73 FMI detected in the Three Way Catalytic Converter outlet gas temperatureTemperature of engine combustion byproducts leaving the Three Way Catalytic Converter in exhaust bank 1.";
CM_ SG_ 2566735614 Aftrtrtmnt1ThrWyCtlytcCnvrtrIntk "Used to identify the applicable J1939-73 FMI detected in the Three Way Catalytic Converter intake gas temperatureTemperature of engine combustion byproducts entering the Three Way Catalytic Converter in exhaust bank 1.";
CM_ BO_ 2566805246 "Contains information on various tank levels";
CM_ SG_ 2566805246 Aftrtrtmnt1SCRCtlystRgntTnk1HtrP "Used to identify the applicable J1939-73 FMI detected in the SCR catalyst reagent tank 1 heater, by the manufacturer’s";
CM_ SG_ 2566805246 AftrtrtmntSCROprtrIndcmntSverity "The severity of operator inducement for anomolies with the SCR system, such as tampering, low DEF quality, and DEF";
CM_ SG_ 2566805246 Aftrtrtmnt1SCRCtlystRgntTnk1TmpP "Used to identify the applicable J1939-73 FMI detected in the SCR catalyst reagent tank 1 temperature, by the";
CM_ SG_ 2566805246 Aftrtrtmnt1DEFTnkLwLvelIndicator "The desired illumination of the driver's warning indicator for diesel exhaust fluid (DEF) tank low level.";
CM_ SG_ 2566805246 Aftrtrtmnt1SCRCtlystTnkLvlPrlmnr "Used to identify the applicable J1939-73 FMI that applies to the most significant failure of the catalyst tank level sensor.";
CM_ SG_ 2566805246 Aftrtrtmnt1SCRCatalystTankLevel2 "The measure of the reagent level in the catalyst tank.";
CM_ SG_ 2566805246 Aftrtratment1SCRCatalystTankTemp "Temperature of the reagent in the storage tank.";
CM_ SG_ 2566805246 Aftrtrtment1SCRCatalystTankLevel "A special catalyst uses a chemical reagent to reach legal requirement for NOX emissions. This parameter indicates the";
CM_ SG_ 2566805246 Aftrtrtmnt1SCRCtalystTankHeater "Percentage of heating applied to the aftertreatment 1 catalyst tank heater.";
CM_ BO_ 2365394686 "Aftertreatment 1 Outlet Gas NOx Sensor correction data 2";
CM_ SG_ 2365394686 Aftrtrtmnt1OtltGsNOxSnsrNH3Crrct "Correction of NH3 at the NOx-signal to correct (recalculate) sensor signal on the Engine ECU side.";
CM_ SG_ 2365394686 Aftrtrtmnt1OtltGsNOxSnsrNO2Crrct "Correction of NO2 at the NOx-signal to correct (recalculate) sensor signal on the Engine ECU side.";
CM_ SG_ 2365394686 Aftrtrtmnt1OtltGsNOxSnsrCrrctnOf "Correction of pressure NOx-signal to correct (recalculate) sensor signal on the Engine ECU side.Correction of pressure Lambda-signal to correct (recalculate) sensor signal on the Engine ECU side.";
CM_ SG_ 2365394942 Aft1OtltGsNOxSnsrNwPrtDvt_Offset "New part deviation NOx_Offset to correct (recalculate) sensor signal on the Engine ECU side.New part deviation NOx_Gain to correct (recalculate) sensor signal on the Engine ECU side.";
CM_ SG_ 2365394942 Aftrtrtmnt1OtltGsNOxSnsrHtrRatio "Heater ratio to determine temperature at sensor tip.";
CM_ SG_ 2365395198 Aftrtrtmnt1IntkGsNOxSnsrNH3Crrct "Correction of NH3 at the NOx-signal to correct (recalculate) sensor signal on the Engine ECU side.";
CM_ SG_ 2365395198 Aftrtrtmnt1IntkGsNOxSnsrNO2Crrct "Correction of NO2 at the NOx-signal to correct (recalculate) sensor signal on the Engine ECU side.";
CM_ SG_ 2365395198 Aftrtrtmnt1IntkGsNOxSnsrCrrctnOf "Correction of pressure NOx-signal to correct (recalculate) sensor signal on the Engine ECU side.Correction of pressure Lambda-signal to correct (recalculate) sensor signal on the Engine ECU side.";
CM_ BO_ 2365395454 "Aftertreatment 1 Intake Gas NOx Sensor correction data";
CM_ SG_ 2365395454 IntkGsNOxSnsrNwPrtDvtOffset "New part deviation NOx_Offset to correct (recalculate) sensor signal on the Engine ECU side.New part deviation NOx_Gain to correct (recalculate) sensor signal on the Engine ECU side.";
CM_ SG_ 2365395454 Aftrtrtmnt1IntkGsNOxSnsrHtrRatio "Heater ratio to determine temperature at sensor tip.";
CM_ BO_ 2157248254 "The purpose of this PGN is to group the Aftertreatment 1 DPF soot measurement calibration parameters. These values";
CM_ SG_ 2157248254 Aftrtrtmnt1DslPrtcltFltrStStndrd "Calibration offset for the soot standard deviation for Aftertreatment 1 Diesel Particulate Filter soot sensor.";
CM_ SG_ 2157248254 Aftrtrtmnt1DslPrtcltFltrStMnClbO "Calibration offset for the soot Mean for Aftertreatment 1 Diesel Particulate Filter soot sensor.";
CM_ BO_ 2566711806 "Operator commands sent via the Armrest Switch Matrices.";
CM_ SG_ 2566711806 ArmrestSwitchMatrix2Switch2 "Second switch input matrix for the second module located in the armrest";
CM_ SG_ 2566711806 ArmrestSwitchMatrix2Switch1 "Switch input matrix for the second module located in the armrest";
CM_ SG_ 2566711806 ArmrestSwitchMatrixSwitch2 "Second switch input matrix for the module located in the armrest";
CM_ SG_ 2566711806 ArmrestSwitchMatrixSwitch1 "Switch input matrix for the module located in the armrest";
CM_ BO_ 2364549886 "The Angular Rate Information message shall provide a measurement of the vehicle's pitch rate, roll rate, and yaw rate";
CM_ SG_ 2364549886 AngularRateMeasurementLatency "The estimated measurement latency of the measurement.";
CM_ SG_ 2364549886 YawRateExRangeFigureOfMerit "Figure of merit for yaw angle measurement.";
CM_ SG_ 2364549886 RollRateExRangeFigureOfMerit "Figure of merit for roll angle measurement.";
CM_ SG_ 2364549886 PitchRateExRangeFigureOfMerit "Figure of merit for pitch angle measurement.";
CM_ SG_ 2364549886 YawRateExRange "Yaw rate is the rate-of-change of the yaw angle over time.";
CM_ SG_ 2364549886 RollRateExRange "Roll rate is the rate-of-change of the roll angle over time.";
CM_ SG_ 2364549886 PitchRateExRange "Pitch rate is the rate-of-change of the pitch angle over time, where the pitch angle vector is in the direction of travel of the";
CM_ BO_ 2566712318 "This message contains NOx adsorber information for aftertreatment system 2 (or bank 2).";
CM_ SG_ 2566712318 Aftrtrtmnt2NOxAdsrbrDSOxRgnrtnSt "Indicates whether the NOx adsorber deSOx regeneration in the second aftertreatment system is active or inactive";
CM_ SG_ 2566712318 Aftrtrtmnt2NOxAdsrbrDNOxRgnrtnSt "Indicates whether the NOx adsorber deNOx regeneration in the second aftertreatment system is active or inactive";
CM_ BO_ 2566712574 "This message contains NOx adsorber information for aftertreatment system 1 (or bank 1).";
CM_ SG_ 2566712574 Aftrtrtmnt1NOxAdsrbrDSOxRgnrtnSt "Indicates whether the NOx adsorber deSOx regeneration in the first aftertreatment system is active or inactive";
CM_ SG_ 2566712574 Aftrtrtmnt1NOxAdsrbrDNOxRgnrtnSt "Indicates whether the NOx adsorber deNOx regeneration in the first aftertreatment system is active or inactive";
CM_ BO_ 2164078590 "Aftertreatment 2 SCR Service Information";
CM_ SG_ 2164078590 Aftrtrtmnt2SCRCtlystCnvrsnEffcnc "The SCR catalyst conversion efficiency percentage. Calculated as 100 times the catalyst intake NOx minus the catalyst";
CM_ SG_ 2164078590 Aftrtrtmnt2SCRCmmnddCtlystRgntCn "This parameter transmits the amount of reagent that the emissions control system has requested to be used, averaged";
CM_ SG_ 2164078590 Aftrtrtmnt2SCRAvrgCtlystRgntCnsm "Measured use of reagent by a Selective Catalytic Reduction system for exhaust emission control, averaged over the";
CM_ BO_ 2566731006 "Aftertreatment 2 SCR Reagant Tank 2 Information";
CM_ SG_ 2566731006 Aftrtrtmnt2SCRCtlystRgntTnk2HtrP "Used to identify the applicable J1939-73 FMI detected in the SCR catalyst reagent tank 2 heater, by the manufacturer’s";
CM_ SG_ 2566731006 Aftrtrtmnt2SCRCtlystRgntTnk2Hter "The SCR catalyst reagent tank 2 heater percentage for aftertreatment system 1 (exhaust bank 1). 0% is off. See SPN";
CM_ SG_ 2566731006 Aftrtrtmnt2SCRRgntTnk2TmpPrlmnry "Used to identify the applicable J1939-73 FMI detected in the SCR catalyst reagent tank 2 temperature, by the";
CM_ SG_ 2566731006 Aftrtrtmnt2SCRCtlystRgntTnk2LvlP "Used to identify the applicable J1939-73 FMI detected in the SCR catalyst reagent tank 2 level, by the manufacturer’s";
CM_ SG_ 2566731006 Aftrtrtmnt2SCRCtlystRgntTnk2Lvl2 "The SCR catalyst reagent tank 2 level height in mm for aftertreatment system 2 (exhaust bank 2). Tank 2 is used as a";
CM_ SG_ 2566731006 Aftrtrtmnt2SCRCtlystRgntTnk2Temp "The SCR catalyst reagent tank 2 temperature for aftertreatment system 2 (exhaust bank 2). Tank 2 is used as a quick";
CM_ SG_ 2566731006 Aftrtrtmnt2SCRCtlystRgntTnk2Lvel "The SCR catalyst reagent tank 2 level percentage for aftertreatment system 2 (exhaust bank 2). 0% is empty and 100%";
CM_ BO_ 2566731262 "Aftertreatment 2 SCR Reagant Tank 1 Information";
CM_ SG_ 2566731262 Aftrtrtmnt2SCRCtlystRgntTnk1HtrP "Used to identify the applicable J1939-73 FMI detected in the SCR catalyst reagent tank 1 heater, by the manufacturer’s";
CM_ SG_ 2566731262 Aftrtrtmnt2SCRCtalystTankHeater "Percentage of heating applied to the aftertreatment 2 catalyst tank heater.";
CM_ SG_ 2566731262 Aftrtrtmnt2SCRCtlystRgntTnk1TmpP "Used to identify the applicable J1939-73 FMI detected in the SCR catalyst reagent tank 1 temperature, by the";
CM_ SG_ 2566731262 Aftrtrtmnt2SCRCtlystTnkLvlPrlmnr "Used to identify the applicable J1939-73 FMI that applies to the most significant failure of the catalyst tank level sensor.";
CM_ SG_ 2566731262 Aftrtrtmnt2SCRCatalystTankLevel2 "The measure of the reagent level in the catalyst tank.";
CM_ SG_ 2566731262 Aftrtratment2SCRCatalystTankTemp "Temperature of the reagent in the storage tank.";
CM_ SG_ 2566731262 Aftrtrtment2SCRCatalystTankLevel "A special catalyst uses chemical substance to reach legal requirement for NOX emissions. This parameter indicates the";
CM_ BO_ 2566730750 "Aftertreatment 2 SCR Reagent Supply Information";
CM_ SG_ 2566730750 Aftrtrtmnt2SCRCtlystRgntTnkDrnVl "Commanded percentage of maximum Aftertreatment 2 SCR Catalyst Reagent Tank Drain Valve opening. 100% means";
CM_ SG_ 2566730750 Aftrtrtmnt2SCRCtlystRgntPmpState "State of aftertreatment 2 SCR Catalyst Reagent dosing pump.";
CM_ SG_ 2566730750 Aftrtrtmnt2SCRCtlystRgntTnkFllVl "Commanded percentage of maximum Aftertreatment 2 SCR Catalyst Reagent Tank Fill Valve opening. 100% means the";
CM_ SG_ 2566730750 Aftrtrtmnt2SCRCtlystRgntRtrnVlve "Command to the valve which determines whether the reagent is delivered to the injector or is routed back to the reagent";
CM_ SG_ 2566730750 Aftrtrtmnt2SCRCtlystRgntPmpDrvPr "The percent (command) sent to the motor to control the speed of the reagent pump.";
CM_ SG_ 2566730750 Aftrtrtmnt2SCRCtlystRgntPmpMtrSp "Rotational speed of the motor driving a pump for reagent used in an aftertreatment system.";
CM_ BO_ 2566731518 "Aftertreatment 2 SCR Reagent Information";
CM_ SG_ 2566731518 Aftrtrtmnt2SCRCtalystReagentType "This parameter indicates what reagent is in the tank. A value of 0011 indicates uncontaminated Diesel Exhaust Fluid.";
CM_ SG_ 2566731518 Aftrtrtmnt2SCRCtlystRgntPrprtsPr "Used to identify the applicable J1939-73 FMI that applies to the most significant failure of the catalyst reagent properties";
CM_ SG_ 2566731518 Aftrtrtmnt2SCRCtlystRgntTmp2Prlm "Used to identify the applicable J1939-73 FMI that applies to the most significant failure of the catalyst temperature sensor.";
CM_ SG_ 2566731518 Aftrtrtmnt2SCRCtlystRgntCndctvty "A measure of the conductivity of the reagent or fluid at the sensor. The conductivity is an indication of the reagent's";
CM_ SG_ 2566731518 Aftrtrtmnt2SCRCtlystRgntCncntrtn "A measure of the concentration of urea in water. Zero percent means that the tank contains no urea. A 32.5% value";
CM_ SG_ 2566731518 Aftrtrtmnt2SCRCtlystReagentTemp2 "Temperature of the catalyst reagent at the device measuring reagent quality";
CM_ BO_ 2566732030 "Aftertreatment 2 SCR Exhaust Gas Temperature";
CM_ SG_ 2566732030 Aftrtrtmnt2SCRCtlystOtltGsTmpPrl "Used to identify the applicable J1939-73 FMI detected in the SCR catalyst outlet gas temperature sensor by the";
CM_ SG_ 2566732030 Aftrtrtmnt2SCRCtlystOtletGasTemp "Temperature of engine combustion byproducts leaving the SCR catalyst exhaust in exhaust bank 2.";
CM_ SG_ 2566732030 Aftrtrtmnt2SCRCtlystIntkGsTmpPrl "Used to identify the applicable J1939-73 FMI detected in the SCR catalyst intake gas temperature sensor by the";
CM_ SG_ 2566732030 Aftrtrtmnt2SCRCtlystIntkeGasTemp "Temperature of engine combustion byproducts entering the SCR catalyst in exhaust bank 2.";
CM_ BO_ 2566732286 "Aftertreatment 2 SCR Exhaust Gas Pressures";
CM_ SG_ 2566732286 SCRCtlystExhstGsDffPr_PerlimFMI "Used to identify the applicable J1939-73 FMI detected in the SCR catalyst differential pressure sensor by theExhaust differential pressure measured between the intake and exhaust of a SCR catalyst in exhaust bank 2.";
CM_ BO_ 2164079358 "Aftertreatment 2 SCR Dosing System Requests 2";
CM_ SG_ 2164079358 Aftrtrtmnt2SCRCtlystTnk2HaterCmd "This is the command for the Aftertreatment 2 SCR Catalyst Tank 2 Heater. See SPN 4438 for the measured value of the";
CM_ SG_ 2164079358 Aftrtrtmnt2SCRCtlystTnkHeaterCmd "Command for the Aftertreatment 2 SCR Catalyst Tank Heater. A value of 0% means no heating applied, a value of 100%";
CM_ SG_ 2164079358 Aftrtrtmnt2SCRCtlystRgntLnHater4 "The SCR catalyst reagent line heater 4 request for aftertreatment system 2 (exhaust bank 2).";
CM_ SG_ 2164079358 Aftrtrtmnt2SCRCtlystRgntLnHater3 "The SCR catalyst reagent line heater 3 request for aftertreatment system 2 (exhaust bank 2).";
CM_ SG_ 2164079358 Aftrtrtmnt2SCRCtlystRgntLnHater2 "The SCR catalyst reagent line heater 2 request for aftertreatment system 2 (exhaust bank 2).";
CM_ SG_ 2164079358 Aftrtrtmnt2SCRCtlystRgntLnHater1 "The SCR catalyst reagent line heater 1 request for aftertreatment system 2 (exhaust bank 2).";
CM_ SG_ 2164079358 Aftrtrtmnt2SCRDoserHeatingModeRq "Used if multiple heater modes are available in the Doser.";
CM_ SG_ 2164079358 Aftrtrtmnt2SCRDsrFltSppressionRq "Used if external devices can warn of conditions that require suppression of potential faults in the doser due to";
CM_ BO_ 2364549118 "This message contains SCR dosing system request information for aftertreatment system 2 (or bank 2).";
CM_ SG_ 2364549118 Aftrtrtmnt2SCRRqstdRgntQnttyFrIn "Represents the command for the reducing agent quantity integrator in the dosing control unit";
CM_ SG_ 2364549118 Aftrtrtmnt2SCRSystmRquestedState "Requested state of SCR system for aftertreatment system 2 (exhaust bank 2).";
CM_ SG_ 2364549118 Aftrtrtmnt2SCRRqstdDsngRgntQntty "Actual requested dosing quantity of catalyst reagent";
CM_ BO_ 2566732798 "Aftertreatment 2 SCR Dosing System Information 2";
CM_ SG_ 2566732798 Aftrtrtmnt2SCRCtlystRgntLnHtr4Pr "Used to identify the applicable J1939-73 FMI detected in the SCR catalyst reagent line heater 4, by the manufacturer’s";
CM_ SG_ 2566732798 Aftrtrtmnt2SCRCtlystRgntLnHtr4St "The SCR catalyst reagent line heater 4 state for aftertreatment system 2 (exhaust bank 2).";
CM_ SG_ 2566732798 Aftrtrtmnt2SCRCtlystRgntLnHtr3Pr "Used to identify the applicable J1939-73 FMI detected in the SCR catalyst reagent line heater 3, by the manufacturer’s";
CM_ SG_ 2566732798 Aftrtrtmnt2SCRCtlystRgntLnHtr3St "The SCR catalyst reagent line heater 3 state for aftertreatment system 2 (exhaust bank 2).";
CM_ SG_ 2566732798 Aftrtrtmnt2SCRCtlystRgntLnHtr2Pr "Used to identify the applicable J1939-73 FMI detected in the SCR catalyst reagent line heater 2, by the manufacturer’s";
CM_ SG_ 2566732798 Aftrtrtmnt2SCRCtlystRgntLnHtr2St "The SCR catalyst reagent line heater 2 state for aftertreatment system 2 (exhaust bank 2).";
CM_ SG_ 2566732798 Aftrtrtmnt2SCRCtlystRgntLnHtr1Pr "Used to identify the applicable J1939-73 FMI detected in the SCR catalyst reagent line heater 1, by the manufacturer’s";
CM_ SG_ 2566732798 Aftrtrtmnt2SCRCtlystRgntLnHtr1St "The SCR catalyst reagent line heater 1 state for aftertreatment system 2 (exhaust bank 2).";
CM_ SG_ 2566732798 Aftrtrtmnt2SCRFeedbackCtrlStatus "The SCR feedback control status (open/closed loop) for aftertreatment system 2 (exhaust bank 2).";
CM_ SG_ 2566732798 Aftrtrtmnt2SCRDsngVlvExhstTmpRdc "Protection request for the dosing valve of the SCR-system to prevent overheating";
CM_ SG_ 2566732798 Aftrtrtment2SCRDosingReagentTemp "The SCR dosing reagent temperature (measured closest to dosing valve) for aftertreatment system 2 (exhaust bank 2).";
CM_ SG_ 2566732798 Aftrtrtmnt2SCRDsngAirAssistValve "The position of the valve used to regulate the air supply of an air assist SCR dosing system for an engine. 0% represents";
CM_ SG_ 2566732798 Aftrtrtmnt2SCRDsngArAssstAbsPrss "The SCR dosing system air assist absolute pressure for aftertreatment system 2 (exhaust bank 2). The air assist system";
CM_ BO_ 2364548862 "This message contains SCR dosing system information for aftertreatment system 2 (or bank 2). See PGN 64827 for";
CM_ SG_ 2364548862 Aftrtrtmnt2SCRDsngRagentAbsPress "The SCR dosing reagent absolute pressure (measured closest to dosing valve) for aftertreatment system 2 (exhaust bank";
CM_ SG_ 2364548862 Aftrtrtmnt2SCRActlRgntQnttyOfInt "The SCR requested reagent integrator total quantity for aftertreatment system 2 (exhaust bank 2).";
CM_ SG_ 2364548862 Aftertreatment2SCRSystemState "Actual state of SCR system";
CM_ SG_ 2364548862 Aftrtrtmnt2SCRActlDsngRgntQntity "Actual reducing agent quantity of SCR system.";
CM_ BO_ 2364549374 "This message contains outlet ammonia information for aftertreatment system 2 (or bank 2).";
CM_ SG_ 2364549374 Aftrtrtmnt2OtltNH3GsSnsrHterCtrl "Indicates the heater status in the warm-up process. Upon receiving a power-up command, the NH3 gas sensor ramps up";
CM_ SG_ 2364549374 Aftrtrtmnt2OtltNH3GsSnsrHtrPrlmn "Used to identify the applicable J1939-73 FMI detected in the heater of the outlet NH3 exhaust gas sensor by the";
CM_ SG_ 2364549374 Aftrtrtmnt2OtltNH3GsSensorAtTemp "Indicates that the heater element of the aftertreatment outlet NH3 gas sensor is within the manufacturer’s specified range";
CM_ SG_ 2364549374 Aftrtrtmnt2OtltNH3GsSnsrPwrInRng "Indicates that the power supplied to the aftertreatment outlet NH3 gas sensor is within the manufacturer’s specification in";
CM_ SG_ 2364549374 Aftrtrtmnt2OtletNH3ReadingStable "Indicates that the NH3 reading of the aftertreatment outlet NH3 sensor is stable as determined by the manufacturer’s";
CM_ SG_ 2364549374 Aftrtrtmnt2OtltNH3SnsrPrlmnryFMI "Used to identify the applicable J1939-73 FMI detected in the aftertreatment outlet NH3 sensor by the manufacturer’s";
CM_ SG_ 2364549374 Aftertreatment2OutletNH3 "The amount of NH3 in the exhaust exiting the aftertreatment system measured by a NH3 sensor at the aftertreatment";
CM_ BO_ 2566726142 "Aftertreatment 2 Gas Oxidation Catalyst";
CM_ SG_ 2566726142 GsOxdtnCtlystDffPrssP_PerlimFMI "Used to identify the applicable J1939-73 FMI detected in the gas oxidation catalyst differential pressure sensor by the";
CM_ SG_ 2566726142 GsOxdtnCtlystOtltGsTm_PerlimFMI "Used to identify the applicable J1939-73 FMI detected in the gas oxidation catalyst outlet gas temperature sensor by theTemperature of engine combustion byproducts leaving the gas oxidation catalyst in exhaust bank 2. This gas parameter";
CM_ SG_ 2566726142 GsOxdtnCtlystIntkGsTm_PerlimFMI "Used to identify the applicable J1939-73 FMI detected in the gas oxidation catalyst intake gas temperature sensor by theTemperature of engine combustion byproducts entering the gas oxidation catalyst in exhaust bank 2. This gas parameter";
CM_ SG_ 2566726142 Aftrtrtmnt2GsOxdtnCtlystDffPress "Exhaust differential pressure measured between the intake and exhaust of the gas oxidation catalyst in exhaust bank 2.";
CM_ BO_ 2566725630 "Aftertreatment 2 Diesel Oxidation Catalyst";
CM_ SG_ 2566725630 DslOxdtnCtlystOtltGsT_PerlimFMI "Used to identify the applicable J1939-73 FMI detected in the diesel oxidation catalyst outlet gas temperature sensor byTemperature of engine combustion byproducts leaving the diesel oxidation catalyst exhaust in exhaust bank 2. This";
CM_ SG_ 2566725630 DslOxdtnCtlystIntkGsT_PerlimFMI "Used to identify the applicable J1939-73 FMI detected in the diesel oxidation catalyst intake gas temperature sensor byTemperature of engine combustion byproducts entering the diesel oxidation catalyst in exhaust bank 2. This diesel";
CM_ SG_ 2566725630 Aftrtrtmnt2DslOxdtnCtlystDffPrss "Exhaust differential pressure measured between the intake and exhaust of a diesel oxidation catalyst in exhaust bank 2.Used to identify the applicable J1939-73 FMI detected in the diesel oxidation catalyst differential pressure sensor by the";
CM_ BO_ 2566733310 "Aftertreatment 1 SCR Reagant Tank 2 Information";
CM_ SG_ 2566733310 Aftrtrtmnt1SCRCtlystRgntTnk2HtrP "Used to identify the applicable J1939-73 FMI detected in the SCR catalyst reagent tank 2 heater, by the manufacturer’s";
CM_ SG_ 2566733310 Aftrtrtmnt1SCRCtlystRgntTnk2Hter "The SCR catalyst reagent tank 2 heater percentage for aftertreatment system 1 (exhaust bank 1). 0% is off. See SPN";
CM_ SG_ 2566733310 Aftrtrtmnt1SCRRgntTnk2TmpPrlmnry "Used to identify the applicable J1939-73 FMI detected in the SCR catalyst reagent tank 2 temperature, by the";
CM_ SG_ 2566733310 Aftrtrtmnt1SCRCtlystRgntTnk2LvlP "Used to identify the applicable J1939-73 FMI detected in the SCR catalyst reagent tank 2 level, by the manufacturer’s";
CM_ SG_ 2566733310 Aftrtrtmnt1SCRCtlystRgntTnk2Lvl2 "The SCR catalyst reagent tank 2 level height in mm for aftertreatment system 1 (exhaust bank 1). Tank 2 is used as a";
CM_ SG_ 2566733310 Aftrtrtmnt1SCRCtlystRgntTnk2Temp "The SCR catalyst reagent tank 2 temperature for aftertreatment system 1 (exhaust bank 1). Tank 2 is used as a quick";
CM_ SG_ 2566733310 Aftrtrtmnt1SCRCtlystRgntTnk2Lvel "The SCR catalyst reagent tank 2 level percentage for aftertreatment system 1 (exhaust bank 1). 0% is empty and 100%";
CM_ BO_ 2566733054 "Aftertreatment 1 SCR Reagent Supply Information";
CM_ SG_ 2566733054 Aftrtrtmnt1SCRCtlystRgntTnkDrnVl "Commanded percentage of maximum Aftertreatment 1 SCR Catalyst Reagent Tank Drain Valve opening. 100% means";
CM_ SG_ 2566733054 Aftrtrtmnt1SCRCtlystRgntPmpState "State of aftertreatment 1 SCR Catalyst Reagent dosing pump.";
CM_ SG_ 2566733054 Aftrtrtmnt1SCRCtlystRgntTnkFllVl "Commanded percentage of maximum Aftertreatment 1 SCR Catalyst Reagent Tank Fill Valve opening. 100% means the";
CM_ SG_ 2566733054 Aftrtrtmnt1SCRCtlystRgntRtrnVlve "Command to the valve which determines whether the reagent is delivered to the injector or is routed back to the reagent";
CM_ SG_ 2566733054 Aftrtrtmnt1SCRCtlystRgntPmpDrvPr "The percent (command) sent to the motor to control the speed of the reagent pump.";
CM_ SG_ 2566733054 Aftrtrtmnt1SCRCtlystRgntPmpMtrSp "Rotational speed of the motor driving a pump for reagent used in an aftertreatment system.";
CM_ BO_ 2499624702 "Aftertreatment 1 SCR Exhaust Gas Temperature";
CM_ SG_ 2499624702 Aftrtrtmnt1SCRCtlystOtltGsTmpPrl "Used to identify the applicable J1939-73 FMI detected in the SCR catalyst outlet gas temperature sensor by the";
CM_ SG_ 2499624702 Aftrtrtmnt1SCRCtlystOtletGasTemp "Temperature of engine combustion byproducts leaving the SCR catalyst exhaust in exhaust bank 1.";
CM_ SG_ 2499624702 Aftrtrtmnt1SCRCtlystIntkGsTmpPrl "Used to identify the applicable J1939-73 FMI detected in the SCR catalyst intake gas temperature sensor by the";
CM_ SG_ 2499624702 Aftrtrtmnt1SCRCtlystIntkeGasTemp "Temperature of engine combustion byproducts entering the SCR catalyst in exhaust bank 1.";
CM_ BO_ 2566733822 "Aftertreatment 1 SCR Exhaust Gas Pressures";
CM_ SG_ 2566733822 SCRCtlystExhstGsDffPr_PrelimFMI "Used to identify the applicable J1939-73 FMI detected in the SCR catalyst differential pressure sensor by theExhaust differential pressure measured between the intake and exhaust of a SCR catalyst in exhaust bank 1.";
CM_ BO_ 2566734078 "Aftertreatment 1 SCR Dosing System Requests 2";
CM_ SG_ 2566734078 Aftrtrtmnt1SCRCtlystTnk2HaterCmd "This is the command for the Aftertreatment 1 SCR Catalyst Tank 2 Heater. See SPN 4372 for the measured value of the";
CM_ SG_ 2566734078 Aftrtrtmnt1SCRCtlystTnkHeaterCmd "Command for the Aftertreatment 1 SCR Catalyst Tank Heater. A value of 0% means no heating applied, a value of 100%";
CM_ SG_ 2566734078 Aftrtrtmnt1SCRCtlystRgntLnHater4 "The SCR catalyst reagent line heater 4 request for aftertreatment system 1 (exhaust bank 1).";
CM_ SG_ 2566734078 Aftrtrtmnt1SCRCtlystRgntLnHater3 "The SCR catalyst reagent line heater 3 request for aftertreatment system 1 (exhaust bank 1).";
CM_ SG_ 2566734078 Aftrtrtmnt1SCRCtlystRgntLnHater2 "The SCR catalyst reagent line heater 2 request for aftertreatment system 1 (exhaust bank 1).";
CM_ SG_ 2566734078 Aftrtrtmnt1SCRCtlystRgntLnHater1 "The SCR catalyst reagent line heater 1 request for aftertreatment system 1 (exhaust bank 1).";
CM_ SG_ 2566734078 Aftrtrtmnt1SCRDoserHeatingModeRq "Used if multiple heater modes are available in the Doser.";
CM_ SG_ 2566734078 Aftrtrtmnt1SCRDsrFltSppressionRq "Used if external devices can warn of conditions that require suppression of potential faults in the doser due to";
CM_ BO_ 2364548350 "This message contains SCR dosing system request information for aftertreatment system 1 (or bank 1). See PGN 64832";
CM_ SG_ 2364548350 Aftrtrtmnt1SCRRqstdRgntQnttyFrIn "Represents the command for the reducing agent quantity integrator in the dosing control unit";
CM_ SG_ 2364548350 Aftrtrtmnt1SCRSystmRquestedState "Requested state of SCR system for aftertreatment system 1 (exhaust bank 1).";
CM_ SG_ 2364548350 Aftrtrtmnt1SCRRqstdDsngRgntQntty "Actual requested dosing quantity of catalyst reagent";
CM_ BO_ 2566734334 "Aftertreatment 1 SCR Dosing System Information 2";
CM_ SG_ 2566734334 Aftrtrtmnt1SCRCtlystRgntLnHtr4Pr "Used to identify the applicable J1939-73 FMI detected in the SCR catalyst reagent line heater 4, by the manufacturer’s";
CM_ SG_ 2566734334 Aftrtrtmnt1SCRCtlystRgntLnHtr4St "The SCR catalyst reagent line heater 4 state for aftertreatment system 1 (exhaust bank 1).";
CM_ SG_ 2566734334 Aftrtrtmnt1SCRCtlystRgntLnHtr3Pr "Used to identify the applicable J1939-73 FMI detected in the SCR catalyst reagent line heater 3, by the manufacturer’s";
CM_ SG_ 2566734334 Aftrtrtmnt1SCRCtlystRgntLnHtr3St "The SCR catalyst reagent line heater 3 state for aftertreatment system 1 (exhaust bank 1).";
CM_ SG_ 2566734334 Aftrtrtmnt1SCRCtlystRgntLnHtr2Pr "Used to identify the applicable J1939-73 FMI detected in the SCR catalyst reagent line heater 2, by the manufacturer’s";
CM_ SG_ 2566734334 Aftrtrtmnt1SCRCtlystRgntLnHtr2St "The SCR catalyst reagent line heater 2 state for aftertreatment system 1 (exhaust bank 1).";
CM_ SG_ 2566734334 Aftrtrtmnt1SCRCtlystRgntLnHtr1Pr "Used to identify the applicable J1939-73 FMI detected in the SCR catalyst reagent line heater 1, by the manufacturer’s";
CM_ SG_ 2566734334 Aftrtrtmnt1SCRCtlystRgntLnHtr1St "The SCR catalyst reagent line heater 1 state for aftertreatment system 1 (exhaust bank 1).";
CM_ SG_ 2566734334 Aftrtrtmnt1SCRFeedbackCtrlStatus "The SCR feedback control status (open/closed loop) for aftertreatment system 1 (exhaust bank 1).";
CM_ SG_ 2566734334 Aftrtrtmnt1SCRDsngVlvExhstTmpRdc "Protection request for the dosing valve of the SCR-system to prevent overheating";
CM_ SG_ 2566734334 Aftrtrtment1SCRDosingReagentTemp "The SCR dosing reagent temperature (measured closest to dosing valve) for aftertreatment system 1 (exhaust bank 1).";
CM_ SG_ 2566734334 Aftrtrtmnt1SCRDsngAirAssistValve "The position of the valve used to regulate the air supply of an air assist SCR dosing system for an engine. 0% represents";
CM_ SG_ 2566734334 Aftrtrtmnt1SCRDsngArAssstAbsPrss "The SCR dosing system air assist absolute pressure for aftertreatment system 1 (exhaust bank 1). The air assist system";
CM_ BO_ 2364548094 "This message contains SCR dosing system information for aftertreatment system 1 (or bank 1). See PGN 64833 for";
CM_ SG_ 2364548094 Aftrtrtmnt1SCRDsngRagentAbsPress "The SCR dosing reagent absolute pressure (measured closest to dosing valve) for aftertreatment system 1 (exhaust bank";
CM_ SG_ 2364548094 Aftrtrtmnt1SCRActlRgntQnttyOfInt "The SCR requested reagent integrator total quantity for aftertreatment system 1 (exhaust bank 1).";
CM_ SG_ 2364548094 Aftertreatment1SCRSystemState "Actual state of SCR system";
CM_ SG_ 2364548094 Aftrtrtmnt1SCRActlDsngRgntQntity "Actual reducing agent quantity of SCR-system";
CM_ BO_ 2364548606 "This message contains aftertreatment outlet ammonia information for aftertreatment system 1 (or bank 1).";
CM_ SG_ 2364548606 Aftrtrtmnt1OtltNH3GsSnsrHterCtrl "Indicates the heater status in the warm-up process. Upon receiving a power-up command, the NH3 gas sensor ramps up";
CM_ SG_ 2364548606 Aftrtrtmnt1OtltNH3GsSnsrHtrPrlmn "Used to identify the applicable J1939-73 FMI detected in the heater of the outlet NH3 exhaust gas sensor by the";
CM_ SG_ 2364548606 Aftrtrtmnt1OtltNH3GsSensorAtTemp "Indicates that the heater element of the aftertreatment outlet NH3 gas sensor is within the manufacturer’s specified range";
CM_ SG_ 2364548606 Aftrtrtmnt1OtltNH3GsSnsrPwrInRng "Indicates that the power supplied to the aftertreatment outlet NH3 gas sensor is within the manufacturer’s specification in";
CM_ SG_ 2364548606 Aftrtrtmnt1OtletNH3ReadingStable "Indicates that the NH3 reading of the aftertreatment outlet NH3 sensor is stable as determined by the manufacturer’s";
CM_ SG_ 2364548606 Aftrtrtmnt1OtltNH3SnsrPrlmnryFMI "Used to identify the applicable J1939-73 FMI detected in the aftertreatment outlet NH3 sensor by the manufacturer’s";
CM_ SG_ 2364548606 Aftertreatment1OutletNH3 "The amount of NH3 in the exhaust exiting the aftertreatment system measured by a NH3 sensor at the aftertreatment";
CM_ BO_ 2566726398 "Aftertreatment 1 Gas Oxidation Catalyst";
CM_ SG_ 2566726398 GsOxdtnCtlystDffPrssP_PerlimFMI "Used to identify the applicable J1939-73 FMI detected in the gas oxidation catalyst differential pressure sensor by the";
CM_ SG_ 2566726398 GsOxdtnCtlystOtltGsTm_PerlimFMI "Used to identify the applicable J1939-73 FMI detected in the gas oxidation catalyst outlet gas temperature sensor by theTemperature of engine combustion byproducts leaving the gas oxidation catalyst in exhaust bank 1. This gas parameter";
CM_ SG_ 2566726398 GsOxdtnCtlystIntkGsTm_PerlimFMI "Used to identify the applicable J1939-73 FMI detected in the gas oxidation catalyst intake gas temperature sensor by theTemperature of engine combustion byproducts entering the gas oxidation catalyst in exhaust bank 1. This gas parameter";
CM_ SG_ 2566726398 Aftrtrtmnt1GsOxdtnCtlystDffPress "Exhaust differential pressure measured between the intake and exhaust of the gas oxidation catalyst in exhaust bank 1.";
CM_ BO_ 2566742270 "HB1C provides the system specific individual B1 failure counters";
CM_ SG_ 2566742270 FailureSpecificB1Counter "The Failure Specific B1 Counter provides an individual B1 counter";
CM_ SG_ 2566742270 FailureModeIdentifier1 "The FMI defines the type of failure detected in the subsystem identified by an SPN.";
CM_ SG_ 2566742270 SPN1High "SPN #1 (Conversion Version 4)";
CM_ SG_ 2566742270 SPN1 "SPN #1 (Conversion Version 4)";
CM_ BO_ 2566742526 "Cumulative Continuous MI-System";
CM_ SG_ 2566742526 SysGreatestB1Counter "System Greatest B1 Counter";
CM_ SG_ 2566742526 SysCumulativeContinuousMITime "System Cumulative Continuous MI Time";
CM_ BO_ 2566742782 "Harmonized Global Regulation Description";
CM_ SG_ 2566742782 RegulationDescription "Global Technical Regulation Description";
CM_ BO_ 2566743038 "Harmonized Roadworthiness";
CM_ SG_ 2566743038 SysIncompleteMonitorCount "System Incomplete Monitor Count";
CM_ SG_ 2566743038 SysMalIndActivationMode "System Malfunction Indicator Status";
CM_ SG_ 2566743038 SysMalIndDisplayStrategy "System Malfunction Indicator Display";
CM_ SG_ 2566743038 SysContinuousMalfunctionInd "System Continuous Malfunction Indicator";
CM_ SG_ 2566743038 SysNonRoadworthyCompCount "System Non-Roadworthy Component Count";
CM_ BO_ 2566743294 "Harmonized Roadworthiness ";
CM_ SG_ 2566743294 VehicleCurrentMIAccumTime "Vehicle Current MI Accumulated Time";
CM_ SG_ 2566743294 VehicleIncompleteMonitorCount "Vehicle Incomplete Monitor Count";
CM_ SG_ 2566743294 VehicleMalfunctionIndActMode "Vehicle Malfunction Indicator Status ";
CM_ SG_ 2566743294 VehicleMalfunctionIndStrategy "Vehicle Malfunction Indicator Display Strategy ";
CM_ SG_ 2566743294 VehicleContinuousMalfunctionInd "Vehicle Continuous Malfunction Indicator";
CM_ SG_ 2566743294 VehicleNonRoadworthyCompCount "Vehicle Non-Roadworthy Component Count";
CM_ BO_ 2560687870 "The status of engine operating in the NTE control areas for given pollutants, such as NOx and PM";
CM_ SG_ 2560687870 PMNTEDeficiencyAreaStatus "Status of engine operation within the PM NTE Deficiency Area";
CM_ SG_ 2560687870 MnfcPMNTECarveOutAreaStatus "Status of engine operation within the manufacturer specific PM NTE carve out area";
CM_ SG_ 2560687870 PMNTEControlAreaStatus "Status of engine operation within the bounded region of the engine's torque and speed map.";
CM_ SG_ 2560687870 NOxNTEDeficiencyAreaStatus "Status of engine operation within the NOx NTE Deficiency Area";
CM_ SG_ 2560687870 MnfcNOxNTECarveOutAreaStatus "Status of engine operation within the bounded region of the engine's torque and speed map.";
CM_ SG_ 2560687870 NOxNTEControlAreaStatus "Status of engine operation within the bounded region of the engine's torque and speed map.";
CM_ BO_ 2292317950 "The total engine run time while each of the Emission Increasing Auxiliary Emission Control Devices is active";
CM_ SG_ 2292317950 AECDEngineHours1Timer2 "The total engine running hours recorded in the second timer for the EI-AECD";
CM_ SG_ 2292317950 AECDEngineHours1Timer1 "The total engine running hours recorded in the first timer for the EI-AECD";
CM_ SG_ 2292317950 AECDNumber1 "The manufacturer assigned number for the specific EI-AECD";
CM_ BO_ 2566809342 "Tr";
CM_ SG_ 2566809342 BatteryMainSwitchHoldState "Parameter indicating whether the battery main switch is held due to an external request or not. The state battery main";
BA_DEF_ BO_  "GenMsgCycleTimeFast" INT 0 3600000;
BA_DEF_ SG_  "SigType" ENUM  "Default","Range","RangeSigned","ASCII","Discrete","Control","ReferencePGN","DTC","StringDelimiter","StringLength","StringLengthControl";
BA_DEF_ SG_  "GenSigStartValue" INT 0 10000;
BA_DEF_ SG_  "GenSigSendType" ENUM  "Cyclic","OnWrite","reserved","OnChange","reserved","reserved","reserved","NoSigSendType";
BA_DEF_ SG_  "GenSigILSupport" ENUM  "Yes","No";
BA_DEF_ SG_  "GenSigEVName" STRING ;
BA_DEF_ SG_  "SPN" INT 0 524287;
BA_DEF_ SG_  "DDI" INT 0 65535;
BA_DEF_ SG_  "SAEDocument" STRING ;
BA_DEF_ BO_  "GenMsgStartDelayTime" INT 0 100000;
BA_DEF_ BO_  "GenMsgILSupport" ENUM  "Yes","No";
BA_DEF_ BO_  "GenMsgRequestable" INT 0 1;
BA_DEF_ BO_  "GenMsgSendType" ENUM  "cyclic","reserved","cyclicIfActive","reserved","reserved","reserved","reserved","reserved","noMsgSendType";
BA_DEF_ BO_  "VFrameFormat" ENUM  "StandardCAN","ExtendedCAN","reserved","J1939PG";
BA_DEF_ BO_  "SingleFrame" INT 0 1;
BA_DEF_ BO_  "GenMsgCycleTime" INT 0 3600000;
BA_DEF_ BO_  "SAE_Document" STRING ;
BA_DEF_ SG_  "SystemSignalLongSymbol" STRING ;
BA_DEF_DEF_  "GenMsgCycleTimeFast" 0;
BA_DEF_DEF_  "SigType" "Default";
BA_DEF_DEF_  "GenSigStartValue" 0;
BA_DEF_DEF_  "GenSigSendType" "NoSigSendType";
BA_DEF_DEF_  "GenSigILSupport" "Yes";
BA_DEF_DEF_  "GenSigEVName" "Env@Nodename_@Signame";
BA_DEF_DEF_  "SPN" 0;
BA_DEF_DEF_  "DDI" 0;
BA_DEF_DEF_  "SAEDocument" "";
BA_DEF_DEF_  "GenMsgStartDelayTime" 0;
BA_DEF_DEF_  "GenMsgILSupport" "Yes";
BA_DEF_DEF_  "GenMsgRequestable" 1;
BA_DEF_DEF_  "GenMsgSendType" "noMsgSendType";
BA_DEF_DEF_  "VFrameFormat" "J1939PG";
BA_DEF_DEF_  "SingleFrame" 1;
BA_DEF_DEF_  "GenMsgCycleTime" 0;
BA_DEF_DEF_  "SAE_Document" "";
BA_DEF_DEF_  "SystemSignalLongSymbol" "";
BA_ "GenMsgSendType" BO_ 2365401854 0;
BA_ "GenMsgCycleTime" BO_ 2365401854 100;
BA_ "SAE_Document" BO_ 2365401854 "J1939-71";
BA_ "GenMsgSendType" BO_ 2365402366 0;
BA_ "GenMsgCycleTime" BO_ 2365402366 100;
BA_ "SAE_Document" BO_ 2365402366 "J1939-71";
BA_ "GenMsgSendType" BO_ 2365402878 0;
BA_ "GenMsgCycleTime" BO_ 2365402878 100;
BA_ "SAE_Document" BO_ 2365402878 "J1939-71";
BA_ "GenMsgSendType" BO_ 2365403390 0;
BA_ "GenMsgCycleTime" BO_ 2365403390 100;
BA_ "SAE_Document" BO_ 2365403390 "J1939-71";
BA_ "GenMsgSendType" BO_ 2365400318 0;
BA_ "GenMsgCycleTime" BO_ 2365400318 100;
BA_ "SAE_Document" BO_ 2365400318 "J1939-71";
BA_ "GenMsgSendType" BO_ 2499614718 0;
BA_ "GenMsgCycleTime" BO_ 2499614718 250;
BA_ "SAE_Document" BO_ 2499614718 "J1939-71";
BA_ "GenMsgSendType" BO_ 2566722814 0;
BA_ "GenMsgCycleTime" BO_ 2566722814 1000;
BA_ "SAE_Document" BO_ 2566722814 "J1939-71";
BA_ "GenMsgSendType" BO_ 2566723070 0;
BA_ "GenMsgCycleTime" BO_ 2566723070 1000;
BA_ "SAE_Document" BO_ 2566723070 "J1939-71";
BA_ "SAE_Document" BO_ 2566725118 "J1939-71";
BA_ "SAE_Document" BO_ 2566725374 "J1939-71";
BA_ "GenMsgSendType" BO_ 2566712830 0;
BA_ "GenMsgCycleTime" BO_ 2566712830 500;
BA_ "SAE_Document" BO_ 2566712830 "J1939-71";
BA_ "GenMsgSendType" BO_ 2566735358 0;
BA_ "GenMsgCycleTime" BO_ 2566735358 500;
BA_ "SAE_Document" BO_ 2566735358 "J1939-71";
BA_ "SAE_Document" BO_ 2365393662 "J1939-71";
BA_ "SAE_Document" BO_ 2365393918 "J1939-71";
BA_ "SAE_Document" BO_ 2365394174 "J1939-71";
BA_ "SAE_Document" BO_ 2365394430 "J1939-71";
BA_ "GenMsgSendType" BO_ 2566735102 0;
BA_ "GenMsgCycleTime" BO_ 2566735102 500;
BA_ "SAE_Document" BO_ 2566735102 "J1939-71";
BA_ "SAE_Document" BO_ 2157313790 "J1939-71";
BA_ "GenMsgSendType" BO_ 2566724350 0;
BA_ "GenMsgCycleTime" BO_ 2566724350 500;
BA_ "SAE_Document" BO_ 2566724350 "J1939-71";
BA_ "GenMsgSendType" BO_ 2566735614 0;
BA_ "GenMsgCycleTime" BO_ 2566735614 500;
BA_ "SAE_Document" BO_ 2566735614 "J1939-71";
BA_ "GenMsgSendType" BO_ 2566805246 0;
BA_ "GenMsgCycleTime" BO_ 2566805246 1000;
BA_ "SAE_Document" BO_ 2566805246 "J1939-71";
BA_ "SAE_Document" BO_ 2365394686 "J1939-71";
BA_ "SAE_Document" BO_ 2365394942 "J1939-71";
BA_ "SAE_Document" BO_ 2365395198 "J1939-71";
BA_ "SAE_Document" BO_ 2365395454 "J1939-71";
BA_ "SAE_Document" BO_ 2157248254 "J1939-71";
BA_ "GenMsgSendType" BO_ 2566711806 0;
BA_ "GenMsgCycleTime" BO_ 2566711806 100;
BA_ "SAE_Document" BO_ 2566711806 "J1939-71";
BA_ "GenMsgSendType" BO_ 2364549886 0;
BA_ "GenMsgCycleTime" BO_ 2364549886 10;
BA_ "SAE_Document" BO_ 2364549886 "J1939-71";
BA_ "GenMsgSendType" BO_ 2566712318 0;
BA_ "GenMsgCycleTime" BO_ 2566712318 1000;
BA_ "SAE_Document" BO_ 2566712318 "J1939-71";
BA_ "GenMsgSendType" BO_ 2566712574 0;
BA_ "GenMsgCycleTime" BO_ 2566712574 1000;
BA_ "SAE_Document" BO_ 2566712574 "J1939-71";
BA_ "SAE_Document" BO_ 2164078590 "J1939-71";
BA_ "GenMsgSendType" BO_ 2566731006 0;
BA_ "GenMsgCycleTime" BO_ 2566731006 1000;
BA_ "SAE_Document" BO_ 2566731006 "J1939-71";
BA_ "GenMsgSendType" BO_ 2566731262 0;
BA_ "GenMsgCycleTime" BO_ 2566731262 1000;
BA_ "SAE_Document" BO_ 2566731262 "J1939-71";
BA_ "GenMsgSendType" BO_ 2566730750 0;
BA_ "GenMsgCycleTime" BO_ 2566730750 1000;
BA_ "SAE_Document" BO_ 2566730750 "J1939-71";
BA_ "GenMsgSendType" BO_ 2566731518 0;
BA_ "GenMsgCycleTime" BO_ 2566731518 1000;
BA_ "SAE_Document" BO_ 2566731518 "J1939-71";
BA_ "GenMsgSendType" BO_ 2566732030 0;
BA_ "GenMsgCycleTime" BO_ 2566732030 500;
BA_ "SAE_Document" BO_ 2566732030 "J1939-71";
BA_ "GenMsgSendType" BO_ 2566732286 0;
BA_ "GenMsgCycleTime" BO_ 2566732286 500;
BA_ "SAE_Document" BO_ 2566732286 "J1939-71";
BA_ "GenMsgSendType" BO_ 2164079358 0;
BA_ "GenMsgCycleTime" BO_ 2164079358 500;
BA_ "SAE_Document" BO_ 2164079358 "J1939-71";
BA_ "GenMsgSendType" BO_ 2364549118 0;
BA_ "GenMsgCycleTime" BO_ 2364549118 50;
BA_ "SAE_Document" BO_ 2364549118 "J1939-71";
BA_ "GenMsgSendType" BO_ 2566732798 0;
BA_ "GenMsgCycleTime" BO_ 2566732798 500;
BA_ "SAE_Document" BO_ 2566732798 "J1939-71";
BA_ "GenMsgSendType" BO_ 2364548862 0;
BA_ "GenMsgCycleTime" BO_ 2364548862 50;
BA_ "SAE_Document" BO_ 2364548862 "J1939-71";
BA_ "GenMsgSendType" BO_ 2364549374 0;
BA_ "GenMsgCycleTime" BO_ 2364549374 50;
BA_ "SAE_Document" BO_ 2364549374 "J1939-71";
BA_ "GenMsgSendType" BO_ 2566726142 0;
BA_ "GenMsgCycleTime" BO_ 2566726142 500;
BA_ "SAE_Document" BO_ 2566726142 "J1939-71";
BA_ "GenMsgSendType" BO_ 2566725630 0;
BA_ "GenMsgCycleTime" BO_ 2566725630 500;
BA_ "SAE_Document" BO_ 2566725630 "J1939-71";
BA_ "GenMsgSendType" BO_ 2566733310 0;
BA_ "GenMsgCycleTime" BO_ 2566733310 1000;
BA_ "SAE_Document" BO_ 2566733310 "J1939-71";
BA_ "GenMsgSendType" BO_ 2566733054 0;
BA_ "GenMsgCycleTime" BO_ 2566733054 1000;
BA_ "SAE_Document" BO_ 2566733054 "J1939-71";
BA_ "GenMsgSendType" BO_ 2499624702 0;
BA_ "GenMsgCycleTime" BO_ 2499624702 500;
BA_ "SAE_Document" BO_ 2499624702 "J1939-71";
BA_ "GenMsgSendType" BO_ 2566733822 0;
BA_ "GenMsgCycleTime" BO_ 2566733822 500;
BA_ "SAE_Document" BO_ 2566733822 "J1939-71";
BA_ "GenMsgSendType" BO_ 2566734078 0;
BA_ "GenMsgCycleTime" BO_ 2566734078 500;
BA_ "SAE_Document" BO_ 2566734078 "J1939-71";
BA_ "GenMsgSendType" BO_ 2364548350 0;
BA_ "GenMsgCycleTime" BO_ 2364548350 50;
BA_ "SAE_Document" BO_ 2364548350 "J1939-71";
BA_ "GenMsgSendType" BO_ 2566734334 0;
BA_ "GenMsgCycleTime" BO_ 2566734334 500;
BA_ "SAE_Document" BO_ 2566734334 "J1939-71";
BA_ "GenMsgSendType" BO_ 2364548094 0;
BA_ "GenMsgCycleTime" BO_ 2364548094 50;
BA_ "SAE_Document" BO_ 2364548094 "J1939-71";
BA_ "GenMsgSendType" BO_ 2364548606 0;
BA_ "GenMsgCycleTime" BO_ 2364548606 50;
BA_ "SAE_Document" BO_ 2364548606 "J1939-71";
BA_ "GenMsgSendType" BO_ 2566726398 0;
BA_ "GenMsgCycleTime" BO_ 2566726398 500;
BA_ "SAE_Document" BO_ 2566726398 "J1939-71";
BA_ "SAE_Document" BO_ 2566742270 "J1939_73";
BA_ "SAE_Document" BO_ 2566742526 "J1939_73";
BA_ "SAE_Document" BO_ 2566742782 "J1939_73";
BA_ "SAE_Document" BO_ 2566743038 "J1939_73";
BA_ "SAE_Document" BO_ 2566743294 "J1939_73";
BA_ "SAE_Document" BO_ 2560687870 "J1939_73";
BA_ "SAE_Document" BO_ 2292317950 "J1939_73";
BA_ "GenMsgSendType" BO_ 2566809342 0;
BA_ "GenMsgCycleTime" BO_ 2566809342 1000;
BA_ "SAE_Document" BO_ 2566809342 "J1939-71";
BA_ "SigType" SG_ 2365401854 Joystick7Button9PressedStatus 4;
BA_ "SPN" SG_ 2365401854 Joystick7Button9PressedStatus 4623;
BA_ "SAEDocument" SG_ 2365401854 Joystick7Button9PressedStatus "J1939-71";
BA_ "SigType" SG_ 2365401854 Joystick7Button10PressedStatus 4;
BA_ "SPN" SG_ 2365401854 Joystick7Button10PressedStatus 4622;
BA_ "SAEDocument" SG_ 2365401854 Joystick7Button10PressedStatus "J1939-71";
BA_ "SigType" SG_ 2365401854 Joystick7Button11PressedStatus 4;
BA_ "SPN" SG_ 2365401854 Joystick7Button11PressedStatus 4621;
BA_ "SAEDocument" SG_ 2365401854 Joystick7Button11PressedStatus "J1939-71";
BA_ "SigType" SG_ 2365401854 Joystick7Button12PressedStatus 4;
BA_ "SPN" SG_ 2365401854 Joystick7Button12PressedStatus 4620;
BA_ "SAEDocument" SG_ 2365401854 Joystick7Button12PressedStatus "J1939-71";
BA_ "SigType" SG_ 2365401854 Joystick7Button5PressedStatus 4;
BA_ "SPN" SG_ 2365401854 Joystick7Button5PressedStatus 4619;
BA_ "SAEDocument" SG_ 2365401854 Joystick7Button5PressedStatus "J1939-71";
BA_ "SigType" SG_ 2365401854 Joystick7Button6PressedStatus 4;
BA_ "SPN" SG_ 2365401854 Joystick7Button6PressedStatus 4618;
BA_ "SAEDocument" SG_ 2365401854 Joystick7Button6PressedStatus "J1939-71";
BA_ "SigType" SG_ 2365401854 Joystick7Button7PressedStatus 4;
BA_ "SPN" SG_ 2365401854 Joystick7Button7PressedStatus 4617;
BA_ "SAEDocument" SG_ 2365401854 Joystick7Button7PressedStatus "J1939-71";
BA_ "SigType" SG_ 2365401854 Joystick7Button8PressedStatus 4;
BA_ "SPN" SG_ 2365401854 Joystick7Button8PressedStatus 4616;
BA_ "SAEDocument" SG_ 2365401854 Joystick7Button8PressedStatus "J1939-71";
BA_ "SigType" SG_ 2365401854 Joystick7Button1PressedStatus 4;
BA_ "SPN" SG_ 2365401854 Joystick7Button1PressedStatus 4615;
BA_ "SAEDocument" SG_ 2365401854 Joystick7Button1PressedStatus "J1939-71";
BA_ "SigType" SG_ 2365401854 Joystick7Button2PressedStatus 4;
BA_ "SPN" SG_ 2365401854 Joystick7Button2PressedStatus 4614;
BA_ "SAEDocument" SG_ 2365401854 Joystick7Button2PressedStatus "J1939-71";
BA_ "SigType" SG_ 2365401854 Joystick7Button3PressedStatus 4;
BA_ "SPN" SG_ 2365401854 Joystick7Button3PressedStatus 4613;
BA_ "SAEDocument" SG_ 2365401854 Joystick7Button3PressedStatus "J1939-71";
BA_ "SigType" SG_ 2365401854 Joystick7Button4PressedStatus 4;
BA_ "SPN" SG_ 2365401854 Joystick7Button4PressedStatus 4612;
BA_ "SAEDocument" SG_ 2365401854 Joystick7Button4PressedStatus "J1939-71";
BA_ "SigType" SG_ 2365401854 Joystick7XAxisDetentPosStatus 4;
BA_ "SPN" SG_ 2365401854 Joystick7XAxisDetentPosStatus 4611;
BA_ "SAEDocument" SG_ 2365401854 Joystick7XAxisDetentPosStatus "J1939-71";
BA_ "SigType" SG_ 2365401854 Joystick7YAxisDetentPosStatus 4;
BA_ "SPN" SG_ 2365401854 Joystick7YAxisDetentPosStatus 4610;
BA_ "SAEDocument" SG_ 2365401854 Joystick7YAxisDetentPosStatus "J1939-71";
BA_ "SPN" SG_ 2365401854 Joystick7YAxisPos 4609;
BA_ "SAEDocument" SG_ 2365401854 Joystick7YAxisPos "J1939-71";
BA_ "SigType" SG_ 2365401854 Jystck7YAxsLvrFrwrdPstvPosStatus 4;
BA_ "SPN" SG_ 2365401854 Jystck7YAxsLvrFrwrdPstvPosStatus 4608;
BA_ "SAEDocument" SG_ 2365401854 Jystck7YAxsLvrFrwrdPstvPosStatus "J1939-71";
BA_ "SigType" SG_ 2365401854 Jystck7YAxsLvrBckNgtivePosStatus 4;
BA_ "SPN" SG_ 2365401854 Jystck7YAxsLvrBckNgtivePosStatus 4607;
BA_ "SAEDocument" SG_ 2365401854 Jystck7YAxsLvrBckNgtivePosStatus "J1939-71";
BA_ "SigType" SG_ 2365401854 Joystick7YAxisNeutralPosStatus 4;
BA_ "SPN" SG_ 2365401854 Joystick7YAxisNeutralPosStatus 4606;
BA_ "SAEDocument" SG_ 2365401854 Joystick7YAxisNeutralPosStatus "J1939-71";
BA_ "SPN" SG_ 2365401854 Joystick7XAxisPos 4605;
BA_ "SAEDocument" SG_ 2365401854 Joystick7XAxisPos "J1939-71";
BA_ "SigType" SG_ 2365401854 Jystck7XAxsLvrRghtPstvePosStatus 4;
BA_ "SPN" SG_ 2365401854 Jystck7XAxsLvrRghtPstvePosStatus 4604;
BA_ "SAEDocument" SG_ 2365401854 Jystck7XAxsLvrRghtPstvePosStatus "J1939-71";
BA_ "SigType" SG_ 2365401854 Jystck7XAxsLvrLftNgtivePosStatus 4;
BA_ "SPN" SG_ 2365401854 Jystck7XAxsLvrLftNgtivePosStatus 4603;
BA_ "SAEDocument" SG_ 2365401854 Jystck7XAxsLvrLftNgtivePosStatus "J1939-71";
BA_ "SigType" SG_ 2365401854 Joystick7XAxisNeutralPosStatus 4;
BA_ "SPN" SG_ 2365401854 Joystick7XAxisNeutralPosStatus 4602;
BA_ "SAEDocument" SG_ 2365401854 Joystick7XAxisNeutralPosStatus "J1939-71";
BA_ "SigType" SG_ 2365402366 Joystick6Button9PressedStatus 4;
BA_ "SPN" SG_ 2365402366 Joystick6Button9PressedStatus 4586;
BA_ "SAEDocument" SG_ 2365402366 Joystick6Button9PressedStatus "J1939-71";
BA_ "SigType" SG_ 2365402366 Joystick6Button10PressedStatus 4;
BA_ "SPN" SG_ 2365402366 Joystick6Button10PressedStatus 4585;
BA_ "SAEDocument" SG_ 2365402366 Joystick6Button10PressedStatus "J1939-71";
BA_ "SigType" SG_ 2365402366 Joystick6Button11PressedStatus 4;
BA_ "SPN" SG_ 2365402366 Joystick6Button11PressedStatus 4584;
BA_ "SAEDocument" SG_ 2365402366 Joystick6Button11PressedStatus "J1939-71";
BA_ "SigType" SG_ 2365402366 Joystick6Button12PressedStatus 4;
BA_ "SPN" SG_ 2365402366 Joystick6Button12PressedStatus 4583;
BA_ "SAEDocument" SG_ 2365402366 Joystick6Button12PressedStatus "J1939-71";
BA_ "SigType" SG_ 2365402366 Joystick6Button5PressedStatus 4;
BA_ "SPN" SG_ 2365402366 Joystick6Button5PressedStatus 4582;
BA_ "SAEDocument" SG_ 2365402366 Joystick6Button5PressedStatus "J1939-71";
BA_ "SigType" SG_ 2365402366 Joystick6Button6PressedStatus 4;
BA_ "SPN" SG_ 2365402366 Joystick6Button6PressedStatus 4581;
BA_ "SAEDocument" SG_ 2365402366 Joystick6Button6PressedStatus "J1939-71";
BA_ "SigType" SG_ 2365402366 Joystick6Button7PressedStatus 4;
BA_ "SPN" SG_ 2365402366 Joystick6Button7PressedStatus 4580;
BA_ "SAEDocument" SG_ 2365402366 Joystick6Button7PressedStatus "J1939-71";
BA_ "SigType" SG_ 2365402366 Joystick6Button8PressedStatus 4;
BA_ "SPN" SG_ 2365402366 Joystick6Button8PressedStatus 4579;
BA_ "SAEDocument" SG_ 2365402366 Joystick6Button8PressedStatus "J1939-71";
BA_ "SigType" SG_ 2365402366 Joystick6Button1PressedStatus 4;
BA_ "SPN" SG_ 2365402366 Joystick6Button1PressedStatus 4578;
BA_ "SAEDocument" SG_ 2365402366 Joystick6Button1PressedStatus "J1939-71";
BA_ "SigType" SG_ 2365402366 Joystick6Button2PressedStatus 4;
BA_ "SPN" SG_ 2365402366 Joystick6Button2PressedStatus 4577;
BA_ "SAEDocument" SG_ 2365402366 Joystick6Button2PressedStatus "J1939-71";
BA_ "SigType" SG_ 2365402366 Joystick6Button3PressedStatus 4;
BA_ "SPN" SG_ 2365402366 Joystick6Button3PressedStatus 4576;
BA_ "SAEDocument" SG_ 2365402366 Joystick6Button3PressedStatus "J1939-71";
BA_ "SigType" SG_ 2365402366 Joystick6Button4PressedStatus 4;
BA_ "SPN" SG_ 2365402366 Joystick6Button4PressedStatus 4575;
BA_ "SAEDocument" SG_ 2365402366 Joystick6Button4PressedStatus "J1939-71";
BA_ "SigType" SG_ 2365402366 Joystick6XAxisDetentPosStatus 4;
BA_ "SPN" SG_ 2365402366 Joystick6XAxisDetentPosStatus 4574;
BA_ "SAEDocument" SG_ 2365402366 Joystick6XAxisDetentPosStatus "J1939-71";
BA_ "SigType" SG_ 2365402366 Joystick6YAxisDetentPosStatus 4;
BA_ "SPN" SG_ 2365402366 Joystick6YAxisDetentPosStatus 4573;
BA_ "SAEDocument" SG_ 2365402366 Joystick6YAxisDetentPosStatus "J1939-71";
BA_ "SPN" SG_ 2365402366 Joystick6YAxisPos 4572;
BA_ "SAEDocument" SG_ 2365402366 Joystick6YAxisPos "J1939-71";
BA_ "SigType" SG_ 2365402366 Jystck6YAxsLvrFrwrdPstvPosStatus 4;
BA_ "SPN" SG_ 2365402366 Jystck6YAxsLvrFrwrdPstvPosStatus 4571;
BA_ "SAEDocument" SG_ 2365402366 Jystck6YAxsLvrFrwrdPstvPosStatus "J1939-71";
BA_ "SigType" SG_ 2365402366 Jystck6YAxsLvrBckNgtivePosStatus 4;
BA_ "SPN" SG_ 2365402366 Jystck6YAxsLvrBckNgtivePosStatus 4570;
BA_ "SAEDocument" SG_ 2365402366 Jystck6YAxsLvrBckNgtivePosStatus "J1939-71";
BA_ "SigType" SG_ 2365402366 Joystick6YAxisNeutralPosStatus 4;
BA_ "SPN" SG_ 2365402366 Joystick6YAxisNeutralPosStatus 4569;
BA_ "SAEDocument" SG_ 2365402366 Joystick6YAxisNeutralPosStatus "J1939-71";
BA_ "SPN" SG_ 2365402366 Joystick6XAxisPos 4568;
BA_ "SAEDocument" SG_ 2365402366 Joystick6XAxisPos "J1939-71";
BA_ "SigType" SG_ 2365402366 Jystck6XAxsLvrRghtPstvePosStatus 4;
BA_ "SPN" SG_ 2365402366 Jystck6XAxsLvrRghtPstvePosStatus 4567;
BA_ "SAEDocument" SG_ 2365402366 Jystck6XAxsLvrRghtPstvePosStatus "J1939-71";
BA_ "SigType" SG_ 2365402366 Jystck6XAxsLvrLftNgtivePosStatus 4;
BA_ "SPN" SG_ 2365402366 Jystck6XAxsLvrLftNgtivePosStatus 4566;
BA_ "SAEDocument" SG_ 2365402366 Jystck6XAxsLvrLftNgtivePosStatus "J1939-71";
BA_ "SigType" SG_ 2365402366 Joystick6XAxisNeutralPosStatus 4;
BA_ "SPN" SG_ 2365402366 Joystick6XAxisNeutralPosStatus 4565;
BA_ "SAEDocument" SG_ 2365402366 Joystick6XAxisNeutralPosStatus "J1939-71";
BA_ "SigType" SG_ 2365402878 Joystick5Button9PressedStatus 4;
BA_ "SPN" SG_ 2365402878 Joystick5Button9PressedStatus 4549;
BA_ "SAEDocument" SG_ 2365402878 Joystick5Button9PressedStatus "J1939-71";
BA_ "SigType" SG_ 2365402878 Joystick5Button10PressedStatus 4;
BA_ "SPN" SG_ 2365402878 Joystick5Button10PressedStatus 4548;
BA_ "SAEDocument" SG_ 2365402878 Joystick5Button10PressedStatus "J1939-71";
BA_ "SigType" SG_ 2365402878 Joystick5Button11PressedStatus 4;
BA_ "SPN" SG_ 2365402878 Joystick5Button11PressedStatus 4547;
BA_ "SAEDocument" SG_ 2365402878 Joystick5Button11PressedStatus "J1939-71";
BA_ "SigType" SG_ 2365402878 Joystick5Button12PressedStatus 4;
BA_ "SPN" SG_ 2365402878 Joystick5Button12PressedStatus 4546;
BA_ "SAEDocument" SG_ 2365402878 Joystick5Button12PressedStatus "J1939-71";
BA_ "SigType" SG_ 2365402878 Joystick5Button5PressedStatus 4;
BA_ "SPN" SG_ 2365402878 Joystick5Button5PressedStatus 4545;
BA_ "SAEDocument" SG_ 2365402878 Joystick5Button5PressedStatus "J1939-71";
BA_ "SigType" SG_ 2365402878 Joystick5Button6PressedStatus 4;
BA_ "SPN" SG_ 2365402878 Joystick5Button6PressedStatus 4544;
BA_ "SAEDocument" SG_ 2365402878 Joystick5Button6PressedStatus "J1939-71";
BA_ "SigType" SG_ 2365402878 Joystick5Button7PressedStatus 4;
BA_ "SPN" SG_ 2365402878 Joystick5Button7PressedStatus 4543;
BA_ "SAEDocument" SG_ 2365402878 Joystick5Button7PressedStatus "J1939-71";
BA_ "SigType" SG_ 2365402878 Joystick5Button8PressedStatus 4;
BA_ "SPN" SG_ 2365402878 Joystick5Button8PressedStatus 4542;
BA_ "SAEDocument" SG_ 2365402878 Joystick5Button8PressedStatus "J1939-71";
BA_ "SigType" SG_ 2365402878 Joystick5Button1PressedStatus 4;
BA_ "SPN" SG_ 2365402878 Joystick5Button1PressedStatus 4541;
BA_ "SAEDocument" SG_ 2365402878 Joystick5Button1PressedStatus "J1939-71";
BA_ "SigType" SG_ 2365402878 Joystick5Button2PressedStatus 4;
BA_ "SPN" SG_ 2365402878 Joystick5Button2PressedStatus 4540;
BA_ "SAEDocument" SG_ 2365402878 Joystick5Button2PressedStatus "J1939-71";
BA_ "SigType" SG_ 2365402878 Joystick5Button3PressedStatus 4;
BA_ "SPN" SG_ 2365402878 Joystick5Button3PressedStatus 4539;
BA_ "SAEDocument" SG_ 2365402878 Joystick5Button3PressedStatus "J1939-71";
BA_ "SigType" SG_ 2365402878 Joystick5Button4PressedStatus 4;
BA_ "SPN" SG_ 2365402878 Joystick5Button4PressedStatus 4538;
BA_ "SAEDocument" SG_ 2365402878 Joystick5Button4PressedStatus "J1939-71";
BA_ "SigType" SG_ 2365402878 Joystick5XAxisDetentPosStatus 4;
BA_ "SPN" SG_ 2365402878 Joystick5XAxisDetentPosStatus 4537;
BA_ "SAEDocument" SG_ 2365402878 Joystick5XAxisDetentPosStatus "J1939-71";
BA_ "SigType" SG_ 2365402878 Joystick5YAxisDetentPosStatus 4;
BA_ "SPN" SG_ 2365402878 Joystick5YAxisDetentPosStatus 4536;
BA_ "SAEDocument" SG_ 2365402878 Joystick5YAxisDetentPosStatus "J1939-71";
BA_ "SPN" SG_ 2365402878 Joystick5YAxisPos 4535;
BA_ "SAEDocument" SG_ 2365402878 Joystick5YAxisPos "J1939-71";
BA_ "SigType" SG_ 2365402878 Jystck5YAxsLvrFrwrdPstvPosStatus 4;
BA_ "SPN" SG_ 2365402878 Jystck5YAxsLvrFrwrdPstvPosStatus 4534;
BA_ "SAEDocument" SG_ 2365402878 Jystck5YAxsLvrFrwrdPstvPosStatus "J1939-71";
BA_ "SigType" SG_ 2365402878 Jystck5YAxsLvrBckNgtivePosStatus 4;
BA_ "SPN" SG_ 2365402878 Jystck5YAxsLvrBckNgtivePosStatus 4533;
BA_ "SAEDocument" SG_ 2365402878 Jystck5YAxsLvrBckNgtivePosStatus "J1939-71";
BA_ "SigType" SG_ 2365402878 Joystick5YAxisNeutralPosStatus 4;
BA_ "SPN" SG_ 2365402878 Joystick5YAxisNeutralPosStatus 4532;
BA_ "SAEDocument" SG_ 2365402878 Joystick5YAxisNeutralPosStatus "J1939-71";
BA_ "SPN" SG_ 2365402878 Joystick5XAxisPos 4531;
BA_ "SAEDocument" SG_ 2365402878 Joystick5XAxisPos "J1939-71";
BA_ "SigType" SG_ 2365402878 Jystck5XAxsLvrRghtPstvePosStatus 4;
BA_ "SPN" SG_ 2365402878 Jystck5XAxsLvrRghtPstvePosStatus 4530;
BA_ "SAEDocument" SG_ 2365402878 Jystck5XAxsLvrRghtPstvePosStatus "J1939-71";
BA_ "SigType" SG_ 2365402878 Jystck5XAxsLvrLftNgtivePosStatus 4;
BA_ "SPN" SG_ 2365402878 Jystck5XAxsLvrLftNgtivePosStatus 4529;
BA_ "SAEDocument" SG_ 2365402878 Jystck5XAxsLvrLftNgtivePosStatus "J1939-71";
BA_ "SigType" SG_ 2365402878 Joystick5XAxisNeutralPosStatus 4;
BA_ "SPN" SG_ 2365402878 Joystick5XAxisNeutralPosStatus 4528;
BA_ "SAEDocument" SG_ 2365402878 Joystick5XAxisNeutralPosStatus "J1939-71";
BA_ "SigType" SG_ 2365403390 Joystick4Button9PressedStatus 4;
BA_ "SPN" SG_ 2365403390 Joystick4Button9PressedStatus 4512;
BA_ "SAEDocument" SG_ 2365403390 Joystick4Button9PressedStatus "J1939-71";
BA_ "SigType" SG_ 2365403390 Joystick4Button10PressedStatus 4;
BA_ "SPN" SG_ 2365403390 Joystick4Button10PressedStatus 4511;
BA_ "SAEDocument" SG_ 2365403390 Joystick4Button10PressedStatus "J1939-71";
BA_ "SigType" SG_ 2365403390 Joystick4Button11PressedStatus 4;
BA_ "SPN" SG_ 2365403390 Joystick4Button11PressedStatus 4510;
BA_ "SAEDocument" SG_ 2365403390 Joystick4Button11PressedStatus "J1939-71";
BA_ "SigType" SG_ 2365403390 Joystick4Button12PressedStatus 4;
BA_ "SPN" SG_ 2365403390 Joystick4Button12PressedStatus 4509;
BA_ "SAEDocument" SG_ 2365403390 Joystick4Button12PressedStatus "J1939-71";
BA_ "SigType" SG_ 2365403390 Joystick4Button5PressedStatus 4;
BA_ "SPN" SG_ 2365403390 Joystick4Button5PressedStatus 4508;
BA_ "SAEDocument" SG_ 2365403390 Joystick4Button5PressedStatus "J1939-71";
BA_ "SigType" SG_ 2365403390 Joystick4Button6PressedStatus 4;
BA_ "SPN" SG_ 2365403390 Joystick4Button6PressedStatus 4507;
BA_ "SAEDocument" SG_ 2365403390 Joystick4Button6PressedStatus "J1939-71";
BA_ "SigType" SG_ 2365403390 Joystick4Button7PressedStatus 4;
BA_ "SPN" SG_ 2365403390 Joystick4Button7PressedStatus 4506;
BA_ "SAEDocument" SG_ 2365403390 Joystick4Button7PressedStatus "J1939-71";
BA_ "SigType" SG_ 2365403390 Joystick4Button8PressedStatus 4;
BA_ "SPN" SG_ 2365403390 Joystick4Button8PressedStatus 4505;
BA_ "SAEDocument" SG_ 2365403390 Joystick4Button8PressedStatus "J1939-71";
BA_ "SigType" SG_ 2365403390 Joystick4Button1PressedStatus 4;
BA_ "SPN" SG_ 2365403390 Joystick4Button1PressedStatus 4504;
BA_ "SAEDocument" SG_ 2365403390 Joystick4Button1PressedStatus "J1939-71";
BA_ "SigType" SG_ 2365403390 Joystick4Button2PressedStatus 4;
BA_ "SPN" SG_ 2365403390 Joystick4Button2PressedStatus 4503;
BA_ "SAEDocument" SG_ 2365403390 Joystick4Button2PressedStatus "J1939-71";
BA_ "SigType" SG_ 2365403390 Joystick4Button3PressedStatus 4;
BA_ "SPN" SG_ 2365403390 Joystick4Button3PressedStatus 4502;
BA_ "SAEDocument" SG_ 2365403390 Joystick4Button3PressedStatus "J1939-71";
BA_ "SigType" SG_ 2365403390 Joystick4Button4PressedStatus 4;
BA_ "SPN" SG_ 2365403390 Joystick4Button4PressedStatus 4501;
BA_ "SAEDocument" SG_ 2365403390 Joystick4Button4PressedStatus "J1939-71";
BA_ "SigType" SG_ 2365403390 Joystick4XAxisDetentPosStatus 4;
BA_ "SPN" SG_ 2365403390 Joystick4XAxisDetentPosStatus 4500;
BA_ "SAEDocument" SG_ 2365403390 Joystick4XAxisDetentPosStatus "J1939-71";
BA_ "SigType" SG_ 2365403390 Joystick4YAxisDetentPosStatus 4;
BA_ "SPN" SG_ 2365403390 Joystick4YAxisDetentPosStatus 4499;
BA_ "SAEDocument" SG_ 2365403390 Joystick4YAxisDetentPosStatus "J1939-71";
BA_ "SPN" SG_ 2365403390 Joystick4YAxisPos 4498;
BA_ "SAEDocument" SG_ 2365403390 Joystick4YAxisPos "J1939-71";
BA_ "SigType" SG_ 2365403390 Jystck4YAxsLvrFrwrdPstvPosStatus 4;
BA_ "SPN" SG_ 2365403390 Jystck4YAxsLvrFrwrdPstvPosStatus 4497;
BA_ "SAEDocument" SG_ 2365403390 Jystck4YAxsLvrFrwrdPstvPosStatus "J1939-71";
BA_ "SigType" SG_ 2365403390 Jystck4YAxsLvrBckNgtivePosStatus 4;
BA_ "SPN" SG_ 2365403390 Jystck4YAxsLvrBckNgtivePosStatus 4496;
BA_ "SAEDocument" SG_ 2365403390 Jystck4YAxsLvrBckNgtivePosStatus "J1939-71";
BA_ "SigType" SG_ 2365403390 Joystick4YAxisNeutralPosStatus 4;
BA_ "SPN" SG_ 2365403390 Joystick4YAxisNeutralPosStatus 4495;
BA_ "SAEDocument" SG_ 2365403390 Joystick4YAxisNeutralPosStatus "J1939-71";
BA_ "SPN" SG_ 2365403390 Joystick4XAxisPos 4494;
BA_ "SAEDocument" SG_ 2365403390 Joystick4XAxisPos "J1939-71";
BA_ "SigType" SG_ 2365403390 Jystck4XAxsLvrRghtPstvePosStatus 4;
BA_ "SPN" SG_ 2365403390 Jystck4XAxsLvrRghtPstvePosStatus 4493;
BA_ "SAEDocument" SG_ 2365403390 Jystck4XAxsLvrRghtPstvePosStatus "J1939-71";
BA_ "SigType" SG_ 2365403390 Jystck4XAxsLvrLftNgtivePosStatus 4;
BA_ "SPN" SG_ 2365403390 Jystck4XAxsLvrLftNgtivePosStatus 4492;
BA_ "SAEDocument" SG_ 2365403390 Jystck4XAxsLvrLftNgtivePosStatus "J1939-71";
BA_ "SigType" SG_ 2365403390 Joystick4XAxisNeutralPosStatus 4;
BA_ "SPN" SG_ 2365403390 Joystick4XAxisNeutralPosStatus 4491;
BA_ "SAEDocument" SG_ 2365403390 Joystick4XAxisNeutralPosStatus "J1939-71";
BA_ "SigType" SG_ 2365400318 Joystick10Button9PressedStatus 4;
BA_ "SPN" SG_ 2365400318 Joystick10Button9PressedStatus 4734;
BA_ "SAEDocument" SG_ 2365400318 Joystick10Button9PressedStatus "J1939-71";
BA_ "SigType" SG_ 2365400318 Joystick10Button10PressedStatus 4;
BA_ "SPN" SG_ 2365400318 Joystick10Button10PressedStatus 4733;
BA_ "SAEDocument" SG_ 2365400318 Joystick10Button10PressedStatus "J1939-71";
BA_ "SigType" SG_ 2365400318 Joystick10Button11PressedStatus 4;
BA_ "SPN" SG_ 2365400318 Joystick10Button11PressedStatus 4732;
BA_ "SAEDocument" SG_ 2365400318 Joystick10Button11PressedStatus "J1939-71";
BA_ "SigType" SG_ 2365400318 Joystick10Button12PressedStatus 4;
BA_ "SPN" SG_ 2365400318 Joystick10Button12PressedStatus 4731;
BA_ "SAEDocument" SG_ 2365400318 Joystick10Button12PressedStatus "J1939-71";
BA_ "SigType" SG_ 2365400318 Joystick10Button5PressedStatus 4;
BA_ "SPN" SG_ 2365400318 Joystick10Button5PressedStatus 4730;
BA_ "SAEDocument" SG_ 2365400318 Joystick10Button5PressedStatus "J1939-71";
BA_ "SigType" SG_ 2365400318 Joystick10Button6PressedStatus 4;
BA_ "SPN" SG_ 2365400318 Joystick10Button6PressedStatus 4729;
BA_ "SAEDocument" SG_ 2365400318 Joystick10Button6PressedStatus "J1939-71";
BA_ "SigType" SG_ 2365400318 Joystick10Button7PressedStatus 4;
BA_ "SPN" SG_ 2365400318 Joystick10Button7PressedStatus 4728;
BA_ "SAEDocument" SG_ 2365400318 Joystick10Button7PressedStatus "J1939-71";
BA_ "SigType" SG_ 2365400318 Joystick10Button8PressedStatus 4;
BA_ "SPN" SG_ 2365400318 Joystick10Button8PressedStatus 4727;
BA_ "SAEDocument" SG_ 2365400318 Joystick10Button8PressedStatus "J1939-71";
BA_ "SigType" SG_ 2365400318 Joystick10Button1PressedStatus 4;
BA_ "SPN" SG_ 2365400318 Joystick10Button1PressedStatus 4726;
BA_ "SAEDocument" SG_ 2365400318 Joystick10Button1PressedStatus "J1939-71";
BA_ "SigType" SG_ 2365400318 Joystick10Button2PressedStatus 4;
BA_ "SPN" SG_ 2365400318 Joystick10Button2PressedStatus 4725;
BA_ "SAEDocument" SG_ 2365400318 Joystick10Button2PressedStatus "J1939-71";
BA_ "SigType" SG_ 2365400318 Joystick10Button3PressedStatus 4;
BA_ "SPN" SG_ 2365400318 Joystick10Button3PressedStatus 4724;
BA_ "SAEDocument" SG_ 2365400318 Joystick10Button3PressedStatus "J1939-71";
BA_ "SigType" SG_ 2365400318 Joystick10Button4PressedStatus 4;
BA_ "SPN" SG_ 2365400318 Joystick10Button4PressedStatus 4723;
BA_ "SAEDocument" SG_ 2365400318 Joystick10Button4PressedStatus "J1939-71";
BA_ "SigType" SG_ 2365400318 Joystick10XAxisDetentPosStatus 4;
BA_ "SPN" SG_ 2365400318 Joystick10XAxisDetentPosStatus 4722;
BA_ "SAEDocument" SG_ 2365400318 Joystick10XAxisDetentPosStatus "J1939-71";
BA_ "SigType" SG_ 2365400318 Joystick10YAxisDetentPosStatus 4;
BA_ "SPN" SG_ 2365400318 Joystick10YAxisDetentPosStatus 4721;
BA_ "SAEDocument" SG_ 2365400318 Joystick10YAxisDetentPosStatus "J1939-71";
BA_ "SPN" SG_ 2365400318 Joystick10YAxisPos 4720;
BA_ "SAEDocument" SG_ 2365400318 Joystick10YAxisPos "J1939-71";
BA_ "SigType" SG_ 2365400318 Jystck10YAxsLvrFrwrdPstvPsStatus 4;
BA_ "SPN" SG_ 2365400318 Jystck10YAxsLvrFrwrdPstvPsStatus 4719;
BA_ "SAEDocument" SG_ 2365400318 Jystck10YAxsLvrFrwrdPstvPsStatus "J1939-71";
BA_ "SigType" SG_ 2365400318 Jystck10YAxsLvrBckNgtvePosStatus 4;
BA_ "SPN" SG_ 2365400318 Jystck10YAxsLvrBckNgtvePosStatus 4718;
BA_ "SAEDocument" SG_ 2365400318 Jystck10YAxsLvrBckNgtvePosStatus "J1939-71";
BA_ "SigType" SG_ 2365400318 Joystick10YAxisNeutralPosStatus 4;
BA_ "SPN" SG_ 2365400318 Joystick10YAxisNeutralPosStatus 4717;
BA_ "SAEDocument" SG_ 2365400318 Joystick10YAxisNeutralPosStatus "J1939-71";
BA_ "SPN" SG_ 2365400318 Joystick10XAxisPos 4716;
BA_ "SAEDocument" SG_ 2365400318 Joystick10XAxisPos "J1939-71";
BA_ "SigType" SG_ 2365400318 Jystck10XAxsLvrRghtPstvPosStatus 4;
BA_ "SPN" SG_ 2365400318 Jystck10XAxsLvrRghtPstvPosStatus 4715;
BA_ "SAEDocument" SG_ 2365400318 Jystck10XAxsLvrRghtPstvPosStatus "J1939-71";
BA_ "SigType" SG_ 2365400318 Jystck10XAxsLvrLftNgtvePosStatus 4;
BA_ "SPN" SG_ 2365400318 Jystck10XAxsLvrLftNgtvePosStatus 4714;
BA_ "SAEDocument" SG_ 2365400318 Jystck10XAxsLvrLftNgtvePosStatus "J1939-71";
BA_ "SigType" SG_ 2365400318 Joystick10XAxisNeutralPosStatus 4;
BA_ "SPN" SG_ 2365400318 Joystick10XAxisNeutralPosStatus 4713;
BA_ "SAEDocument" SG_ 2365400318 Joystick10XAxisNeutralPosStatus "J1939-71";
BA_ "SigType" SG_ 2499614718 PssngrArbgDctivationSwitchStatus 5;
BA_ "SPN" SG_ 2499614718 PssngrArbgDctivationSwitchStatus 4962;
BA_ "SAEDocument" SG_ 2499614718 PssngrArbgDctivationSwitchStatus "J1939-71";
BA_ "SigType" SG_ 2499614718 Beltlock10Status 5;
BA_ "SPN" SG_ 2499614718 Beltlock10Status 4961;
BA_ "SAEDocument" SG_ 2499614718 Beltlock10Status "J1939-71";
BA_ "SigType" SG_ 2499614718 Beltlock9Status 5;
BA_ "SPN" SG_ 2499614718 Beltlock9Status 4960;
BA_ "SAEDocument" SG_ 2499614718 Beltlock9Status "J1939-71";
BA_ "SigType" SG_ 2499614718 Beltlock8Status 5;
BA_ "SPN" SG_ 2499614718 Beltlock8Status 4959;
BA_ "SAEDocument" SG_ 2499614718 Beltlock8Status "J1939-71";
BA_ "SigType" SG_ 2499614718 Beltlock7Status 5;
BA_ "SPN" SG_ 2499614718 Beltlock7Status 4958;
BA_ "SAEDocument" SG_ 2499614718 Beltlock7Status "J1939-71";
BA_ "SigType" SG_ 2499614718 Beltlock6Status 5;
BA_ "SPN" SG_ 2499614718 Beltlock6Status 4957;
BA_ "SAEDocument" SG_ 2499614718 Beltlock6Status "J1939-71";
BA_ "SigType" SG_ 2499614718 Beltlock5Status 5;
BA_ "SPN" SG_ 2499614718 Beltlock5Status 4956;
BA_ "SAEDocument" SG_ 2499614718 Beltlock5Status "J1939-71";
BA_ "SigType" SG_ 2499614718 Beltlock4Status 5;
BA_ "SPN" SG_ 2499614718 Beltlock4Status 4955;
BA_ "SAEDocument" SG_ 2499614718 Beltlock4Status "J1939-71";
BA_ "SigType" SG_ 2499614718 Beltlock3Status 5;
BA_ "SPN" SG_ 2499614718 Beltlock3Status 4954;
BA_ "SAEDocument" SG_ 2499614718 Beltlock3Status "J1939-71";
BA_ "SigType" SG_ 2499614718 PassengerBeltlockStatus 5;
BA_ "SPN" SG_ 2499614718 PassengerBeltlockStatus 4953;
BA_ "SAEDocument" SG_ 2499614718 PassengerBeltlockStatus "J1939-71";
BA_ "SigType" SG_ 2499614718 DriverBeltlockStatus 5;
BA_ "SPN" SG_ 2499614718 DriverBeltlockStatus 4952;
BA_ "SAEDocument" SG_ 2499614718 DriverBeltlockStatus "J1939-71";
BA_ "SigType" SG_ 2566722814 BatteryCharger2OutputCurrent 1;
BA_ "SPN" SG_ 2566722814 BatteryCharger2OutputCurrent 4997;
BA_ "SAEDocument" SG_ 2566722814 BatteryCharger2OutputCurrent "J1939-71";
BA_ "SigType" SG_ 2566722814 BatteryCharger2OutputVoltage 1;
BA_ "SPN" SG_ 2566722814 BatteryCharger2OutputVoltage 4996;
BA_ "SAEDocument" SG_ 2566722814 BatteryCharger2OutputVoltage "J1939-71";
BA_ "SigType" SG_ 2566722814 BatteryCharger2PowerLineState 4;
BA_ "SPN" SG_ 2566722814 BatteryCharger2PowerLineState 4995;
BA_ "SAEDocument" SG_ 2566722814 BatteryCharger2PowerLineState "J1939-71";
BA_ "SPN" SG_ 2566722814 BatteryCharger2State 4994;
BA_ "SAEDocument" SG_ 2566722814 BatteryCharger2State "J1939-71";
BA_ "SigType" SG_ 2566723070 BatteryCharger1OutputCurrent 1;
BA_ "SPN" SG_ 2566723070 BatteryCharger1OutputCurrent 4993;
BA_ "SAEDocument" SG_ 2566723070 BatteryCharger1OutputCurrent "J1939-71";
BA_ "SigType" SG_ 2566723070 BatteryCharger1OutputVoltage 1;
BA_ "SPN" SG_ 2566723070 BatteryCharger1OutputVoltage 4992;
BA_ "SAEDocument" SG_ 2566723070 BatteryCharger1OutputVoltage "J1939-71";
BA_ "SigType" SG_ 2566723070 BatteryCharger1PowerLineState 4;
BA_ "SPN" SG_ 2566723070 BatteryCharger1PowerLineState 4991;
BA_ "SAEDocument" SG_ 2566723070 BatteryCharger1PowerLineState "J1939-71";
BA_ "SPN" SG_ 2566723070 BatteryCharger1State 4990;
BA_ "SAEDocument" SG_ 2566723070 BatteryCharger1State "J1939-71";
BA_ "SigType" SG_ 2566725118 Aftrtrtmnt2ThrWyCtlystDffGasTemp 1;
BA_ "SPN" SG_ 2566725118 Aftrtrtmnt2ThrWyCtlystDffGasTemp 4780;
BA_ "SAEDocument" SG_ 2566725118 Aftrtrtmnt2ThrWyCtlystDffGasTemp "J1939-71";
BA_ "SigType" SG_ 2566725118 Aftrtrtmnt1ThrWyCtlystDffGasTemp 1;
BA_ "SPN" SG_ 2566725118 Aftrtrtmnt1ThrWyCtlystDffGasTemp 4779;
BA_ "SAEDocument" SG_ 2566725118 Aftrtrtmnt1ThrWyCtlystDffGasTemp "J1939-71";
BA_ "SigType" SG_ 2566725374 Aftrtrtmnt2GsOxdtnCtlystDffGsTmp 1;
BA_ "SPN" SG_ 2566725374 Aftrtrtmnt2GsOxdtnCtlystDffGsTmp 4778;
BA_ "SAEDocument" SG_ 2566725374 Aftrtrtmnt2GsOxdtnCtlystDffGsTmp "J1939-71";
BA_ "SigType" SG_ 2566725374 Aftrtrtmnt1GsOxdtnCtlystDffGsTmp 1;
BA_ "SPN" SG_ 2566725374 Aftrtrtmnt1GsOxdtnCtlystDffGsTmp 4777;
BA_ "SAEDocument" SG_ 2566725374 Aftrtrtmnt1GsOxdtnCtlystDffGsTmp "J1939-71";
BA_ "SigType" SG_ 2566712830 Aftrtrtmnt2WrmUpDslOxdtnCtlystOt 1;
BA_ "SPN" SG_ 2566712830 Aftrtrtmnt2WrmUpDslOxdtnCtlystOt 5316;
BA_ "SAEDocument" SG_ 2566712830 Aftrtrtmnt2WrmUpDslOxdtnCtlystOt "J1939-71";
BA_ "SigType" SG_ 2566712830 Aftrtrtmnt2WrmUpDslOxdtnCtlystIn 1;
BA_ "SPN" SG_ 2566712830 Aftrtrtmnt2WrmUpDslOxdtnCtlystIn 5315;
BA_ "SAEDocument" SG_ 2566712830 Aftrtrtmnt2WrmUpDslOxdtnCtlystIn "J1939-71";
BA_ "SigType" SG_ 2566735358 Aftrtrtmnt2ThrWyCtlytcCnvrtrDffP 1;
BA_ "SPN" SG_ 2566735358 Aftrtrtmnt2ThrWyCtlytcCnvrtrDffP 4297;
BA_ "SAEDocument" SG_ 2566735358 Aftrtrtmnt2ThrWyCtlytcCnvrtrDffP "J1939-71";
BA_ "SigType" SG_ 2566735358 Aftrtrtmnt2ThrWyCtlytcCnvrtrOtlt 1;
BA_ "SPN" SG_ 2566735358 Aftrtrtmnt2ThrWyCtlytcCnvrtrOtlt 4296;
BA_ "SAEDocument" SG_ 2566735358 Aftrtrtmnt2ThrWyCtlytcCnvrtrOtlt "J1939-71";
BA_ "SigType" SG_ 2566735358 Aftrtrtmnt2ThrWyCtlytcCnvrtrIntk 1;
BA_ "SPN" SG_ 2566735358 Aftrtrtmnt2ThrWyCtlytcCnvrtrIntk 4295;
BA_ "SAEDocument" SG_ 2566735358 Aftrtrtmnt2ThrWyCtlytcCnvrtrIntk "J1939-71";
BA_ "SigType" SG_ 2365393662 Aftrtrtmnt2OtltGsNOxSnsrNH3Crrct 1;
BA_ "SPN" SG_ 2365393662 Aftrtrtmnt2OtltGsNOxSnsrNH3Crrct 5051;
BA_ "SAEDocument" SG_ 2365393662 Aftrtrtmnt2OtltGsNOxSnsrNH3Crrct "J1939-71";
BA_ "SigType" SG_ 2365393662 Aftrtrtmnt2OtltGsNOxSnsrNO2Crrct 1;
BA_ "SPN" SG_ 2365393662 Aftrtrtmnt2OtltGsNOxSnsrNO2Crrct 5050;
BA_ "SAEDocument" SG_ 2365393662 Aftrtrtmnt2OtltGsNOxSnsrNO2Crrct "J1939-71";
BA_ "SigType" SG_ 2365393662 Aftrtrtmnt2OtltGsNOxSnsrCrrctnOf 1;
BA_ "SPN" SG_ 2365393662 Aftrtrtmnt2OtltGsNOxSnsrCrrctnOf 5048;
BA_ "SAEDocument" SG_ 2365393662 Aftrtrtmnt2OtltGsNOxSnsrCrrctnOf "J1939-71";
BA_ "SigType" SG_ 2365393918 Aftrtrtmnt2OtltGsNOxSnsrNwPrtDvt 1;
BA_ "SPN" SG_ 2365393918 Aftrtrtmnt2OtltGsNOxSnsrNwPrtDvt 5046;
BA_ "SAEDocument" SG_ 2365393918 Aftrtrtmnt2OtltGsNOxSnsrNwPrtDvt "J1939-71";
BA_ "SigType" SG_ 2365393918 Aftrtrtmnt2OtltGsNOxSnsrHtrRatio 1;
BA_ "SPN" SG_ 2365393918 Aftrtrtmnt2OtltGsNOxSnsrHtrRatio 5045;
BA_ "SAEDocument" SG_ 2365393918 Aftrtrtmnt2OtltGsNOxSnsrHtrRatio "J1939-71";
BA_ "SigType" SG_ 2365394174 Aftrtrtmnt2IntkGsNOxSnsrNH3Crrct 1;
BA_ "SPN" SG_ 2365394174 Aftrtrtmnt2IntkGsNOxSnsrNH3Crrct 5044;
BA_ "SAEDocument" SG_ 2365394174 Aftrtrtmnt2IntkGsNOxSnsrNH3Crrct "J1939-71";
BA_ "SigType" SG_ 2365394174 Aftrtrtmnt2IntkGsNOxSnsrNO2Crrct 1;
BA_ "SPN" SG_ 2365394174 Aftrtrtmnt2IntkGsNOxSnsrNO2Crrct 5043;
BA_ "SAEDocument" SG_ 2365394174 Aftrtrtmnt2IntkGsNOxSnsrNO2Crrct "J1939-71";
BA_ "SigType" SG_ 2365394174 Aftrtrtmnt2IntkGsNOxSnsrCrrctnOf 1;
BA_ "SPN" SG_ 2365394174 Aftrtrtmnt2IntkGsNOxSnsrCrrctnOf 5041;
BA_ "SAEDocument" SG_ 2365394174 Aftrtrtmnt2IntkGsNOxSnsrCrrctnOf "J1939-71";
BA_ "SigType" SG_ 2365394430 Aftrtrtmnt2IntkGsNOxSnsrNwPrtDvt 1;
BA_ "SPN" SG_ 2365394430 Aftrtrtmnt2IntkGsNOxSnsrNwPrtDvt 5039;
BA_ "SAEDocument" SG_ 2365394430 Aftrtrtmnt2IntkGsNOxSnsrNwPrtDvt "J1939-71";
BA_ "SigType" SG_ 2365394430 Aftrtrtmnt2IntkGsNOxSnsrHtrRatio 1;
BA_ "SPN" SG_ 2365394430 Aftrtrtmnt2IntkGsNOxSnsrHtrRatio 5038;
BA_ "SAEDocument" SG_ 2365394430 Aftrtrtmnt2IntkGsNOxSnsrHtrRatio "J1939-71";
BA_ "SPN" SG_ 2566735102 Aftertreatment2FuelPress2Ctrl 5428;
BA_ "SAEDocument" SG_ 2566735102 Aftertreatment2FuelPress2Ctrl "J1939-71";
BA_ "SigType" SG_ 2566735102 Aftrtrtmnt2FlFlwDverterValveCtrl 5;
BA_ "SPN" SG_ 2566735102 Aftrtrtmnt2FlFlwDverterValveCtrl 5427;
BA_ "SAEDocument" SG_ 2566735102 Aftrtrtmnt2FlFlwDverterValveCtrl "J1939-71";
BA_ "SigType" SG_ 2566735102 Aftertreatment2FuelPumpRelayCtrl 5;
BA_ "SPN" SG_ 2566735102 Aftertreatment2FuelPumpRelayCtrl 5426;
BA_ "SAEDocument" SG_ 2566735102 Aftertreatment2FuelPumpRelayCtrl "J1939-71";
BA_ "SigType" SG_ 2566735102 Aftertreatment2FuelPress2 1;
BA_ "SPN" SG_ 2566735102 Aftertreatment2FuelPress2 4303;
BA_ "SAEDocument" SG_ 2566735102 Aftertreatment2FuelPress2 "J1939-71";
BA_ "SPN" SG_ 2157313790 Aftrtrtmnt2DslPrtcltFltrStStndrd 5498;
BA_ "SAEDocument" SG_ 2157313790 Aftrtrtmnt2DslPrtcltFltrStStndrd "J1939-71";
BA_ "SPN" SG_ 2157313790 Aftrtrtmnt2DslPrtcltFltrStMnClbO 5497;
BA_ "SAEDocument" SG_ 2157313790 Aftrtrtmnt2DslPrtcltFltrStMnClbO "J1939-71";
BA_ "SigType" SG_ 2566724350 Aftrtrtmnt1WrmUpDslOxdtnCtlystOt 1;
BA_ "SPN" SG_ 2566724350 Aftrtrtmnt1WrmUpDslOxdtnCtlystOt 4810;
BA_ "SAEDocument" SG_ 2566724350 Aftrtrtmnt1WrmUpDslOxdtnCtlystOt "J1939-71";
BA_ "SigType" SG_ 2566724350 Aftrtrtmnt1WrmUpDslOxdtnCtlystIn 1;
BA_ "SPN" SG_ 2566724350 Aftrtrtmnt1WrmUpDslOxdtnCtlystIn 4809;
BA_ "SAEDocument" SG_ 2566724350 Aftrtrtmnt1WrmUpDslOxdtnCtlystIn "J1939-71";
BA_ "SigType" SG_ 2566735614 Aftrtrtmnt1ThrWyCtlytcCnvrtrDffP 1;
BA_ "SPN" SG_ 2566735614 Aftrtrtmnt1ThrWyCtlytcCnvrtrDffP 4291;
BA_ "SAEDocument" SG_ 2566735614 Aftrtrtmnt1ThrWyCtlytcCnvrtrDffP "J1939-71";
BA_ "SigType" SG_ 2566735614 Aftrtrtmnt1ThrWyCtlytcCnvrtrOtlt 1;
BA_ "SPN" SG_ 2566735614 Aftrtrtmnt1ThrWyCtlytcCnvrtrOtlt 4290;
BA_ "SAEDocument" SG_ 2566735614 Aftrtrtmnt1ThrWyCtlytcCnvrtrOtlt "J1939-71";
BA_ "SigType" SG_ 2566735614 Aftrtrtmnt1ThrWyCtlytcCnvrtrIntk 1;
BA_ "SPN" SG_ 2566735614 Aftrtrtmnt1ThrWyCtlytcCnvrtrIntk 4289;
BA_ "SAEDocument" SG_ 2566735614 Aftrtrtmnt1ThrWyCtlytcCnvrtrIntk "J1939-71";
BA_ "SPN" SG_ 2566805246 Aftrtrtmnt1SCRCtlystRgntTnk1HtrP 4366;
BA_ "SAEDocument" SG_ 2566805246 Aftrtrtmnt1SCRCtlystRgntTnk1HtrP "J1939-71";
BA_ "SPN" SG_ 2566805246 AftrtrtmntSCROprtrIndcmntSverity 5246;
BA_ "SAEDocument" SG_ 2566805246 AftrtrtmntSCROprtrIndcmntSverity "J1939-71";
BA_ "SPN" SG_ 2566805246 Aftrtrtmnt1SCRCtlystRgntTnk1TmpP 4365;
BA_ "SAEDocument" SG_ 2566805246 Aftrtrtmnt1SCRCtlystRgntTnk1TmpP "J1939-71";
BA_ "SPN" SG_ 2566805246 Aftrtrtmnt1DEFTnkLwLvelIndicator 5245;
BA_ "SAEDocument" SG_ 2566805246 Aftrtrtmnt1DEFTnkLwLvelIndicator "J1939-71";
BA_ "SPN" SG_ 2566805246 Aftrtrtmnt1SCRCtlystTnkLvlPrlmnr 3532;
BA_ "SAEDocument" SG_ 2566805246 Aftrtrtmnt1SCRCtlystTnkLvlPrlmnr "J1939-71";
BA_ "SigType" SG_ 2566805246 Aftrtrtmnt1SCRCatalystTankLevel2 1;
BA_ "SPN" SG_ 2566805246 Aftrtrtmnt1SCRCatalystTankLevel2 3517;
BA_ "SAEDocument" SG_ 2566805246 Aftrtrtmnt1SCRCatalystTankLevel2 "J1939-71";
BA_ "SigType" SG_ 2566805246 Aftrtratment1SCRCatalystTankTemp 1;
BA_ "SPN" SG_ 2566805246 Aftrtratment1SCRCatalystTankTemp 3031;
BA_ "SAEDocument" SG_ 2566805246 Aftrtratment1SCRCatalystTankTemp "J1939-71";
BA_ "SigType" SG_ 2566805246 Aftrtrtment1SCRCatalystTankLevel 1;
BA_ "SPN" SG_ 2566805246 Aftrtrtment1SCRCatalystTankLevel 1761;
BA_ "SAEDocument" SG_ 2566805246 Aftrtrtment1SCRCatalystTankLevel "J1939-71";
BA_ "SigType" SG_ 2566805246 Aftrtrtmnt1SCRCtalystTankHeater 1;
BA_ "SPN" SG_ 2566805246 Aftrtrtmnt1SCRCtalystTankHeater 3363;
BA_ "SAEDocument" SG_ 2566805246 Aftrtrtmnt1SCRCtalystTankHeater "J1939-71";
BA_ "SigType" SG_ 2365394686 Aftrtrtmnt1OtltGsNOxSnsrNH3Crrct 1;
BA_ "SPN" SG_ 2365394686 Aftrtrtmnt1OtltGsNOxSnsrNH3Crrct 5037;
BA_ "SAEDocument" SG_ 2365394686 Aftrtrtmnt1OtltGsNOxSnsrNH3Crrct "J1939-71";
BA_ "SigType" SG_ 2365394686 Aftrtrtmnt1OtltGsNOxSnsrNO2Crrct 1;
BA_ "SPN" SG_ 2365394686 Aftrtrtmnt1OtltGsNOxSnsrNO2Crrct 5036;
BA_ "SAEDocument" SG_ 2365394686 Aftrtrtmnt1OtltGsNOxSnsrNO2Crrct "J1939-71";
BA_ "SigType" SG_ 2365394686 Aftrtrtmnt1OtltGsNOxSnsrCrrctnOf 1;
BA_ "SPN" SG_ 2365394686 Aftrtrtmnt1OtltGsNOxSnsrCrrctnOf 5034;
BA_ "SAEDocument" SG_ 2365394686 Aftrtrtmnt1OtltGsNOxSnsrCrrctnOf "J1939-71";
BA_ "SPN" SG_ 2365394942 NOxSensorATI1OpHoursCount 5721;
BA_ "SigType" SG_ 2365394942 Aft1OtltGsNOxSnsrNwPrtDvt_Offset 1;
BA_ "SPN" SG_ 2365394942 Aft1OtltGsNOxSnsrNwPrtDvt_Offset 5033;
BA_ "SAEDocument" SG_ 2365394942 Aft1OtltGsNOxSnsrNwPrtDvt_Offset "J1939-71";
BA_ "SPN" SG_ 2365394942 AftT1OtltGsNOxSnsrNwPrtDvt_Gain 5032;
BA_ "SigType" SG_ 2365394942 Aftrtrtmnt1OtltGsNOxSnsrHtrRatio 1;
BA_ "SPN" SG_ 2365394942 Aftrtrtmnt1OtltGsNOxSnsrHtrRatio 5031;
BA_ "SAEDocument" SG_ 2365394942 Aftrtrtmnt1OtltGsNOxSnsrHtrRatio "J1939-71";
BA_ "SigType" SG_ 2365395198 Aftrtrtmnt1IntkGsNOxSnsrNH3Crrct 1;
BA_ "SPN" SG_ 2365395198 Aftrtrtmnt1IntkGsNOxSnsrNH3Crrct 5030;
BA_ "SAEDocument" SG_ 2365395198 Aftrtrtmnt1IntkGsNOxSnsrNH3Crrct "J1939-71";
BA_ "SigType" SG_ 2365395198 Aftrtrtmnt1IntkGsNOxSnsrNO2Crrct 1;
BA_ "SPN" SG_ 2365395198 Aftrtrtmnt1IntkGsNOxSnsrNO2Crrct 5029;
BA_ "SAEDocument" SG_ 2365395198 Aftrtrtmnt1IntkGsNOxSnsrNO2Crrct "J1939-71";
BA_ "SigType" SG_ 2365395198 Aftrtrtmnt1IntkGsNOxSnsrCrrctnOf 1;
BA_ "SPN" SG_ 2365395198 Aftrtrtmnt1IntkGsNOxSnsrCrrctnOf 5027;
BA_ "SAEDocument" SG_ 2365395198 Aftrtrtmnt1IntkGsNOxSnsrCrrctnOf "J1939-71";
BA_ "SPN" SG_ 2365395454 NOxSensorATI1OpHoursCount 5721;
BA_ "SigType" SG_ 2365395454 IntkGsNOxSnsrNwPrtDvtOffset 1;
BA_ "SPN" SG_ 2365395454 IntkGsNOxSnsrNwPrtDvtOffset 5025;
BA_ "SAEDocument" SG_ 2365395454 IntkGsNOxSnsrNwPrtDvtOffset "J1939-71";
BA_ "SigType" SG_ 2365395454 Aftrtrtmnt1IntkGsNOxSnsrHtrRatio 1;
BA_ "SPN" SG_ 2365395454 Aftrtrtmnt1IntkGsNOxSnsrHtrRatio 5024;
BA_ "SAEDocument" SG_ 2365395454 Aftrtrtmnt1IntkGsNOxSnsrHtrRatio "J1939-71";
BA_ "SPN" SG_ 2157248254 Aftrtrtmnt1DslPrtcltFltrStStndrd 5496;
BA_ "SAEDocument" SG_ 2157248254 Aftrtrtmnt1DslPrtcltFltrStStndrd "J1939-71";
BA_ "SPN" SG_ 2157248254 Aftrtrtmnt1DslPrtcltFltrStMnClbO 5495;
BA_ "SAEDocument" SG_ 2157248254 Aftrtrtmnt1DslPrtcltFltrStMnClbO "J1939-71";
BA_ "SigType" SG_ 2566711806 ArmrestSwitchMatrix2Switch2 5;
BA_ "SPN" SG_ 2566711806 ArmrestSwitchMatrix2Switch2 5494;
BA_ "SAEDocument" SG_ 2566711806 ArmrestSwitchMatrix2Switch2 "J1939-71";
BA_ "SigType" SG_ 2566711806 ArmrestSwitchMatrix2Switch1 5;
BA_ "SPN" SG_ 2566711806 ArmrestSwitchMatrix2Switch1 5493;
BA_ "SAEDocument" SG_ 2566711806 ArmrestSwitchMatrix2Switch1 "J1939-71";
BA_ "SigType" SG_ 2566711806 ArmrestSwitchMatrixSwitch2 5;
BA_ "SPN" SG_ 2566711806 ArmrestSwitchMatrixSwitch2 5492;
BA_ "SAEDocument" SG_ 2566711806 ArmrestSwitchMatrixSwitch2 "J1939-71";
BA_ "SigType" SG_ 2566711806 ArmrestSwitchMatrixSwitch1 5;
BA_ "SPN" SG_ 2566711806 ArmrestSwitchMatrixSwitch1 1503;
BA_ "SAEDocument" SG_ 2566711806 ArmrestSwitchMatrixSwitch1 "J1939-71";
BA_ "SigType" SG_ 2364549886 AngularRateMeasurementLatency 1;
BA_ "SPN" SG_ 2364549886 AngularRateMeasurementLatency 4989;
BA_ "SAEDocument" SG_ 2364549886 AngularRateMeasurementLatency "J1939-71";
BA_ "SigType" SG_ 2364549886 YawRateExRangeFigureOfMerit 5;
BA_ "SPN" SG_ 2364549886 YawRateExRangeFigureOfMerit 4988;
BA_ "SAEDocument" SG_ 2364549886 YawRateExRangeFigureOfMerit "J1939-71";
BA_ "SigType" SG_ 2364549886 RollRateExRangeFigureOfMerit 5;
BA_ "SPN" SG_ 2364549886 RollRateExRangeFigureOfMerit 4987;
BA_ "SAEDocument" SG_ 2364549886 RollRateExRangeFigureOfMerit "J1939-71";
BA_ "SigType" SG_ 2364549886 PitchRateExRangeFigureOfMerit 5;
BA_ "SPN" SG_ 2364549886 PitchRateExRangeFigureOfMerit 4986;
BA_ "SAEDocument" SG_ 2364549886 PitchRateExRangeFigureOfMerit "J1939-71";
BA_ "SigType" SG_ 2364549886 YawRateExRange 1;
BA_ "SPN" SG_ 2364549886 YawRateExRange 4985;
BA_ "SAEDocument" SG_ 2364549886 YawRateExRange "J1939-71";
BA_ "SigType" SG_ 2364549886 RollRateExRange 1;
BA_ "SPN" SG_ 2364549886 RollRateExRange 4984;
BA_ "SAEDocument" SG_ 2364549886 RollRateExRange "J1939-71";
BA_ "SigType" SG_ 2364549886 PitchRateExRange 1;
BA_ "SPN" SG_ 2364549886 PitchRateExRange 4983;
BA_ "SAEDocument" SG_ 2364549886 PitchRateExRange "J1939-71";
BA_ "SigType" SG_ 2566712318 Aftrtrtmnt2NOxAdsrbrDSOxRgnrtnSt 5;
BA_ "SPN" SG_ 2566712318 Aftrtrtmnt2NOxAdsrbrDSOxRgnrtnSt 5462;
BA_ "SAEDocument" SG_ 2566712318 Aftrtrtmnt2NOxAdsrbrDSOxRgnrtnSt "J1939-71";
BA_ "SigType" SG_ 2566712318 Aftrtrtmnt2NOxAdsrbrDNOxRgnrtnSt 5;
BA_ "SPN" SG_ 2566712318 Aftrtrtmnt2NOxAdsrbrDNOxRgnrtnSt 5460;
BA_ "SAEDocument" SG_ 2566712318 Aftrtrtmnt2NOxAdsrbrDNOxRgnrtnSt "J1939-71";
BA_ "SigType" SG_ 2566712574 Aftrtrtmnt1NOxAdsrbrDSOxRgnrtnSt 5;
BA_ "SPN" SG_ 2566712574 Aftrtrtmnt1NOxAdsrbrDSOxRgnrtnSt 5461;
BA_ "SAEDocument" SG_ 2566712574 Aftrtrtmnt1NOxAdsrbrDSOxRgnrtnSt "J1939-71";
BA_ "SigType" SG_ 2566712574 Aftrtrtmnt1NOxAdsrbrDNOxRgnrtnSt 5;
BA_ "SPN" SG_ 2566712574 Aftrtrtmnt1NOxAdsrbrDNOxRgnrtnSt 5459;
BA_ "SAEDocument" SG_ 2566712574 Aftrtrtmnt1NOxAdsrbrDNOxRgnrtnSt "J1939-71";
BA_ "SigType" SG_ 2164078590 Aftrtrtmnt2SCRCtlystCnvrsnEffcnc 1;
BA_ "SPN" SG_ 2164078590 Aftrtrtmnt2SCRCtlystCnvrsnEffcnc 4419;
BA_ "SAEDocument" SG_ 2164078590 Aftrtrtmnt2SCRCtlystCnvrsnEffcnc "J1939-71";
BA_ "SPN" SG_ 2164078590 Aftrtrtmnt2SCRCmmnddCtlystRgntCn 4418;
BA_ "SAEDocument" SG_ 2164078590 Aftrtrtmnt2SCRCmmnddCtlystRgntCn "J1939-71";
BA_ "SigType" SG_ 2164078590 Aftrtrtmnt2SCRAvrgCtlystRgntCnsm 1;
BA_ "SPN" SG_ 2164078590 Aftrtrtmnt2SCRAvrgCtlystRgntCnsm 4417;
BA_ "SAEDocument" SG_ 2164078590 Aftrtrtmnt2SCRAvrgCtlystRgntCnsm "J1939-71";
BA_ "SPN" SG_ 2566731006 Aftrtrtmnt2SCRCtlystRgntTnk2HtrP 4439;
BA_ "SAEDocument" SG_ 2566731006 Aftrtrtmnt2SCRCtlystRgntTnk2HtrP "J1939-71";
BA_ "SPN" SG_ 2566731006 Aftrtrtmnt2SCRCtlystRgntTnk2Hter 4438;
BA_ "SAEDocument" SG_ 2566731006 Aftrtrtmnt2SCRCtlystRgntTnk2Hter "J1939-71";
BA_ "SPN" SG_ 2566731006 Aftrtrtmnt2SCRRgntTnk2TmpPrlmnry 4437;
BA_ "SAEDocument" SG_ 2566731006 Aftrtrtmnt2SCRRgntTnk2TmpPrlmnry "J1939-71";
BA_ "SPN" SG_ 2566731006 Aftrtrtmnt2SCRCtlystRgntTnk2LvlP 4436;
BA_ "SAEDocument" SG_ 2566731006 Aftrtrtmnt2SCRCtlystRgntTnk2LvlP "J1939-71";
BA_ "SPN" SG_ 2566731006 Aftrtrtmnt2SCRCtlystRgntTnk2Lvl2 4435;
BA_ "SAEDocument" SG_ 2566731006 Aftrtrtmnt2SCRCtlystRgntTnk2Lvl2 "J1939-71";
BA_ "SigType" SG_ 2566731006 Aftrtrtmnt2SCRCtlystRgntTnk2Temp 1;
BA_ "SPN" SG_ 2566731006 Aftrtrtmnt2SCRCtlystRgntTnk2Temp 4434;
BA_ "SAEDocument" SG_ 2566731006 Aftrtrtmnt2SCRCtlystRgntTnk2Temp "J1939-71";
BA_ "SigType" SG_ 2566731006 Aftrtrtmnt2SCRCtlystRgntTnk2Lvel 1;
BA_ "SPN" SG_ 2566731006 Aftrtrtmnt2SCRCtlystRgntTnk2Lvel 4433;
BA_ "SAEDocument" SG_ 2566731006 Aftrtrtmnt2SCRCtlystRgntTnk2Lvel "J1939-71";
BA_ "SPN" SG_ 2566731262 Aftrtrtmnt2SCRCtlystRgntTnk1HtrP 4432;
BA_ "SAEDocument" SG_ 2566731262 Aftrtrtmnt2SCRCtlystRgntTnk1HtrP "J1939-71";
BA_ "SigType" SG_ 2566731262 Aftrtrtmnt2SCRCtalystTankHeater 1;
BA_ "SPN" SG_ 2566731262 Aftrtrtmnt2SCRCtalystTankHeater 4431;
BA_ "SAEDocument" SG_ 2566731262 Aftrtrtmnt2SCRCtalystTankHeater "J1939-71";
BA_ "SPN" SG_ 2566731262 Aftrtrtmnt2SCRCtlystRgntTnk1TmpP 4430;
BA_ "SAEDocument" SG_ 2566731262 Aftrtrtmnt2SCRCtlystRgntTnk1TmpP "J1939-71";
BA_ "SPN" SG_ 2566731262 Aftrtrtmnt2SCRCtlystTnkLvlPrlmnr 4429;
BA_ "SAEDocument" SG_ 2566731262 Aftrtrtmnt2SCRCtlystTnkLvlPrlmnr "J1939-71";
BA_ "SigType" SG_ 2566731262 Aftrtrtmnt2SCRCatalystTankLevel2 1;
BA_ "SPN" SG_ 2566731262 Aftrtrtmnt2SCRCatalystTankLevel2 4428;
BA_ "SAEDocument" SG_ 2566731262 Aftrtrtmnt2SCRCatalystTankLevel2 "J1939-71";
BA_ "SigType" SG_ 2566731262 Aftrtratment2SCRCatalystTankTemp 1;
BA_ "SPN" SG_ 2566731262 Aftrtratment2SCRCatalystTankTemp 4427;
BA_ "SAEDocument" SG_ 2566731262 Aftrtratment2SCRCatalystTankTemp "J1939-71";
BA_ "SigType" SG_ 2566731262 Aftrtrtment2SCRCatalystTankLevel 1;
BA_ "SPN" SG_ 2566731262 Aftrtrtment2SCRCatalystTankLevel 4426;
BA_ "SAEDocument" SG_ 2566731262 Aftrtrtment2SCRCatalystTankLevel "J1939-71";
BA_ "SPN" SG_ 2566730750 Aftrtrtmnt2SCRCtlystRgntTnkDrnVl 5439;
BA_ "SAEDocument" SG_ 2566730750 Aftrtrtmnt2SCRCtlystRgntTnkDrnVl "J1939-71";
BA_ "SigType" SG_ 2566730750 Aftrtrtmnt2SCRCtlystRgntPmpState 5;
BA_ "SPN" SG_ 2566730750 Aftrtrtmnt2SCRCtlystRgntPmpState 5438;
BA_ "SAEDocument" SG_ 2566730750 Aftrtrtmnt2SCRCtlystRgntPmpState "J1939-71";
BA_ "SPN" SG_ 2566730750 Aftrtrtmnt2SCRCtlystRgntTnkFllVl 5437;
BA_ "SAEDocument" SG_ 2566730750 Aftrtrtmnt2SCRCtlystRgntTnkFllVl "J1939-71";
BA_ "SPN" SG_ 2566730750 Aftrtrtmnt2SCRCtlystRgntRtrnVlve 4442;
BA_ "SAEDocument" SG_ 2566730750 Aftrtrtmnt2SCRCtlystRgntRtrnVlve "J1939-71";
BA_ "SPN" SG_ 2566730750 Aftrtrtmnt2SCRCtlystRgntPmpDrvPr 4441;
BA_ "SAEDocument" SG_ 2566730750 Aftrtrtmnt2SCRCtlystRgntPmpDrvPr "J1939-71";
BA_ "SigType" SG_ 2566730750 Aftrtrtmnt2SCRCtlystRgntPmpMtrSp 1;
BA_ "SPN" SG_ 2566730750 Aftrtrtmnt2SCRCtlystRgntPmpMtrSp 4440;
BA_ "SAEDocument" SG_ 2566730750 Aftrtrtmnt2SCRCtlystRgntPmpMtrSp "J1939-71";
BA_ "SPN" SG_ 2566731518 Aftrtrtmnt2SCRCtalystReagentType 4425;
BA_ "SAEDocument" SG_ 2566731518 Aftrtrtmnt2SCRCtalystReagentType "J1939-71";
BA_ "SPN" SG_ 2566731518 Aftrtrtmnt2SCRCtlystRgntPrprtsPr 4424;
BA_ "SAEDocument" SG_ 2566731518 Aftrtrtmnt2SCRCtlystRgntPrprtsPr "J1939-71";
BA_ "SPN" SG_ 2566731518 Aftrtrtmnt2SCRCtlystRgntTmp2Prlm 4423;
BA_ "SAEDocument" SG_ 2566731518 Aftrtrtmnt2SCRCtlystRgntTmp2Prlm "J1939-71";
BA_ "SigType" SG_ 2566731518 Aftrtrtmnt2SCRCtlystRgntCndctvty 1;
BA_ "SPN" SG_ 2566731518 Aftrtrtmnt2SCRCtlystRgntCndctvty 4422;
BA_ "SAEDocument" SG_ 2566731518 Aftrtrtmnt2SCRCtlystRgntCndctvty "J1939-71";
BA_ "SigType" SG_ 2566731518 Aftrtrtmnt2SCRCtlystRgntCncntrtn 1;
BA_ "SPN" SG_ 2566731518 Aftrtrtmnt2SCRCtlystRgntCncntrtn 4421;
BA_ "SAEDocument" SG_ 2566731518 Aftrtrtmnt2SCRCtlystRgntCncntrtn "J1939-71";
BA_ "SigType" SG_ 2566731518 Aftrtrtmnt2SCRCtlystReagentTemp2 1;
BA_ "SPN" SG_ 2566731518 Aftrtrtmnt2SCRCtlystReagentTemp2 4420;
BA_ "SAEDocument" SG_ 2566731518 Aftrtrtmnt2SCRCtlystReagentTemp2 "J1939-71";
BA_ "SPN" SG_ 2566732030 Aftrtrtmnt2SCRCtlystOtltGsTmpPrl 4416;
BA_ "SAEDocument" SG_ 2566732030 Aftrtrtmnt2SCRCtlystOtltGsTmpPrl "J1939-71";
BA_ "SigType" SG_ 2566732030 Aftrtrtmnt2SCRCtlystOtletGasTemp 1;
BA_ "SPN" SG_ 2566732030 Aftrtrtmnt2SCRCtlystOtletGasTemp 4415;
BA_ "SAEDocument" SG_ 2566732030 Aftrtrtmnt2SCRCtlystOtletGasTemp "J1939-71";
BA_ "SPN" SG_ 2566732030 Aftrtrtmnt2SCRCtlystIntkGsTmpPrl 4414;
BA_ "SAEDocument" SG_ 2566732030 Aftrtrtmnt2SCRCtlystIntkGsTmpPrl "J1939-71";
BA_ "SigType" SG_ 2566732030 Aftrtrtmnt2SCRCtlystIntkeGasTemp 1;
BA_ "SPN" SG_ 2566732030 Aftrtrtmnt2SCRCtlystIntkeGasTemp 4413;
BA_ "SAEDocument" SG_ 2566732030 Aftrtrtmnt2SCRCtlystIntkeGasTemp "J1939-71";
BA_ "SigType" SG_ 2566732286 SCRCtlystExhstGsDffPr_PerlimFMI 1;
BA_ "SPN" SG_ 2566732286 SCRCtlystExhstGsDffPr_PerlimFMI 4411;
BA_ "SAEDocument" SG_ 2566732286 SCRCtlystExhstGsDffPr_PerlimFMI "J1939-71";
BA_ "SPN" SG_ 2164079358 Aftrtrtmnt2SCRCtlystTnk2HaterCmd 5415;
BA_ "SAEDocument" SG_ 2164079358 Aftrtrtmnt2SCRCtlystTnk2HaterCmd "J1939-71";
BA_ "SPN" SG_ 2164079358 Aftrtrtmnt2SCRCtlystTnkHeaterCmd 5138;
BA_ "SAEDocument" SG_ 2164079358 Aftrtrtmnt2SCRCtlystTnkHeaterCmd "J1939-71";
BA_ "SigType" SG_ 2164079358 Aftrtrtmnt2SCRCtlystRgntLnHater4 5;
BA_ "SPN" SG_ 2164079358 Aftrtrtmnt2SCRCtlystRgntLnHater4 4410;
BA_ "SAEDocument" SG_ 2164079358 Aftrtrtmnt2SCRCtlystRgntLnHater4 "J1939-71";
BA_ "SigType" SG_ 2164079358 Aftrtrtmnt2SCRCtlystRgntLnHater3 5;
BA_ "SPN" SG_ 2164079358 Aftrtrtmnt2SCRCtlystRgntLnHater3 4409;
BA_ "SAEDocument" SG_ 2164079358 Aftrtrtmnt2SCRCtlystRgntLnHater3 "J1939-71";
BA_ "SigType" SG_ 2164079358 Aftrtrtmnt2SCRCtlystRgntLnHater2 5;
BA_ "SPN" SG_ 2164079358 Aftrtrtmnt2SCRCtlystRgntLnHater2 4408;
BA_ "SAEDocument" SG_ 2164079358 Aftrtrtmnt2SCRCtlystRgntLnHater2 "J1939-71";
BA_ "SigType" SG_ 2164079358 Aftrtrtmnt2SCRCtlystRgntLnHater1 5;
BA_ "SPN" SG_ 2164079358 Aftrtrtmnt2SCRCtlystRgntLnHater1 4407;
BA_ "SAEDocument" SG_ 2164079358 Aftrtrtmnt2SCRCtlystRgntLnHater1 "J1939-71";
BA_ "SPN" SG_ 2164079358 Aftrtrtmnt2SCRDoserHeatingModeRq 4406;
BA_ "SAEDocument" SG_ 2164079358 Aftrtrtmnt2SCRDoserHeatingModeRq "J1939-71";
BA_ "SigType" SG_ 2164079358 Aftrtrtmnt2SCRDsrFltSppressionRq 5;
BA_ "SPN" SG_ 2164079358 Aftrtrtmnt2SCRDsrFltSppressionRq 4405;
BA_ "SAEDocument" SG_ 2164079358 Aftrtrtmnt2SCRDsrFltSppressionRq "J1939-71";
BA_ "SigType" SG_ 2364549118 Aftrtrtmnt2SCRRqstdRgntQnttyFrIn 1;
BA_ "SPN" SG_ 2364549118 Aftrtrtmnt2SCRRqstdRgntQnttyFrIn 4403;
BA_ "SAEDocument" SG_ 2364549118 Aftrtrtmnt2SCRRqstdRgntQnttyFrIn "J1939-71";
BA_ "SPN" SG_ 2364549118 Aftrtrtmnt2SCRSystmRquestedState 4402;
BA_ "SAEDocument" SG_ 2364549118 Aftrtrtmnt2SCRSystmRquestedState "J1939-71";
BA_ "SigType" SG_ 2364549118 Aftrtrtmnt2SCRRqstdDsngRgntQntty 1;
BA_ "SPN" SG_ 2364549118 Aftrtrtmnt2SCRRqstdDsngRgntQntty 4401;
BA_ "SAEDocument" SG_ 2364549118 Aftrtrtmnt2SCRRqstdDsngRgntQntty "J1939-71";
BA_ "SPN" SG_ 2566732798 Aftrtrtmnt2SCRCtlystRgntLnHtr4Pr 4400;
BA_ "SAEDocument" SG_ 2566732798 Aftrtrtmnt2SCRCtlystRgntLnHtr4Pr "J1939-71";
BA_ "SigType" SG_ 2566732798 Aftrtrtmnt2SCRCtlystRgntLnHtr4St 5;
BA_ "SPN" SG_ 2566732798 Aftrtrtmnt2SCRCtlystRgntLnHtr4St 4399;
BA_ "SAEDocument" SG_ 2566732798 Aftrtrtmnt2SCRCtlystRgntLnHtr4St "J1939-71";
BA_ "SPN" SG_ 2566732798 Aftrtrtmnt2SCRCtlystRgntLnHtr3Pr 4398;
BA_ "SAEDocument" SG_ 2566732798 Aftrtrtmnt2SCRCtlystRgntLnHtr3Pr "J1939-71";
BA_ "SigType" SG_ 2566732798 Aftrtrtmnt2SCRCtlystRgntLnHtr3St 5;
BA_ "SPN" SG_ 2566732798 Aftrtrtmnt2SCRCtlystRgntLnHtr3St 4397;
BA_ "SAEDocument" SG_ 2566732798 Aftrtrtmnt2SCRCtlystRgntLnHtr3St "J1939-71";
BA_ "SPN" SG_ 2566732798 Aftrtrtmnt2SCRCtlystRgntLnHtr2Pr 4396;
BA_ "SAEDocument" SG_ 2566732798 Aftrtrtmnt2SCRCtlystRgntLnHtr2Pr "J1939-71";
BA_ "SigType" SG_ 2566732798 Aftrtrtmnt2SCRCtlystRgntLnHtr2St 5;
BA_ "SPN" SG_ 2566732798 Aftrtrtmnt2SCRCtlystRgntLnHtr2St 4395;
BA_ "SAEDocument" SG_ 2566732798 Aftrtrtmnt2SCRCtlystRgntLnHtr2St "J1939-71";
BA_ "SPN" SG_ 2566732798 Aftrtrtmnt2SCRCtlystRgntLnHtr1Pr 4394;
BA_ "SAEDocument" SG_ 2566732798 Aftrtrtmnt2SCRCtlystRgntLnHtr1Pr "J1939-71";
BA_ "SigType" SG_ 2566732798 Aftrtrtmnt2SCRCtlystRgntLnHtr1St 5;
BA_ "SPN" SG_ 2566732798 Aftrtrtmnt2SCRCtlystRgntLnHtr1St 4393;
BA_ "SAEDocument" SG_ 2566732798 Aftrtrtmnt2SCRCtlystRgntLnHtr1St "J1939-71";
BA_ "SPN" SG_ 2566732798 Aftrtrtmnt2SCRFeedbackCtrlStatus 4392;
BA_ "SAEDocument" SG_ 2566732798 Aftrtrtmnt2SCRFeedbackCtrlStatus "J1939-71";
BA_ "SPN" SG_ 2566732798 Aftrtrtmnt2SCRDsngVlvExhstTmpRdc 4391;
BA_ "SAEDocument" SG_ 2566732798 Aftrtrtmnt2SCRDsngVlvExhstTmpRdc "J1939-71";
BA_ "SigType" SG_ 2566732798 Aftrtrtment2SCRDosingReagentTemp 1;
BA_ "SPN" SG_ 2566732798 Aftrtrtment2SCRDosingReagentTemp 4390;
BA_ "SAEDocument" SG_ 2566732798 Aftrtrtment2SCRDosingReagentTemp "J1939-71";
BA_ "SPN" SG_ 2566732798 Aftrtrtmnt2SCRDsngAirAssistValve 4389;
BA_ "SAEDocument" SG_ 2566732798 Aftrtrtmnt2SCRDsngAirAssistValve "J1939-71";
BA_ "SigType" SG_ 2566732798 Aftrtrtmnt2SCRDsngArAssstAbsPrss 1;
BA_ "SPN" SG_ 2566732798 Aftrtrtmnt2SCRDsngArAssstAbsPrss 4388;
BA_ "SAEDocument" SG_ 2566732798 Aftrtrtmnt2SCRDsngArAssstAbsPrss "J1939-71";
BA_ "SigType" SG_ 2364548862 Aftrtrtmnt2SCRDsngRagentAbsPress 1;
BA_ "SPN" SG_ 2364548862 Aftrtrtmnt2SCRDsngRagentAbsPress 4387;
BA_ "SAEDocument" SG_ 2364548862 Aftrtrtmnt2SCRDsngRagentAbsPress "J1939-71";
BA_ "SigType" SG_ 2364548862 Aftrtrtmnt2SCRActlRgntQnttyOfInt 1;
BA_ "SPN" SG_ 2364548862 Aftrtrtmnt2SCRActlRgntQnttyOfInt 4386;
BA_ "SAEDocument" SG_ 2364548862 Aftrtrtmnt2SCRActlRgntQnttyOfInt "J1939-71";
BA_ "SPN" SG_ 2364548862 Aftertreatment2SCRSystemState 4385;
BA_ "SAEDocument" SG_ 2364548862 Aftertreatment2SCRSystemState "J1939-71";
BA_ "SigType" SG_ 2364548862 Aftrtrtmnt2SCRActlDsngRgntQntity 1;
BA_ "SPN" SG_ 2364548862 Aftrtrtmnt2SCRActlDsngRgntQntity 4384;
BA_ "SAEDocument" SG_ 2364548862 Aftrtrtmnt2SCRActlDsngRgntQntity "J1939-71";
BA_ "SigType" SG_ 2364549374 Aftrtrtmnt2OtltNH3GsSnsrHterCtrl 5;
BA_ "SPN" SG_ 2364549374 Aftrtrtmnt2OtltNH3GsSnsrHterCtrl 4449;
BA_ "SAEDocument" SG_ 2364549374 Aftrtrtmnt2OtltNH3GsSnsrHterCtrl "J1939-71";
BA_ "SPN" SG_ 2364549374 Aftrtrtmnt2OtltNH3GsSnsrHtrPrlmn 4448;
BA_ "SAEDocument" SG_ 2364549374 Aftrtrtmnt2OtltNH3GsSnsrHtrPrlmn "J1939-71";
BA_ "SigType" SG_ 2364549374 Aftrtrtmnt2OtltNH3GsSensorAtTemp 5;
BA_ "SPN" SG_ 2364549374 Aftrtrtmnt2OtltNH3GsSensorAtTemp 4447;
BA_ "SAEDocument" SG_ 2364549374 Aftrtrtmnt2OtltNH3GsSensorAtTemp "J1939-71";
BA_ "SigType" SG_ 2364549374 Aftrtrtmnt2OtltNH3GsSnsrPwrInRng 5;
BA_ "SPN" SG_ 2364549374 Aftrtrtmnt2OtltNH3GsSnsrPwrInRng 4446;
BA_ "SAEDocument" SG_ 2364549374 Aftrtrtmnt2OtltNH3GsSnsrPwrInRng "J1939-71";
BA_ "SigType" SG_ 2364549374 Aftrtrtmnt2OtletNH3ReadingStable 5;
BA_ "SPN" SG_ 2364549374 Aftrtrtmnt2OtletNH3ReadingStable 4445;
BA_ "SAEDocument" SG_ 2364549374 Aftrtrtmnt2OtletNH3ReadingStable "J1939-71";
BA_ "SPN" SG_ 2364549374 Aftrtrtmnt2OtltNH3SnsrPrlmnryFMI 4444;
BA_ "SAEDocument" SG_ 2364549374 Aftrtrtmnt2OtltNH3SnsrPrlmnryFMI "J1939-71";
BA_ "SigType" SG_ 2364549374 Aftertreatment2OutletNH3 1;
BA_ "SPN" SG_ 2364549374 Aftertreatment2OutletNH3 4443;
BA_ "SAEDocument" SG_ 2364549374 Aftertreatment2OutletNH3 "J1939-71";
BA_ "SPN" SG_ 2566726142 GsOxdtnCtlystDffPrssP_PerlimFMI 4764;
BA_ "SAEDocument" SG_ 2566726142 GsOxdtnCtlystDffPrssP_PerlimFMI "J1939-71";
BA_ "SigType" SG_ 2566726142 GsOxdtnCtlystOtltGsTm_PerlimFMI 1;
BA_ "SPN" SG_ 2566726142 GsOxdtnCtlystOtltGsTm_PerlimFMI 4760;
BA_ "SAEDocument" SG_ 2566726142 GsOxdtnCtlystOtltGsTm_PerlimFMI "J1939-71";
BA_ "SigType" SG_ 2566726142 GsOxdtnCtlystIntkGsTm_PerlimFMI 1;
BA_ "SPN" SG_ 2566726142 GsOxdtnCtlystIntkGsTm_PerlimFMI 4759;
BA_ "SAEDocument" SG_ 2566726142 GsOxdtnCtlystIntkGsTm_PerlimFMI "J1939-71";
BA_ "SigType" SG_ 2566726142 Aftrtrtmnt2GsOxdtnCtlystDffPress 1;
BA_ "SPN" SG_ 2566726142 Aftrtrtmnt2GsOxdtnCtlystDffPress 4761;
BA_ "SAEDocument" SG_ 2566726142 Aftrtrtmnt2GsOxdtnCtlystDffPress "J1939-71";
BA_ "SigType" SG_ 2566725630 DslOxdtnCtlystOtltGsT_PerlimFMI 1;
BA_ "SPN" SG_ 2566725630 DslOxdtnCtlystOtltGsT_PerlimFMI 4772;
BA_ "SAEDocument" SG_ 2566725630 DslOxdtnCtlystOtltGsT_PerlimFMI "J1939-71";
BA_ "SigType" SG_ 2566725630 DslOxdtnCtlystIntkGsT_PerlimFMI 1;
BA_ "SPN" SG_ 2566725630 DslOxdtnCtlystIntkGsT_PerlimFMI 4771;
BA_ "SAEDocument" SG_ 2566725630 DslOxdtnCtlystIntkGsT_PerlimFMI "J1939-71";
BA_ "SPN" SG_ 2566725630 Aftrtrtmnt2DslOxdtnCtlystDffPrss 4776;
BA_ "SAEDocument" SG_ 2566725630 Aftrtrtmnt2DslOxdtnCtlystDffPrss "J1939-71";
BA_ "SPN" SG_ 2566733310 Aftrtrtmnt1SCRCtlystRgntTnk2HtrP 4373;
BA_ "SAEDocument" SG_ 2566733310 Aftrtrtmnt1SCRCtlystRgntTnk2HtrP "J1939-71";
BA_ "SigType" SG_ 2566733310 Aftrtrtmnt1SCRCtlystRgntTnk2Hter 1;
BA_ "SPN" SG_ 2566733310 Aftrtrtmnt1SCRCtlystRgntTnk2Hter 4372;
BA_ "SAEDocument" SG_ 2566733310 Aftrtrtmnt1SCRCtlystRgntTnk2Hter "J1939-71";
BA_ "SPN" SG_ 2566733310 Aftrtrtmnt1SCRRgntTnk2TmpPrlmnry 4371;
BA_ "SAEDocument" SG_ 2566733310 Aftrtrtmnt1SCRRgntTnk2TmpPrlmnry "J1939-71";
BA_ "SPN" SG_ 2566733310 Aftrtrtmnt1SCRCtlystRgntTnk2LvlP 4370;
BA_ "SAEDocument" SG_ 2566733310 Aftrtrtmnt1SCRCtlystRgntTnk2LvlP "J1939-71";
BA_ "SPN" SG_ 2566733310 Aftrtrtmnt1SCRCtlystRgntTnk2Lvl2 4369;
BA_ "SAEDocument" SG_ 2566733310 Aftrtrtmnt1SCRCtlystRgntTnk2Lvl2 "J1939-71";
BA_ "SigType" SG_ 2566733310 Aftrtrtmnt1SCRCtlystRgntTnk2Temp 1;
BA_ "SPN" SG_ 2566733310 Aftrtrtmnt1SCRCtlystRgntTnk2Temp 4368;
BA_ "SAEDocument" SG_ 2566733310 Aftrtrtmnt1SCRCtlystRgntTnk2Temp "J1939-71";
BA_ "SigType" SG_ 2566733310 Aftrtrtmnt1SCRCtlystRgntTnk2Lvel 1;
BA_ "SPN" SG_ 2566733310 Aftrtrtmnt1SCRCtlystRgntTnk2Lvel 4367;
BA_ "SAEDocument" SG_ 2566733310 Aftrtrtmnt1SCRCtlystRgntTnk2Lvel "J1939-71";
BA_ "SPN" SG_ 2566733054 Aftrtrtmnt1SCRCtlystRgntTnkDrnVl 5436;
BA_ "SAEDocument" SG_ 2566733054 Aftrtrtmnt1SCRCtlystRgntTnkDrnVl "J1939-71";
BA_ "SigType" SG_ 2566733054 Aftrtrtmnt1SCRCtlystRgntPmpState 5;
BA_ "SPN" SG_ 2566733054 Aftrtrtmnt1SCRCtlystRgntPmpState 5435;
BA_ "SAEDocument" SG_ 2566733054 Aftrtrtmnt1SCRCtlystRgntPmpState "J1939-71";
BA_ "SPN" SG_ 2566733054 Aftrtrtmnt1SCRCtlystRgntTnkFllVl 5434;
BA_ "SAEDocument" SG_ 2566733054 Aftrtrtmnt1SCRCtlystRgntTnkFllVl "J1939-71";
BA_ "SPN" SG_ 2566733054 Aftrtrtmnt1SCRCtlystRgntRtrnVlve 4376;
BA_ "SAEDocument" SG_ 2566733054 Aftrtrtmnt1SCRCtlystRgntRtrnVlve "J1939-71";
BA_ "SPN" SG_ 2566733054 Aftrtrtmnt1SCRCtlystRgntPmpDrvPr 4375;
BA_ "SAEDocument" SG_ 2566733054 Aftrtrtmnt1SCRCtlystRgntPmpDrvPr "J1939-71";
BA_ "SigType" SG_ 2566733054 Aftrtrtmnt1SCRCtlystRgntPmpMtrSp 1;
BA_ "SPN" SG_ 2566733054 Aftrtrtmnt1SCRCtlystRgntPmpMtrSp 4374;
BA_ "SAEDocument" SG_ 2566733054 Aftrtrtmnt1SCRCtlystRgntPmpMtrSp "J1939-71";
BA_ "SPN" SG_ 2499624702 Aftrtrtmnt1SCRCtlystOtltGsTmpPrl 4362;
BA_ "SAEDocument" SG_ 2499624702 Aftrtrtmnt1SCRCtlystOtltGsTmpPrl "J1939-71";
BA_ "SigType" SG_ 2499624702 Aftrtrtmnt1SCRCtlystOtletGasTemp 1;
BA_ "SPN" SG_ 2499624702 Aftrtrtmnt1SCRCtlystOtletGasTemp 4363;
BA_ "SAEDocument" SG_ 2499624702 Aftrtrtmnt1SCRCtlystOtletGasTemp "J1939-71";
BA_ "SPN" SG_ 2499624702 Aftrtrtmnt1SCRCtlystIntkGsTmpPrl 4361;
BA_ "SAEDocument" SG_ 2499624702 Aftrtrtmnt1SCRCtlystIntkGsTmpPrl "J1939-71";
BA_ "SigType" SG_ 2499624702 Aftrtrtmnt1SCRCtlystIntkeGasTemp 1;
BA_ "SPN" SG_ 2499624702 Aftrtrtmnt1SCRCtlystIntkeGasTemp 4360;
BA_ "SAEDocument" SG_ 2499624702 Aftrtrtmnt1SCRCtlystIntkeGasTemp "J1939-71";
BA_ "SigType" SG_ 2566733822 SCRCtlystExhstGsDffPr_PrelimFMI 1;
BA_ "SPN" SG_ 2566733822 SCRCtlystExhstGsDffPr_PrelimFMI 4358;
BA_ "SAEDocument" SG_ 2566733822 SCRCtlystExhstGsDffPr_PrelimFMI "J1939-71";
BA_ "SPN" SG_ 2566734078 Aftrtrtmnt1SCRCtlystTnk2HaterCmd 5414;
BA_ "SAEDocument" SG_ 2566734078 Aftrtrtmnt1SCRCtlystTnk2HaterCmd "J1939-71";
BA_ "SPN" SG_ 2566734078 Aftrtrtmnt1SCRCtlystTnkHeaterCmd 5137;
BA_ "SAEDocument" SG_ 2566734078 Aftrtrtmnt1SCRCtlystTnkHeaterCmd "J1939-71";
BA_ "SigType" SG_ 2566734078 Aftrtrtmnt1SCRCtlystRgntLnHater4 5;
BA_ "SPN" SG_ 2566734078 Aftrtrtmnt1SCRCtlystRgntLnHater4 4357;
BA_ "SAEDocument" SG_ 2566734078 Aftrtrtmnt1SCRCtlystRgntLnHater4 "J1939-71";
BA_ "SigType" SG_ 2566734078 Aftrtrtmnt1SCRCtlystRgntLnHater3 5;
BA_ "SPN" SG_ 2566734078 Aftrtrtmnt1SCRCtlystRgntLnHater3 4356;
BA_ "SAEDocument" SG_ 2566734078 Aftrtrtmnt1SCRCtlystRgntLnHater3 "J1939-71";
BA_ "SigType" SG_ 2566734078 Aftrtrtmnt1SCRCtlystRgntLnHater2 5;
BA_ "SPN" SG_ 2566734078 Aftrtrtmnt1SCRCtlystRgntLnHater2 4355;
BA_ "SAEDocument" SG_ 2566734078 Aftrtrtmnt1SCRCtlystRgntLnHater2 "J1939-71";
BA_ "SigType" SG_ 2566734078 Aftrtrtmnt1SCRCtlystRgntLnHater1 5;
BA_ "SPN" SG_ 2566734078 Aftrtrtmnt1SCRCtlystRgntLnHater1 4354;
BA_ "SAEDocument" SG_ 2566734078 Aftrtrtmnt1SCRCtlystRgntLnHater1 "J1939-71";
BA_ "SPN" SG_ 2566734078 Aftrtrtmnt1SCRDoserHeatingModeRq 4353;
BA_ "SAEDocument" SG_ 2566734078 Aftrtrtmnt1SCRDoserHeatingModeRq "J1939-71";
BA_ "SigType" SG_ 2566734078 Aftrtrtmnt1SCRDsrFltSppressionRq 5;
BA_ "SPN" SG_ 2566734078 Aftrtrtmnt1SCRDsrFltSppressionRq 4352;
BA_ "SAEDocument" SG_ 2566734078 Aftrtrtmnt1SCRDsrFltSppressionRq "J1939-71";
BA_ "SigType" SG_ 2364548350 Aftrtrtmnt1SCRRqstdRgntQnttyFrIn 1;
BA_ "SPN" SG_ 2364548350 Aftrtrtmnt1SCRRqstdRgntQnttyFrIn 4350;
BA_ "SAEDocument" SG_ 2364548350 Aftrtrtmnt1SCRRqstdRgntQnttyFrIn "J1939-71";
BA_ "SPN" SG_ 2364548350 Aftrtrtmnt1SCRSystmRquestedState 4349;
BA_ "SAEDocument" SG_ 2364548350 Aftrtrtmnt1SCRSystmRquestedState "J1939-71";
BA_ "SigType" SG_ 2364548350 Aftrtrtmnt1SCRRqstdDsngRgntQntty 1;
BA_ "SPN" SG_ 2364548350 Aftrtrtmnt1SCRRqstdDsngRgntQntty 4348;
BA_ "SAEDocument" SG_ 2364548350 Aftrtrtmnt1SCRRqstdDsngRgntQntty "J1939-71";
BA_ "SPN" SG_ 2566734334 Aftrtrtmnt1SCRCtlystRgntLnHtr4Pr 4347;
BA_ "SAEDocument" SG_ 2566734334 Aftrtrtmnt1SCRCtlystRgntLnHtr4Pr "J1939-71";
BA_ "SigType" SG_ 2566734334 Aftrtrtmnt1SCRCtlystRgntLnHtr4St 5;
BA_ "SPN" SG_ 2566734334 Aftrtrtmnt1SCRCtlystRgntLnHtr4St 4346;
BA_ "SAEDocument" SG_ 2566734334 Aftrtrtmnt1SCRCtlystRgntLnHtr4St "J1939-71";
BA_ "SPN" SG_ 2566734334 Aftrtrtmnt1SCRCtlystRgntLnHtr3Pr 4345;
BA_ "SAEDocument" SG_ 2566734334 Aftrtrtmnt1SCRCtlystRgntLnHtr3Pr "J1939-71";
BA_ "SigType" SG_ 2566734334 Aftrtrtmnt1SCRCtlystRgntLnHtr3St 5;
BA_ "SPN" SG_ 2566734334 Aftrtrtmnt1SCRCtlystRgntLnHtr3St 4344;
BA_ "SAEDocument" SG_ 2566734334 Aftrtrtmnt1SCRCtlystRgntLnHtr3St "J1939-71";
BA_ "SPN" SG_ 2566734334 Aftrtrtmnt1SCRCtlystRgntLnHtr2Pr 4343;
BA_ "SAEDocument" SG_ 2566734334 Aftrtrtmnt1SCRCtlystRgntLnHtr2Pr "J1939-71";
BA_ "SigType" SG_ 2566734334 Aftrtrtmnt1SCRCtlystRgntLnHtr2St 5;
BA_ "SPN" SG_ 2566734334 Aftrtrtmnt1SCRCtlystRgntLnHtr2St 4342;
BA_ "SAEDocument" SG_ 2566734334 Aftrtrtmnt1SCRCtlystRgntLnHtr2St "J1939-71";
BA_ "SPN" SG_ 2566734334 Aftrtrtmnt1SCRCtlystRgntLnHtr1Pr 4341;
BA_ "SAEDocument" SG_ 2566734334 Aftrtrtmnt1SCRCtlystRgntLnHtr1Pr "J1939-71";
BA_ "SigType" SG_ 2566734334 Aftrtrtmnt1SCRCtlystRgntLnHtr1St 5;
BA_ "SPN" SG_ 2566734334 Aftrtrtmnt1SCRCtlystRgntLnHtr1St 4340;
BA_ "SAEDocument" SG_ 2566734334 Aftrtrtmnt1SCRCtlystRgntLnHtr1St "J1939-71";
BA_ "SPN" SG_ 2566734334 Aftrtrtmnt1SCRFeedbackCtrlStatus 4339;
BA_ "SAEDocument" SG_ 2566734334 Aftrtrtmnt1SCRFeedbackCtrlStatus "J1939-71";
BA_ "SPN" SG_ 2566734334 Aftrtrtmnt1SCRDsngVlvExhstTmpRdc 4338;
BA_ "SAEDocument" SG_ 2566734334 Aftrtrtmnt1SCRDsngVlvExhstTmpRdc "J1939-71";
BA_ "SigType" SG_ 2566734334 Aftrtrtment1SCRDosingReagentTemp 1;
BA_ "SPN" SG_ 2566734334 Aftrtrtment1SCRDosingReagentTemp 4337;
BA_ "SAEDocument" SG_ 2566734334 Aftrtrtment1SCRDosingReagentTemp "J1939-71";
BA_ "SPN" SG_ 2566734334 Aftrtrtmnt1SCRDsngAirAssistValve 4336;
BA_ "SAEDocument" SG_ 2566734334 Aftrtrtmnt1SCRDsngAirAssistValve "J1939-71";
BA_ "SigType" SG_ 2566734334 Aftrtrtmnt1SCRDsngArAssstAbsPrss 1;
BA_ "SPN" SG_ 2566734334 Aftrtrtmnt1SCRDsngArAssstAbsPrss 4335;
BA_ "SAEDocument" SG_ 2566734334 Aftrtrtmnt1SCRDsngArAssstAbsPrss "J1939-71";
BA_ "SigType" SG_ 2364548094 Aftrtrtmnt1SCRDsngRagentAbsPress 1;
BA_ "SPN" SG_ 2364548094 Aftrtrtmnt1SCRDsngRagentAbsPress 4334;
BA_ "SAEDocument" SG_ 2364548094 Aftrtrtmnt1SCRDsngRagentAbsPress "J1939-71";
BA_ "SigType" SG_ 2364548094 Aftrtrtmnt1SCRActlRgntQnttyOfInt 1;
BA_ "SPN" SG_ 2364548094 Aftrtrtmnt1SCRActlRgntQnttyOfInt 4333;
BA_ "SAEDocument" SG_ 2364548094 Aftrtrtmnt1SCRActlRgntQnttyOfInt "J1939-71";
BA_ "SPN" SG_ 2364548094 Aftertreatment1SCRSystemState 4332;
BA_ "SAEDocument" SG_ 2364548094 Aftertreatment1SCRSystemState "J1939-71";
BA_ "SigType" SG_ 2364548094 Aftrtrtmnt1SCRActlDsngRgntQntity 1;
BA_ "SPN" SG_ 2364548094 Aftrtrtmnt1SCRActlDsngRgntQntity 4331;
BA_ "SAEDocument" SG_ 2364548094 Aftrtrtmnt1SCRActlDsngRgntQntity "J1939-71";
BA_ "SigType" SG_ 2364548606 Aftrtrtmnt1OtltNH3GsSnsrHterCtrl 5;
BA_ "SPN" SG_ 2364548606 Aftrtrtmnt1OtltNH3GsSnsrHterCtrl 4383;
BA_ "SAEDocument" SG_ 2364548606 Aftrtrtmnt1OtltNH3GsSnsrHterCtrl "J1939-71";
BA_ "SPN" SG_ 2364548606 Aftrtrtmnt1OtltNH3GsSnsrHtrPrlmn 4382;
BA_ "SAEDocument" SG_ 2364548606 Aftrtrtmnt1OtltNH3GsSnsrHtrPrlmn "J1939-71";
BA_ "SigType" SG_ 2364548606 Aftrtrtmnt1OtltNH3GsSensorAtTemp 5;
BA_ "SPN" SG_ 2364548606 Aftrtrtmnt1OtltNH3GsSensorAtTemp 4381;
BA_ "SAEDocument" SG_ 2364548606 Aftrtrtmnt1OtltNH3GsSensorAtTemp "J1939-71";
BA_ "SigType" SG_ 2364548606 Aftrtrtmnt1OtltNH3GsSnsrPwrInRng 5;
BA_ "SPN" SG_ 2364548606 Aftrtrtmnt1OtltNH3GsSnsrPwrInRng 4380;
BA_ "SAEDocument" SG_ 2364548606 Aftrtrtmnt1OtltNH3GsSnsrPwrInRng "J1939-71";
BA_ "SigType" SG_ 2364548606 Aftrtrtmnt1OtletNH3ReadingStable 5;
BA_ "SPN" SG_ 2364548606 Aftrtrtmnt1OtletNH3ReadingStable 4379;
BA_ "SAEDocument" SG_ 2364548606 Aftrtrtmnt1OtletNH3ReadingStable "J1939-71";
BA_ "SPN" SG_ 2364548606 Aftrtrtmnt1OtltNH3SnsrPrlmnryFMI 4378;
BA_ "SAEDocument" SG_ 2364548606 Aftrtrtmnt1OtltNH3SnsrPrlmnryFMI "J1939-71";
BA_ "SigType" SG_ 2364548606 Aftertreatment1OutletNH3 1;
BA_ "SPN" SG_ 2364548606 Aftertreatment1OutletNH3 4377;
BA_ "SAEDocument" SG_ 2364548606 Aftertreatment1OutletNH3 "J1939-71";
BA_ "SPN" SG_ 2566726398 GsOxdtnCtlystDffPrssP_PerlimFMI 4758;
BA_ "SAEDocument" SG_ 2566726398 GsOxdtnCtlystDffPrssP_PerlimFMI "J1939-71";
BA_ "SigType" SG_ 2566726398 GsOxdtnCtlystOtltGsTm_PerlimFMI 1;
BA_ "SPN" SG_ 2566726398 GsOxdtnCtlystOtltGsTm_PerlimFMI 4754;
BA_ "SAEDocument" SG_ 2566726398 GsOxdtnCtlystOtltGsTm_PerlimFMI "J1939-71";
BA_ "SigType" SG_ 2566726398 GsOxdtnCtlystIntkGsTm_PerlimFMI 1;
BA_ "SPN" SG_ 2566726398 GsOxdtnCtlystIntkGsTm_PerlimFMI 4753;
BA_ "SAEDocument" SG_ 2566726398 GsOxdtnCtlystIntkGsTm_PerlimFMI "J1939-71";
BA_ "SigType" SG_ 2566726398 Aftrtrtmnt1GsOxdtnCtlystDffPress 1;
BA_ "SPN" SG_ 2566726398 Aftrtrtmnt1GsOxdtnCtlystDffPress 4755;
BA_ "SAEDocument" SG_ 2566726398 Aftrtrtmnt1GsOxdtnCtlystDffPress "J1939-71";
BA_ "SigType" SG_ 2566742270 FailureSpecificB1Counter 1;
BA_ "SPN" SG_ 2566742270 FailureSpecificB1Counter 4147;
BA_ "SAEDocument" SG_ 2566742270 FailureSpecificB1Counter "J1939_73";
BA_ "SPN" SG_ 2566742270 FailureModeIdentifier1 1215;
BA_ "SAEDocument" SG_ 2566742270 FailureModeIdentifier1 "J1939-73";
BA_ "SAEDocument" SG_ 2566742270 SPN1High "J1939-73";
BA_ "SPN" SG_ 2566742270 SPN1 1214;
BA_ "SAEDocument" SG_ 2566742270 SPN1 "J1939-73";
BA_ "SigType" SG_ 2566742526 SysGreatestB1Counter 1;
BA_ "SPN" SG_ 2566742526 SysGreatestB1Counter 4146;
BA_ "SAEDocument" SG_ 2566742526 SysGreatestB1Counter "J1939_73";
BA_ "SigType" SG_ 2566742526 SysCumulativeContinuousMITime 1;
BA_ "SPN" SG_ 2566742526 SysCumulativeContinuousMITime 4145;
BA_ "SAEDocument" SG_ 2566742526 SysCumulativeContinuousMITime "J1939_73";
BA_ "SigType" SG_ 2566742782 RegulationDescription 8;
BA_ "SPN" SG_ 2566742782 RegulationDescription 4144;
BA_ "SAEDocument" SG_ 2566742782 RegulationDescription "J1939_73";
BA_ "SigType" SG_ 2566743038 SysIncompleteMonitorCount 1;
BA_ "SPN" SG_ 2566743038 SysIncompleteMonitorCount 4143;
BA_ "SAEDocument" SG_ 2566743038 SysIncompleteMonitorCount "J1939_73";
BA_ "SPN" SG_ 2566743038 SysMalIndActivationMode 4142;
BA_ "SAEDocument" SG_ 2566743038 SysMalIndActivationMode "J1939_73";
BA_ "SigType" SG_ 2566743038 SysMalIndDisplayStrategy 4;
BA_ "SPN" SG_ 2566743038 SysMalIndDisplayStrategy 4141;
BA_ "SAEDocument" SG_ 2566743038 SysMalIndDisplayStrategy "J1939_73";
BA_ "SigType" SG_ 2566743038 SysContinuousMalfunctionInd 4;
BA_ "SPN" SG_ 2566743038 SysContinuousMalfunctionInd 4140;
BA_ "SAEDocument" SG_ 2566743038 SysContinuousMalfunctionInd "J1939_73";
BA_ "SigType" SG_ 2566743038 SysNonRoadworthyCompCount 1;
BA_ "SPN" SG_ 2566743038 SysNonRoadworthyCompCount 4139;
BA_ "SAEDocument" SG_ 2566743038 SysNonRoadworthyCompCount "J1939_73";
BA_ "SigType" SG_ 2566743294 VehicleCurrentMIAccumTime 1;
BA_ "SPN" SG_ 2566743294 VehicleCurrentMIAccumTime 4138;
BA_ "SAEDocument" SG_ 2566743294 VehicleCurrentMIAccumTime "J1939_73";
BA_ "SigType" SG_ 2566743294 VehicleIncompleteMonitorCount 1;
BA_ "SPN" SG_ 2566743294 VehicleIncompleteMonitorCount 4137;
BA_ "SAEDocument" SG_ 2566743294 VehicleIncompleteMonitorCount "J1939_73";
BA_ "SigType" SG_ 2566743294 VehicleMalfunctionIndActMode 4;
BA_ "SPN" SG_ 2566743294 VehicleMalfunctionIndActMode 4136;
BA_ "SAEDocument" SG_ 2566743294 VehicleMalfunctionIndActMode "J1939_73";
BA_ "SigType" SG_ 2566743294 VehicleMalfunctionIndStrategy 4;
BA_ "SPN" SG_ 2566743294 VehicleMalfunctionIndStrategy 4135;
BA_ "SAEDocument" SG_ 2566743294 VehicleMalfunctionIndStrategy "J1939_73";
BA_ "SigType" SG_ 2566743294 VehicleContinuousMalfunctionInd 4;
BA_ "SPN" SG_ 2566743294 VehicleContinuousMalfunctionInd 4134;
BA_ "SAEDocument" SG_ 2566743294 VehicleContinuousMalfunctionInd "J1939_73";
BA_ "SigType" SG_ 2566743294 VehicleNonRoadworthyCompCount 1;
BA_ "SPN" SG_ 2566743294 VehicleNonRoadworthyCompCount 4133;
BA_ "SAEDocument" SG_ 2566743294 VehicleNonRoadworthyCompCount "J1939_73";
BA_ "SigType" SG_ 2560687870 PMNTEDeficiencyAreaStatus 4;
BA_ "SPN" SG_ 2560687870 PMNTEDeficiencyAreaStatus 4132;
BA_ "SAEDocument" SG_ 2560687870 PMNTEDeficiencyAreaStatus "J1939_73";
BA_ "SigType" SG_ 2560687870 MnfcPMNTECarveOutAreaStatus 4;
BA_ "SPN" SG_ 2560687870 MnfcPMNTECarveOutAreaStatus 4131;
BA_ "SAEDocument" SG_ 2560687870 MnfcPMNTECarveOutAreaStatus "J1939_73";
BA_ "SigType" SG_ 2560687870 PMNTEControlAreaStatus 4;
BA_ "SPN" SG_ 2560687870 PMNTEControlAreaStatus 4130;
BA_ "SAEDocument" SG_ 2560687870 PMNTEControlAreaStatus "J1939_73";
BA_ "SigType" SG_ 2560687870 NOxNTEDeficiencyAreaStatus 4;
BA_ "SPN" SG_ 2560687870 NOxNTEDeficiencyAreaStatus 4129;
BA_ "SAEDocument" SG_ 2560687870 NOxNTEDeficiencyAreaStatus "J1939_73";
BA_ "SigType" SG_ 2560687870 MnfcNOxNTECarveOutAreaStatus 4;
BA_ "SPN" SG_ 2560687870 MnfcNOxNTECarveOutAreaStatus 4128;
BA_ "SAEDocument" SG_ 2560687870 MnfcNOxNTECarveOutAreaStatus "J1939_73";
BA_ "SigType" SG_ 2560687870 NOxNTEControlAreaStatus 4;
BA_ "SPN" SG_ 2560687870 NOxNTEControlAreaStatus 4127;
BA_ "SAEDocument" SG_ 2560687870 NOxNTEControlAreaStatus "J1939_73";
BA_ "SigType" SG_ 2292317950 AECDEngineHours1Timer2 1;
BA_ "SPN" SG_ 2292317950 AECDEngineHours1Timer2 4126;
BA_ "SAEDocument" SG_ 2292317950 AECDEngineHours1Timer2 "J1939_73";
BA_ "SigType" SG_ 2292317950 AECDEngineHours1Timer1 1;
BA_ "SPN" SG_ 2292317950 AECDEngineHours1Timer1 4125;
BA_ "SAEDocument" SG_ 2292317950 AECDEngineHours1Timer1 "J1939_73";
BA_ "SigType" SG_ 2292317950 AECDNumber1 1;
BA_ "SPN" SG_ 2292317950 AECDNumber1 4124;
BA_ "SAEDocument" SG_ 2292317950 AECDNumber1 "J1939_73";
BA_ "SigType" SG_ 2566809342 BatteryMainSwitchHoldState 4;
BA_ "SPN" SG_ 2566809342 BatteryMainSwitchHoldState 1681;
BA_ "SAEDocument" SG_ 2566809342 BatteryMainSwitchHoldState "J1939-71";
VAL_ 2365401854 Joystick7Button9PressedStatus 3 "Not Available" 2 "Error Indicator" 1 "Button pressed" 0 "Button not pressed" ;
VAL_ 2365401854 Joystick7Button10PressedStatus 3 "Not Available" 2 "Error Indicator" 1 "Button pressed" 0 "Button not pressed" ;
VAL_ 2365401854 Joystick7Button11PressedStatus 3 "Not Available" 2 "Error Indicator" 1 "Button pressed" 0 "Button not pressed" ;
VAL_ 2365401854 Joystick7Button12PressedStatus 3 "Not Available" 2 "Error Indicator" 1 "Button pressed" 0 "Button not pressed" ;
VAL_ 2365401854 Joystick7Button5PressedStatus 3 "Not Available" 2 "Error Indicator" 1 "Button pressed" 0 "Button not pressed" ;
VAL_ 2365401854 Joystick7Button6PressedStatus 3 "Not Available" 2 "Error Indicator" 1 "Button pressed" 0 "Button not pressed" ;
VAL_ 2365401854 Joystick7Button7PressedStatus 3 "Not Available" 2 "Error Indicator" 1 "Button pressed" 0 "Button not pressed" ;
VAL_ 2365401854 Joystick7Button8PressedStatus 3 "Not Available" 2 "Error Indicator" 1 "Button pressed" 0 "Button not pressed" ;
VAL_ 2365401854 Joystick7Button1PressedStatus 3 "Not Available" 2 "Error Indicator" 1 "Button pressed" 0 "Button not pressed" ;
VAL_ 2365401854 Joystick7Button2PressedStatus 3 "Not Available" 2 "Error Indicator" 1 "Button pressed" 0 "Button not pressed" ;
VAL_ 2365401854 Joystick7Button3PressedStatus 3 "Not Available" 2 "Error Indicator" 1 "Button pressed" 0 "Button not pressed" ;
VAL_ 2365401854 Joystick7Button4PressedStatus 3 "Not Available" 2 "Error Indicator" 1 "Button pressed" 0 "Button not pressed" ;
VAL_ 2365401854 Joystick7XAxisDetentPosStatus 3 "Not Available" 2 "Error Indicator" 1 "In the Detent Position" 0 "Not in the Detent Position" ;
VAL_ 2365401854 Joystick7YAxisDetentPosStatus 3 "Not Available" 2 "Error Indicator" 1 "In the Detent Position" 0 "Not in the Detent Position" ;
VAL_ 2365401854 Jystck7YAxsLvrFrwrdPstvPosStatus 3 "Not Available" 2 "Error Indicator" 1 "On positive side of Neutral" 0 "Not on Positive side of Neutral" ;
VAL_ 2365401854 Jystck7YAxsLvrBckNgtivePosStatus 3 "Not Available" 2 "Error Indicator" 1 "On negative side of Neutral" 0 "Not on negative side of Neutral" ;
VAL_ 2365401854 Joystick7YAxisNeutralPosStatus 3 "Not Available" 2 "Error Indicator" 1 "In Neutral Position" 0 "Not in Neutral Position" ;
VAL_ 2365401854 Jystck7XAxsLvrRghtPstvePosStatus 3 "Not Available" 2 "Error Indicator" 1 "On positive side of Neutral" 0 "Not on Positive side of Neutral" ;
VAL_ 2365401854 Jystck7XAxsLvrLftNgtivePosStatus 3 "Not Available" 2 "Error Indicator" 1 "On negative side of Neutral" 0 "Not on negative side of Neutral" ;
VAL_ 2365401854 Joystick7XAxisNeutralPosStatus 3 "Not Available" 2 "Error Indicator" 1 "In Neutral Position" 0 "Not in Neutral Position" ;
VAL_ 2365402366 Joystick6Button9PressedStatus 3 "Not Available" 2 "Error Indicator" 1 "Button pressed" 0 "Button not pressed" ;
VAL_ 2365402366 Joystick6Button10PressedStatus 3 "Not Available" 2 "Error Indicator" 1 "Button pressed" 0 "Button not pressed" ;
VAL_ 2365402366 Joystick6Button11PressedStatus 3 "Not Available" 2 "Error Indicator" 1 "Button pressed" 0 "Button not pressed" ;
VAL_ 2365402366 Joystick6Button12PressedStatus 3 "Not Available" 2 "Error Indicator" 1 "Button pressed" 0 "Button not pressed" ;
VAL_ 2365402366 Joystick6Button5PressedStatus 3 "Not Available" 2 "Error Indicator" 1 "Button pressed" 0 "Button not pressed" ;
VAL_ 2365402366 Joystick6Button6PressedStatus 3 "Not Available" 2 "Error Indicator" 1 "Button pressed" 0 "Button not pressed" ;
VAL_ 2365402366 Joystick6Button7PressedStatus 3 "Not Available" 2 "Error Indicator" 1 "Button pressed" 0 "Button not pressed" ;
VAL_ 2365402366 Joystick6Button8PressedStatus 3 "Not Available" 2 "Error Indicator" 1 "Button pressed" 0 "Button not pressed" ;
VAL_ 2365402366 Joystick6Button1PressedStatus 3 "Not Available" 2 "Error Indicator" 1 "Button pressed" 0 "Button not pressed" ;
VAL_ 2365402366 Joystick6Button2PressedStatus 3 "Not Available" 2 "Error Indicator" 1 "Button pressed" 0 "Button not pressed" ;
VAL_ 2365402366 Joystick6Button3PressedStatus 3 "Not Available" 2 "Error Indicator" 1 "Button pressed" 0 "Button not pressed" ;
VAL_ 2365402366 Joystick6Button4PressedStatus 3 "Not Available" 2 "Error Indicator" 1 "Button pressed" 0 "Button not pressed" ;
VAL_ 2365402366 Joystick6XAxisDetentPosStatus 3 "Not Available" 2 "Error Indicator" 1 "In the Detent Position" 0 "Not in the Detent Position" ;
VAL_ 2365402366 Joystick6YAxisDetentPosStatus 3 "Not Available" 2 "Error Indicator" 1 "In the Detent Position" 0 "Not in the Detent Position" ;
VAL_ 2365402366 Jystck6YAxsLvrFrwrdPstvPosStatus 3 "Not Available" 2 "Error Indicator" 1 "On positive side of Neutral" 0 "Not on Positive side of Neutral" ;
VAL_ 2365402366 Jystck6YAxsLvrBckNgtivePosStatus 3 "Not Available" 2 "Error Indicator" 1 "On negative side of Neutral" 0 "Not on negative side of Neutral" ;
VAL_ 2365402366 Joystick6YAxisNeutralPosStatus 3 "Not Available" 2 "Error Indicator" 1 "In Neutral Position" 0 "Not in Neutral Position" ;
VAL_ 2365402366 Jystck6XAxsLvrRghtPstvePosStatus 3 "Not Available" 2 "Error Indicator" 1 "On positive side of Neutral" 0 "Not on Positive side of Neutral" ;
VAL_ 2365402366 Jystck6XAxsLvrLftNgtivePosStatus 3 "Not Available" 2 "Error Indicator" 1 "On negative side of Neutral" 0 "Not on negative side of Neutral" ;
VAL_ 2365402366 Joystick6XAxisNeutralPosStatus 3 "Not Available" 2 "Error Indicator" 1 "In Neutral Position" 0 "Not in Neutral Position" ;
VAL_ 2365402878 Joystick5Button9PressedStatus 3 "Not Available" 2 "Error Indicator" 1 "Button pressed" 0 "Button not pressed" ;
VAL_ 2365402878 Joystick5Button10PressedStatus 3 "Not Available" 2 "Error Indicator" 1 "Button pressed" 0 "Button not pressed" ;
VAL_ 2365402878 Joystick5Button11PressedStatus 3 "Not Available" 2 "Error Indicator" 1 "Button pressed" 0 "Button not pressed" ;
VAL_ 2365402878 Joystick5Button12PressedStatus 3 "Not Available" 2 "Error Indicator" 1 "Button pressed" 0 "Button not pressed" ;
VAL_ 2365402878 Joystick5Button5PressedStatus 3 "Not Available" 2 "Error Indicator" 1 "Button pressed" 0 "Button not pressed" ;
VAL_ 2365402878 Joystick5Button6PressedStatus 3 "Not Available" 2 "Error Indicator" 1 "Button pressed" 0 "Button not pressed" ;
VAL_ 2365402878 Joystick5Button7PressedStatus 3 "Not Available" 2 "Error Indicator" 1 "Button pressed" 0 "Button not pressed" ;
VAL_ 2365402878 Joystick5Button8PressedStatus 3 "Not Available" 2 "Error Indicator" 1 "Button pressed" 0 "Button not pressed" ;
VAL_ 2365402878 Joystick5Button1PressedStatus 3 "Not Available" 2 "Error Indicator" 1 "Button pressed" 0 "Button not pressed" ;
VAL_ 2365402878 Joystick5Button2PressedStatus 3 "Not Available" 2 "Error Indicator" 1 "Button pressed" 0 "Button not pressed" ;
VAL_ 2365402878 Joystick5Button3PressedStatus 3 "Not Available" 2 "Error Indicator" 1 "Button pressed" 0 "Button not pressed" ;
VAL_ 2365402878 Joystick5Button4PressedStatus 3 "Not Available" 2 "Error Indicator" 1 "Button pressed" 0 "Button not pressed" ;
VAL_ 2365402878 Joystick5XAxisDetentPosStatus 3 "Not Available" 2 "Error Indicator" 1 "In the Detent Position" 0 "Not in the Detent Position" ;
VAL_ 2365402878 Joystick5YAxisDetentPosStatus 3 "Not Available" 2 "Error Indicator" 1 "In the Detent Position" 0 "Not in the Detent Position" ;
VAL_ 2365402878 Jystck5YAxsLvrFrwrdPstvPosStatus 3 "Not Available" 2 "Error Indicator" 1 "On positive side of Neutral" 0 "Not on Positive side of Neutral" ;
VAL_ 2365402878 Jystck5YAxsLvrBckNgtivePosStatus 3 "Not Available" 2 "Error Indicator" 1 "On negative side of Neutral" 0 "Not on negative side of Neutral" ;
VAL_ 2365402878 Joystick5YAxisNeutralPosStatus 3 "Not Available" 2 "Error Indicator" 1 "In Neutral Position" 0 "Not in Neutral Position" ;
VAL_ 2365402878 Jystck5XAxsLvrRghtPstvePosStatus 3 "Not Available" 2 "Error Indicator" 1 "On positive side of Neutral" 0 "Not on Positive side of Neutral" ;
VAL_ 2365402878 Jystck5XAxsLvrLftNgtivePosStatus 3 "Not Available" 2 "Error Indicator" 1 "On negative side of Neutral" 0 "Not on negative side of Neutral" ;
VAL_ 2365402878 Joystick5XAxisNeutralPosStatus 3 "Not Available" 2 "Error Indicator" 1 "In Neutral Position" 0 "Not in Neutral Position" ;
VAL_ 2365403390 Joystick4Button9PressedStatus 3 "Not Available" 2 "Error Indicator" 1 "Button pressed" 0 "Button not pressed" ;
VAL_ 2365403390 Joystick4Button10PressedStatus 3 "Not Available" 2 "Error Indicator" 1 "Button pressed" 0 "Button not pressed" ;
VAL_ 2365403390 Joystick4Button11PressedStatus 3 "Not Available" 2 "Error Indicator" 1 "Button pressed" 0 "Button not pressed" ;
VAL_ 2365403390 Joystick4Button12PressedStatus 3 "Not Available" 2 "Error Indicator" 1 "Button pressed" 0 "Button not pressed" ;
VAL_ 2365403390 Joystick4Button5PressedStatus 3 "Not Available" 2 "Error Indicator" 1 "Button pressed" 0 "Button not pressed" ;
VAL_ 2365403390 Joystick4Button6PressedStatus 3 "Not Available" 2 "Error Indicator" 1 "Button pressed" 0 "Button not pressed" ;
VAL_ 2365403390 Joystick4Button7PressedStatus 3 "Not Available" 2 "Error Indicator" 1 "Button pressed" 0 "Button not pressed" ;
VAL_ 2365403390 Joystick4Button8PressedStatus 3 "Not Available" 2 "Error Indicator" 1 "Button pressed" 0 "Button not pressed" ;
VAL_ 2365403390 Joystick4Button1PressedStatus 3 "Not Available" 2 "Error Indicator" 1 "Button pressed" 0 "Button not pressed" ;
VAL_ 2365403390 Joystick4Button2PressedStatus 3 "Not Available" 2 "Error Indicator" 1 "Button pressed" 0 "Button not pressed" ;
VAL_ 2365403390 Joystick4Button3PressedStatus 3 "Not Available" 2 "Error Indicator" 1 "Button pressed" 0 "Button not pressed" ;
VAL_ 2365403390 Joystick4Button4PressedStatus 3 "Not Available" 2 "Error Indicator" 1 "Button pressed" 0 "Button not pressed" ;
VAL_ 2365403390 Joystick4XAxisDetentPosStatus 3 "Not Available" 2 "Error Indicator" 1 "In the Detent Position" 0 "Not in the Detent Position" ;
VAL_ 2365403390 Joystick4YAxisDetentPosStatus 3 "Not Available" 2 "Error Indicator" 1 "In the Detent Position" 0 "Not in the Detent Position" ;
VAL_ 2365403390 Jystck4YAxsLvrFrwrdPstvPosStatus 3 "Not Available" 2 "Error Indicator" 1 "On positive side of Neutral" 0 "Not on Positive side of Neutral" ;
VAL_ 2365403390 Jystck4YAxsLvrBckNgtivePosStatus 3 "Not Available" 2 "Error Indicator" 1 "On negative side of Neutral" 0 "Not on negative side of Neutral" ;
VAL_ 2365403390 Joystick4YAxisNeutralPosStatus 3 "Not Available" 2 "Error Indicator" 1 "In Neutral Position" 0 "Not in Neutral Position" ;
VAL_ 2365403390 Jystck4XAxsLvrRghtPstvePosStatus 3 "Not Available" 2 "Error Indicator" 1 "On positive side of Neutral" 0 "Not on Positive side of Neutral" ;
VAL_ 2365403390 Jystck4XAxsLvrLftNgtivePosStatus 3 "Not Available" 2 "Error Indicator" 1 "On negative side of Neutral" 0 "Not on negative side of Neutral" ;
VAL_ 2365403390 Joystick4XAxisNeutralPosStatus 3 "Not Available" 2 "Error Indicator" 1 "In Neutral Position" 0 "Not in Neutral Position" ;
VAL_ 2365400318 Joystick10Button9PressedStatus 3 "Not Available" 2 "Error Indicator" 1 "Button pressed" 0 "Button not pressed" ;
VAL_ 2365400318 Joystick10Button10PressedStatus 3 "Not Available" 2 "Error Indicator" 1 "Button pressed" 0 "Button not pressed" ;
VAL_ 2365400318 Joystick10Button11PressedStatus 3 "Not Available" 2 "Error Indicator" 1 "Button pressed" 0 "Button not pressed" ;
VAL_ 2365400318 Joystick10Button12PressedStatus 3 "Not Available" 2 "Error Indicator" 1 "Button pressed" 0 "Button not pressed" ;
VAL_ 2365400318 Joystick10Button5PressedStatus 3 "Not Available" 2 "Error Indicator" 1 "Button pressed" 0 "Button not pressed" ;
VAL_ 2365400318 Joystick10Button6PressedStatus 3 "Not Available" 2 "Error Indicator" 1 "Button pressed" 0 "Button not pressed" ;
VAL_ 2365400318 Joystick10Button7PressedStatus 3 "Not Available" 2 "Error Indicator" 1 "Button pressed" 0 "Button not pressed" ;
VAL_ 2365400318 Joystick10Button8PressedStatus 3 "Not Available" 2 "Error Indicator" 1 "Button pressed" 0 "Button not pressed" ;
VAL_ 2365400318 Joystick10Button1PressedStatus 3 "Not Available" 2 "Error Indicator" 1 "Button pressed" 0 "Button not pressed" ;
VAL_ 2365400318 Joystick10Button2PressedStatus 3 "Not Available" 2 "Error Indicator" 1 "Button pressed" 0 "Button not pressed" ;
VAL_ 2365400318 Joystick10Button3PressedStatus 3 "Not Available" 2 "Error Indicator" 1 "Button pressed" 0 "Button not pressed" ;
VAL_ 2365400318 Joystick10Button4PressedStatus 3 "Not Available" 2 "Error Indicator" 1 "Button pressed" 0 "Button not pressed" ;
VAL_ 2365400318 Joystick10XAxisDetentPosStatus 3 "Not Available" 2 "Error Indicator" 1 "In the Detent Position" 0 "Not in the Detent Position" ;
VAL_ 2365400318 Joystick10YAxisDetentPosStatus 3 "Not Available" 2 "Error Indicator" 1 "In the Detent Position" 0 "Not in the Detent Position" ;
VAL_ 2365400318 Jystck10YAxsLvrFrwrdPstvPsStatus 3 "Not Available" 2 "Error Indicator" 1 "On positive side of Neutral" 0 "Not on Positive side of Neutral" ;
VAL_ 2365400318 Jystck10YAxsLvrBckNgtvePosStatus 3 "Not Available" 2 "Error Indicator" 1 "On negative side of Neutral" 0 "Not on negative side of Neutral" ;
VAL_ 2365400318 Joystick10YAxisNeutralPosStatus 3 "Not Available" 2 "Error Indicator" 1 "In Neutral Position" 0 "Not in Neutral Position" ;
VAL_ 2365400318 Jystck10XAxsLvrRghtPstvPosStatus 3 "Not Available" 2 "Error Indicator" 1 "On positive side of Neutral" 0 "Not on Positive side of Neutral" ;
VAL_ 2365400318 Jystck10XAxsLvrLftNgtvePosStatus 3 "Not Available" 2 "Error Indicator" 1 "On negative side of Neutral" 0 "Not on negative side of Neutral" ;
VAL_ 2365400318 Joystick10XAxisNeutralPosStatus 3 "Not Available" 2 "Error Indicator" 1 "In Neutral Position" 0 "Not in Neutral Position" ;
VAL_ 2499614718 PssngrArbgDctivationSwitchStatus 3 "not available" 2 "Error  State of deactivation switch cannot be determined" 1 "passenger airbag deactivated" 0 "passenger airbag activated" ;
VAL_ 2499614718 Beltlock10Status 3 "not available" 2 "Error  Beltlock state cannot be determined" 1 "locked" 0 "unlocked" ;
VAL_ 2499614718 Beltlock9Status 3 "not available" 2 "Error  Beltlock state cannot be determined" 1 "locked" 0 "unlocked" ;
VAL_ 2499614718 Beltlock8Status 3 "not available" 2 "Error  Beltlock state cannot be determined" 1 "locked" 0 "unlocked" ;
VAL_ 2499614718 Beltlock7Status 3 "not available" 2 "Error  Beltlock state cannot be determined" 1 "locked" 0 "unlocked" ;
VAL_ 2499614718 Beltlock6Status 3 "not available" 2 "Error  Beltlock state cannot be determined" 1 "locked" 0 "unlocked" ;
VAL_ 2499614718 Beltlock5Status 3 "not available" 2 "Error  Beltlock state cannot be determined" 1 "locked" 0 "unlocked" ;
VAL_ 2499614718 Beltlock4Status 3 "not available" 2 "Error  Beltlock state cannot be determined" 1 "locked" 0 "unlocked" ;
VAL_ 2499614718 Beltlock3Status 3 "not available" 2 "Error  Beltlock state cannot be determined" 1 "locked" 0 "unlocked" ;
VAL_ 2499614718 PassengerBeltlockStatus 3 "not available" 2 "Error  Beltlock state cannot be determined" 1 "locked" 0 "unlocked" ;
VAL_ 2499614718 DriverBeltlockStatus 3 "not available" 2 "Error  Beltlock state cannot be determined" 1 "locked" 0 "unlocked" ;
VAL_ 2566735102 Aftrtrtmnt2FlFlwDverterValveCtrl 3 "not available" 2 "reserved for SAE assignment" 1 "on" 0 "off" ;
VAL_ 2566735102 Aftertreatment2FuelPumpRelayCtrl 3 "not available" 2 "reserved for SAE assignment" 1 "on" 0 "off" ;
VAL_ 2566805246 AftrtrtmntSCROprtrIndcmntSverity 7 "Not Available / Not Supported" 6 "Reserved" 5 "Inducement Level 5" 4 "Inducement Level 4" 3 "Inducement Level 3" 2 "Inducement Level 2" 1 "Inducement Level 1" 0 "No Inducement Active" ;
VAL_ 2566805246 Aftrtrtmnt1DEFTnkLwLvelIndicator 5 "reserved for SAE assignment" 3 "reserved for SAE assignment" 2 "reserved for SAE assignment" 7 "not available" 4 "On  fast blink 1 HZ" 6 "reserved for SAE assignment" 1 "On  solid" 0 "Off" ;
VAL_ 2566711806 ArmrestSwitchMatrix2Switch2 0 "Off" ;
VAL_ 2566711806 ArmrestSwitchMatrix2Switch1 0 "Off" ;
VAL_ 2566711806 ArmrestSwitchMatrixSwitch2 0 "Off" ;
VAL_ 2566711806 ArmrestSwitchMatrixSwitch1 0 "Off" ;
VAL_ 2364549886 YawRateExRangeFigureOfMerit 3 "Not available" 2 "Error" 1 "Yaw rate degraded Data is suspect due to environmental conditions" 0 "Yaw rate fully functional Data is within sensor specification" ;
VAL_ 2364549886 RollRateExRangeFigureOfMerit 3 "Not available" 2 "Error" 1 "Roll rate degraded Data is suspect due to environmental conditions" 0 "Roll rate fully functional Data is within sensor specification" ;
VAL_ 2364549886 PitchRateExRangeFigureOfMerit 3 "Not available" 2 "Error" 1 "Pitch rate degraded Data is suspect due to environmental conditions" 0 "Pitch rate fully functional Data is within sensor specification" ;
VAL_ 2566712318 Aftrtrtmnt2NOxAdsrbrDSOxRgnrtnSt 3 "Not available" 2 "Error indicator" 1 "Active" 0 "Inactive" ;
VAL_ 2566712318 Aftrtrtmnt2NOxAdsrbrDNOxRgnrtnSt 3 "Not available" 2 "Error indicator" 1 "Active" 0 "Inactive" ;
VAL_ 2566712574 Aftrtrtmnt1NOxAdsrbrDSOxRgnrtnSt 3 "Not available" 2 "Error indicator" 1 "Active" 0 "Inactive" ;
VAL_ 2566712574 Aftrtrtmnt1NOxAdsrbrDNOxRgnrtnSt 3 "Not available" 2 "Error indicator" 1 "Active" 0 "Inactive" ;
VAL_ 2566730750 Aftrtrtmnt2SCRCtlystRgntPmpState 3 "not available" 2 "reserved for SAE assignment" 1 "pump error" 0 "pump operational" ;
VAL_ 2566731518 Aftrtrtmnt2SCRCtalystReagentType 15 "Not available" 14 "Error detected with urea reagent type detection" 13 "Not able to determine catalyst reagent type type unknown" 5 "to 1100  Reserved for SAE assignment" 3 "Catalyst reagent is proper mixture" 2 "Catalyst reagent is diesel" 1 "Catalyst reagent is urea concentration too low" 0 "Catalyst reagent is urea concentration too high" ;
VAL_ 2164079358 Aftrtrtmnt2SCRCtlystRgntLnHater4 3 "not available" 2 "reserved for future assignment by SAE" 1 "request for heater to be active" 0 "request for heater to be inactive" ;
VAL_ 2164079358 Aftrtrtmnt2SCRCtlystRgntLnHater3 3 "not available" 2 "reserved for future assignment by SAE" 1 "request for heater to be active" 0 "request for heater to be inactive" ;
VAL_ 2164079358 Aftrtrtmnt2SCRCtlystRgntLnHater2 3 "not available" 2 "reserved for future assignment by SAE" 1 "request for heater to be active" 0 "request for heater to be inactive" ;
VAL_ 2164079358 Aftrtrtmnt2SCRCtlystRgntLnHater1 3 "not available" 2 "reserved for future assignment by SAE" 1 "request for heater to be active" 0 "request for heater to be inactive" ;
VAL_ 2164079358 Aftrtrtmnt2SCRDoserHeatingModeRq 7 "Not available" 4 "110 Reserved" 3 "Heater on" 2 "Heater automatic mode" 1 "Heater economy mode" 0 "Heater off" ;
VAL_ 2164079358 Aftrtrtmnt2SCRDsrFltSppressionRq 3 "Not available" 2 "Reserved" 1 "Error suppression on" 0 "Error suppression off" ;
VAL_ 2364549118 Aftrtrtmnt2SCRSystmRquestedState 15 "Not available" 14 "Error" 10 "Service test mode dosing not allowed" 9 "Service test mode dosing allowed" 8 "Diagnosis afterrun" 7 "Shutoff wait for afterrun" 6 "Protect mode against cold defreeze" 5 "Protect mode against heat pressure buildup" 4 "Reserved for future assignment by SAE" 3 "System error pending" 2 "Normal dosing operation" 1 "Preparing dosing readiness wake up prepare to operate wait for start" 0 "Dormant sleep mode" ;
VAL_ 2566732798 Aftrtrtmnt2SCRCtlystRgntLnHtr4St 3 "not available" 2 "error" 1 "heater active" 0 "heater inactive" ;
VAL_ 2566732798 Aftrtrtmnt2SCRCtlystRgntLnHtr3St 3 "not available" 2 "error" 1 "heater active" 0 "heater inactive" ;
VAL_ 2566732798 Aftrtrtmnt2SCRCtlystRgntLnHtr2St 3 "not available" 2 "error" 1 "heater active" 0 "heater inactive" ;
VAL_ 2566732798 Aftrtrtmnt2SCRCtlystRgntLnHtr1St 3 "not available" 2 "error" 1 "heater active" 0 "heater inactive" ;
VAL_ 2566732798 Aftrtrtmnt2SCRFeedbackCtrlStatus 4 "reserved for future assignment by SAE" 3 "reserved for future assignment by SAE" 2 "reserved for future assignment by SAE" 7 "not available" 6 "error" 5 "reserved for future assignment by SAE" 1 "closed loop control active" 0 "open loop control active" ;
VAL_ 2364548862 Aftertreatment2SCRSystemState 15 "Not available" 14 "Error" 10 "Service test mode dosing not allowed" 9 "Service test mode dosing allowed" 8 "Diagnosis afterrun" 7 "Shutoff wait for afterrun" 6 "Protect mode against cold defreeze" 5 "Protect mode against heat pressure buildup" 4 "Reserved for future assignment by SAE" 3 "System error pending" 2 "Normal dosing operation" 1 "Preparing dosing readiness wake up prepare to operate wait for start" 0 "Dormant sleep mode" ;
VAL_ 2364549374 Aftrtrtmnt2OtltNH3GsSnsrHterCtrl 3 "Heater off or Not available" 2 "Preheat 1" 1 "Preheat 2" 0 "Automatic" ;
VAL_ 2566733054 Aftrtrtmnt1SCRCtlystRgntPmpState 3 "not available" 2 "reserved for SAE assignment" 1 "pump error" 0 "pump operational" ;
VAL_ 2566734078 Aftrtrtmnt1SCRCtlystRgntLnHater4 3 "not available" 2 "reserved for future assignment by SAE" 1 "request for heater to be active" 0 "request for heater to be inactive" ;
VAL_ 2566734078 Aftrtrtmnt1SCRCtlystRgntLnHater3 3 "not available" 2 "reserved for future assignment by SAE" 1 "request for heater to be active" 0 "request for heater to be inactive" ;
VAL_ 2566734078 Aftrtrtmnt1SCRCtlystRgntLnHater2 3 "not available" 2 "reserved for future assignment by SAE" 1 "request for heater to be active" 0 "request for heater to be inactive" ;
VAL_ 2566734078 Aftrtrtmnt1SCRCtlystRgntLnHater1 3 "not available" 2 "reserved for future assignment by SAE" 1 "request for heater to be active" 0 "request for heater to be inactive" ;
VAL_ 2566734078 Aftrtrtmnt1SCRDoserHeatingModeRq 7 "Not available" 4 "110 Reserved" 3 "Heater on" 2 "Heater automatic mode" 1 "Heater economy mode" 0 "Heater off" ;
VAL_ 2566734078 Aftrtrtmnt1SCRDsrFltSppressionRq 3 "Not available" 2 "Reserved" 1 "Error suppression on" 0 "Error suppression off" ;
VAL_ 2364548350 Aftrtrtmnt1SCRSystmRquestedState 15 "Not available" 14 "Error" 10 "Service test mode dosing not allowed" 9 "Service test mode dosing allowed" 8 "Diagnosis afterrun" 7 "Shutoff wait for afterrun" 6 "Protect mode against cold defreeze" 5 "Protect mode against heat pressure buildup" 4 "Reserved for future assignment by SAE" 3 "System error pending" 2 "Normal dosing operation" 1 "Preparing dosing readiness wake up prepare to operate wait for start" 0 "Dormant sleep mode" ;
VAL_ 2566734334 Aftrtrtmnt1SCRCtlystRgntLnHtr4St 3 "not available" 2 "error" 1 "heater active" 0 "heater inactive" ;
VAL_ 2566734334 Aftrtrtmnt1SCRCtlystRgntLnHtr3St 3 "not available" 2 "error" 1 "heater active" 0 "heater inactive" ;
VAL_ 2566734334 Aftrtrtmnt1SCRCtlystRgntLnHtr2St 3 "not available" 2 "error" 1 "heater active" 0 "heater inactive" ;
VAL_ 2566734334 Aftrtrtmnt1SCRCtlystRgntLnHtr1St 3 "not available" 2 "error" 1 "heater active" 0 "heater inactive" ;
VAL_ 2566734334 Aftrtrtmnt1SCRFeedbackCtrlStatus 7 "not available" 4 "reserved for future assignment by SAE" 3 "reserved for future assignment by SAE" 2 "reserved for future assignment by SAE" 6 "error" 5 "reserved for future assignment by SAE" 1 "closed loop control active" 0 "open loop control active" ;
VAL_ 2364548094 Aftertreatment1SCRSystemState 15 "Not available" 14 "Error" 10 "Service test mode dosing not allowed" 9 "Service test mode dosing allowed" 8 "Diagnosis afterrun" 7 "Shutoff wait for afterrun" 6 "Protect mode against cold defreeze" 5 "Protect mode against heat pressure buildup" 4 "Reserved for future assignment by SAE" 3 "System error pending" 2 "Normal dosing operation" 1 "Preparing dosing readiness wake up prepare to operate wait for start" 0 "Dormant sleep mode" ;
VAL_ 2364548606 Aftrtrtmnt1OtltNH3GsSnsrHterCtrl 3 "Heater off or not available" 2 "Preheat 1" 1 "Preheat 2" 0 "Automatic" ;
VAL_ 2566742270 FailureModeIdentifier1 31 "Not available" 19 "Received network data in error" 18 "Below normal (moderately severe)" 17 "Below normal (least severe)" 16 "Above normal (moderately severe)" 15 "Above normal (least severe)" 14 "Special intstructions" 13 "Out of calibration" 12 "Bad intelligent device" 11 "Root cause not known" 10 "Abnormal rate of change" 9 "Abnormal update rate" 8 "Abnormal frequency" 7 "Mechanical system not responding" 6 "Current above normal" 5 "Current below normal" 4 "Voltage below normal" 3 "Voltage above normal" 2 "Data erratic" 1 "Below normal (most severe)" 0 "Above normal (most severe)" ;
VAL_ 2560687870 PMNTEDeficiencyAreaStatus 3 "NotAvailable" 2 "Reserved" 1 "InsideControlArea" 0 "OutsideControlArea" ;
VAL_ 2560687870 MnfcPMNTECarveOutAreaStatus 3 "NotAvailable" 2 "Reserved" 1 "InsideControlArea" 0 "OutsideControlArea" ;
VAL_ 2560687870 PMNTEControlAreaStatus 3 "NotAvailable" 2 "Reserved" 1 "InsideControlArea" 0 "OutsideControlArea" ;
VAL_ 2560687870 NOxNTEDeficiencyAreaStatus 3 "NotAvailable" 2 "Reserved" 1 "InsideControlArea" 0 "OutsideControlArea" ;
VAL_ 2560687870 MnfcNOxNTECarveOutAreaStatus 3 "NotAvailable" 2 "Reserved" 1 "InsideControlArea" 0 "OutsideControlArea" ;
VAL_ 2560687870 NOxNTEControlAreaStatus 3 "NotAvailable" 2 "Reserved" 1 "InsideControlArea" 0 "OutsideControlArea" ;
VAL_ 2566809342 BatteryMainSwitchHoldState 3 "Dont care/take no action" 2 "Reserved" 1 "Battery main switch held" 0 "Battery main switch not held" ;
